VERSION ""

NS_ :

BS_:

BU_: CAMERA_ALL ALM_DX ALM_SX CAMERA_DEFAULT LOGBOX CAMERA_POS0 CAMERA_POS1 CAMERA_POS2 CAMERA_POS3 CAMERA_POS4 CAMERA_POS5 CAMERA_POS6 CAMERA_POS7 SVS RUR RUF RUC BC _TESTER BMS3_ADB BMS0_ADB BMS4_ADB BMS5_ADB BMS6_ADB

BO_ 2566698659 _BMS3_ADB_VEP_5: 8 BMS3_ADB
 SG_ BMS3_ADB_SLI_BattPack_StOfCharge : 0|16@1+ (0.0025,0) [0|1606375] "%"  LOGBOX
 SG_ BMS3_ADB_SLI_BattPack_Capacity : 16|16@1+ (1,0) [0|64255] "Ah"  LOGBOX
 SG_ BMS3_ADB_SLI_BattPack_Health : 32|8@1+ (0.5,0) [0|100] "%"  LOGBOX

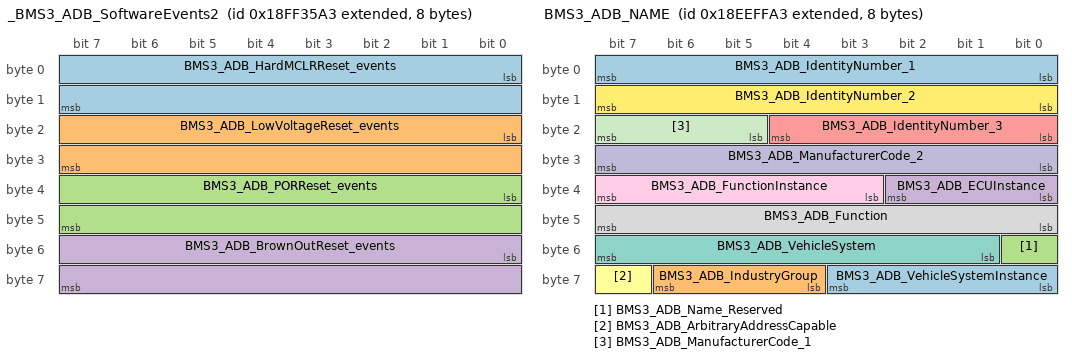
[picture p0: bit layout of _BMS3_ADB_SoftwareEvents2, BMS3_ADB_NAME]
BO_ 2566862243 _BMS3_ADB_SoftwareEvents2: 8 BMS3_ADB
 SG_ BMS3_ADB_HardMCLRReset_events : 0|16@1+ (1,0) [0|64255] "-"  LOGBOX
 SG_ BMS3_ADB_LowVoltageReset_events : 16|16@1+ (1,0) [0|64255] "-"  LOGBOX
 SG_ BMS3_ADB_PORReset_events : 32|16@1+ (1,0) [0|64255] "-"  LOGBOX
 SG_ BMS3_ADB_BrownOutReset_events : 48|16@1+ (1,0) [0|64255] "-"  LOGBOX

BO_ 2565799843 BMS3_ADB_NAME: 8 BMS3_ADB
 SG_ BMS3_ADB_VehicleSystemInstance : 56|4@1+ (1,0) [0|15] "-"  LOGBOX,BC
 SG_ BMS3_ADB_IndustryGroup : 60|3@1+ (1,0) [0|7] "-"  LOGBOX,BC
 SG_ BMS3_ADB_Name_Reserved : 48|1@1+ (1,0) [0|1] "-"  LOGBOX,BC
 SG_ BMS3_ADB_ECUInstance : 32|3@1+ (1,0) [0|7] "-"  LOGBOX,BC
 SG_ BMS3_ADB_IdentityNumber_3 : 16|5@1+ (1,0) [0|31] "-"  LOGBOX,BC
 SG_ BMS3_ADB_ArbitraryAddressCapable : 63|1@1+ (1,0) [0|1] "-"  LOGBOX,BC
 SG_ BMS3_ADB_VehicleSystem : 49|7@1+ (1,0) [0|127] "-"  LOGBOX,BC
 SG_ BMS3_ADB_Function : 40|8@1+ (1,0) [0|255] "-"  LOGBOX,BC
 SG_ BMS3_ADB_FunctionInstance : 35|5@1+ (1,0) [0|31] "-"  LOGBOX,BC
 SG_ BMS3_ADB_ManufacturerCode_2 : 24|8@1+ (1,0) [0|255] "-"  LOGBOX,BC
 SG_ BMS3_ADB_ManufacturerCode_1 : 21|3@1+ (1,0) [0|7] "-"  LOGBOX,BC
 SG_ BMS3_ADB_IdentityNumber_2 : 8|8@1+ (1,0) [0|255] "-"  LOGBOX,BC
 SG_ BMS3_ADB_IdentityNumber_1 : 0|8@1+ (1,0) [0|255] "-"  LOGBOX,BC

BO_ 2566849956 BMS4_ADB_BatterySummaryStatus: 8 BMS4_ADB
 SG_ BMS4_ADB_BatSumS_serial_number : 0|24@1+ (1,0) [0|16777214] "-"  BC,LOGBOX
 SG_ BMS4_ADB_BatSumS_Reserved_01 : 24|8@1+ (1,0) [0|255] "-"  LOGBOX
 SG_ BMS4_ADB_BatSumS_State_of_Charge : 32|8@1+ (1,0) [0|100] "%"  LOGBOX,BC
 SG_ BMS4_ADB_BatSumS_State_of_Health : 40|8@1+ (1,0) [0|2] "-"  LOGBOX,BC
 SG_ BMS4_ADB_BatSumS_Temp_Alarm : 48|2@1+ (1,0) [0|3] "-"  LOGBOX,BC
 SG_ BMS4_ADB_BatSumS_DischargeDis : 50|1@1+ (1,0) [0|1] "-"  LOGBOX,BC
 SG_ BMS4_ADB_BatSumS_ChargingDisable : 51|1@1+ (1,0) [0|1] "-"  LOGBOX,BC
 SG_ BMS4_ADB_BatSumS_HeaterEnabled : 52|1@1+ (1,0) [0|1] "-"  LOGBOX,BC
 SG_ BMS4_ADB_BatSumS_BypassEnabled : 53|1@1+ (1,0) [0|1] "-"  LOGBOX,BC
 SG_ BMS4_ADB_BatSumS_Voltage_Alarm : 56|1@1+ (1,0) [0|1] "-"  LOGBOX,BC
 SG_ BMS4_ADB_BatSumS_Reserved_04 : 54|2@1+ (1,0) [0|3] "-"  LOGBOX
 SG_ BMS4_ADB_BatSumS_Reserved_05 : 57|1@1+ (1,0) [0|1] "-"  LOGBOX,BC
 SG_ BMS4_ADB_BatSumS_Reserved_06 : 58|1@1+ (1,0) [0|1] "-"  LOGBOX
 SG_ BMS4_ADB_BatSumS_Reserved_07 : 59|1@1+ (1,0) [0|1] "-"  LOGBOX
 SG_ BMS4_ADB_BatSumS_Reserved_08 : 60|1@1+ (1,0) [0|1] "-"  LOGBOX
 SG_ BMS4_ADB_BatSumS_Reserved_09 : 61|1@1+ (1,0) [0|1] "-"  LOGBOX
 SG_ BMS4_ADB_BatSumS_Reserved_10 : 62|1@1+ (1,0) [0|1] "-"  LOGBOX
 SG_ BMS4_ADB_BatSumS_Reserved_11 : 63|1@1+ (1,0) [0|1] "-"  LOGBOX

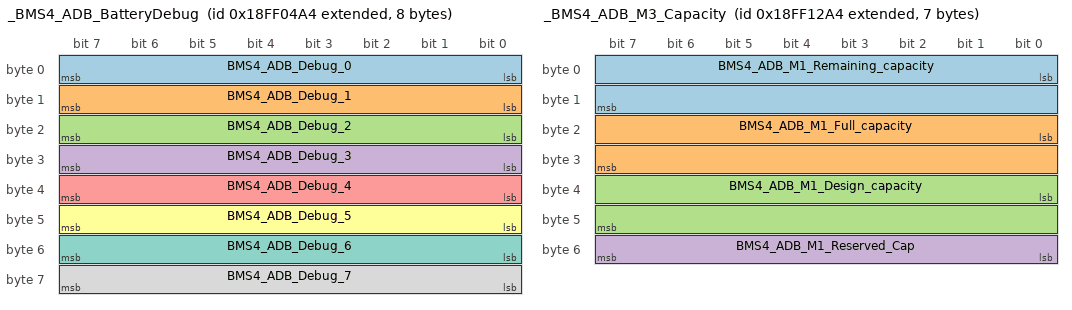
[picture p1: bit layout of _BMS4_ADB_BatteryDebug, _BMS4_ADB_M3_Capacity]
BO_ 2566849700 _BMS4_ADB_BatteryDebug: 8 BMS4_ADB
 SG_ BMS4_ADB_Debug_0 : 0|8@1+ (1,0) [0|255] "-"  LOGBOX
 SG_ BMS4_ADB_Debug_1 : 8|8@1+ (1,0) [0|255] "-"  LOGBOX
 SG_ BMS4_ADB_Debug_2 : 16|8@1+ (1,0) [0|255] "-"  LOGBOX
 SG_ BMS4_ADB_Debug_3 : 24|8@1+ (1,0) [0|255] "-"  LOGBOX
 SG_ BMS4_ADB_Debug_4 : 32|8@1+ (1,0) [0|255] "-"  LOGBOX
 SG_ BMS4_ADB_Debug_5 : 40|8@1+ (1,0) [0|255] "-"  LOGBOX
 SG_ BMS4_ADB_Debug_6 : 48|8@1+ (1,0) [0|255] "-"  LOGBOX
 SG_ BMS4_ADB_Debug_7 : 56|8@1+ (1,0) [0|255] "-"  LOGBOX

BO_ 2566853284 _BMS4_ADB_M3_Capacity: 7 BMS4_ADB
 SG_ BMS4_ADB_M1_Remaining_capacity : 0|16@1+ (0.01,0) [0|642.55] "Ah"  LOGBOX
 SG_ BMS4_ADB_M1_Full_capacity : 16|16@1+ (0.01,0) [0|642.55] "Ah"  LOGBOX
 SG_ BMS4_ADB_M1_Design_capacity : 32|16@1+ (0.01,0) [0|642.55] "Ah"  LOGBOX
 SG_ BMS4_ADB_M1_Reserved_Cap : 48|8@1+ (1,0) [255|255] "-"  LOGBOX

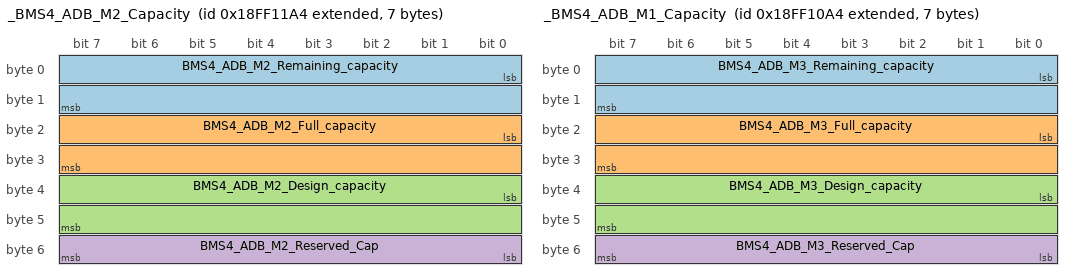
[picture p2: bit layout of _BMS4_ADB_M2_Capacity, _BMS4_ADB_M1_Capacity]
BO_ 2566853028 _BMS4_ADB_M2_Capacity: 7 BMS4_ADB
 SG_ BMS4_ADB_M2_Remaining_capacity : 0|16@1+ (0.01,0) [0|642.55] "Ah"  LOGBOX
 SG_ BMS4_ADB_M2_Full_capacity : 16|16@1+ (0.01,0) [0|642.55] "Ah"  LOGBOX
 SG_ BMS4_ADB_M2_Design_capacity : 32|16@1+ (0.01,0) [0|642.55] "Ah"  LOGBOX
 SG_ BMS4_ADB_M2_Reserved_Cap : 48|8@1+ (1,0) [255|255] "-"  LOGBOX

BO_ 2566852772 _BMS4_ADB_M1_Capacity: 7 BMS4_ADB
 SG_ BMS4_ADB_M3_Remaining_capacity : 0|16@1+ (0.01,0) [0|642.55] "Ah"  LOGBOX
 SG_ BMS4_ADB_M3_Full_capacity : 16|16@1+ (0.01,0) [0|642.55] "Ah"  LOGBOX
 SG_ BMS4_ADB_M3_Design_capacity : 32|16@1+ (0.01,0) [0|642.55] "Ah"  LOGBOX
 SG_ BMS4_ADB_M3_Reserved_Cap : 48|8@1+ (1,0) [255|255] "-"  LOGBOX

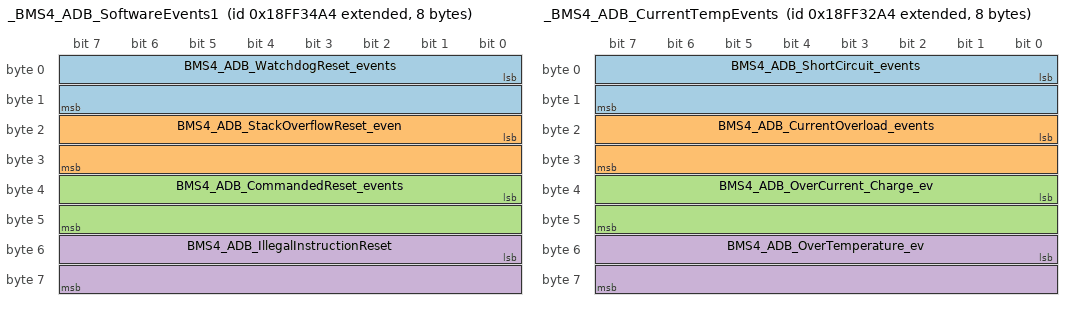
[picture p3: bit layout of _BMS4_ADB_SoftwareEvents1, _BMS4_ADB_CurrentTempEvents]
BO_ 2566861988 _BMS4_ADB_SoftwareEvents1: 8 BMS4_ADB
 SG_ BMS4_ADB_WatchdogReset_events : 0|16@1+ (1,0) [0|64255] "-"  LOGBOX
 SG_ BMS4_ADB_StackOverflowReset_even : 16|16@1+ (1,0) [0|64255] "-"  LOGBOX
 SG_ BMS4_ADB_CommandedReset_events : 32|16@1+ (1,0) [0|64255] "-"  LOGBOX
 SG_ BMS4_ADB_IllegalInstructionReset : 48|16@1+ (1,0) [0|64255] "-"  LOGBOX

BO_ 2566861732 _BMS4_ADB_VoltageEvents: 4 BMS4_ADB
 SG_ BMS4_ADB_OverVoltage_events : 0|16@1+ (1,0) [0|64255] "-"  LOGBOX
 SG_ BMS4_ADB_UnderVoltage_events : 16|16@1+ (1,0) [0|64255] "-"  LOGBOX

BO_ 2566861476 _BMS4_ADB_CurrentTempEvents: 8 BMS4_ADB
 SG_ BMS4_ADB_ShortCircuit_events : 0|16@1+ (1,0) [0|64255] "-"  LOGBOX
 SG_ BMS4_ADB_CurrentOverload_events : 16|16@1+ (1,0) [0|64255] "-"  LOGBOX
 SG_ BMS4_ADB_OverCurrent_Charge_ev : 32|16@1+ (1,0) [0|64255] "-"  LOGBOX
 SG_ BMS4_ADB_OverTemperature_ev : 48|16@1+ (1,0) [0|64255] "-"  LOGBOX

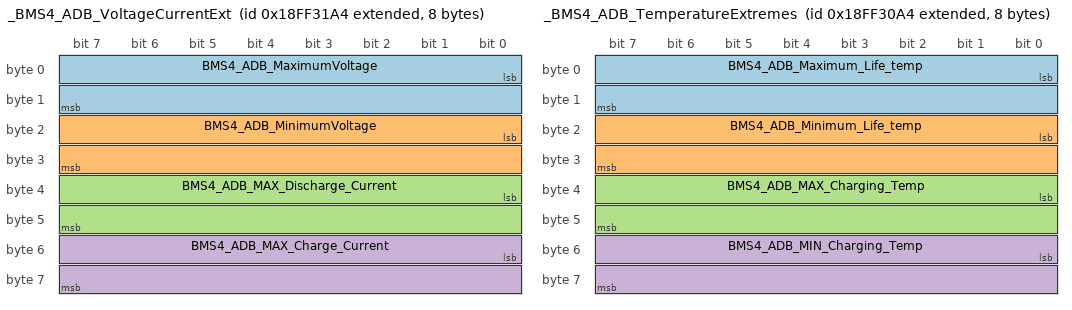
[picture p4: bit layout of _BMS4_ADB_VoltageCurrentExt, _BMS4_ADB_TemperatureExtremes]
BO_ 2566861220 _BMS4_ADB_VoltageCurrentExt: 8 BMS4_ADB
 SG_ BMS4_ADB_MaximumVoltage : 0|16@1+ (0.001,0) [0|64255] "V"  LOGBOX
 SG_ BMS4_ADB_MinimumVoltage : 16|16@1+ (0.001,0) [0|64255] "V"  LOGBOX
 SG_ BMS4_ADB_MAX_Discharge_Current : 32|16@1+ (0.1,0) [0|6425.5] "A"  LOGBOX
 SG_ BMS4_ADB_MAX_Charge_Current : 48|16@1+ (0.1,0) [0|6425.5] "A"  LOGBOX

BO_ 2566860964 _BMS4_ADB_TemperatureExtremes: 8 BMS4_ADB
 SG_ BMS4_ADB_Maximum_Life_temp : 0|16@1+ (0.1,-100) [-100|200] "°C"  LOGBOX
 SG_ BMS4_ADB_Minimum_Life_temp : 16|16@1+ (0.1,-100) [-100|200] "°C"  LOGBOX
 SG_ BMS4_ADB_MAX_Charging_Temp : 32|16@1+ (0.1,-100) [-100|200] "°C"  LOGBOX
 SG_ BMS4_ADB_MIN_Charging_Temp : 48|16@1+ (0.1,-100) [-100|200] "°C"  LOGBOX

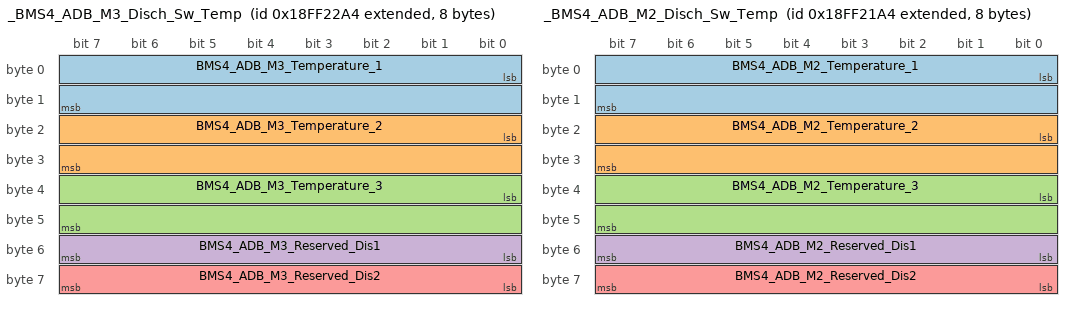
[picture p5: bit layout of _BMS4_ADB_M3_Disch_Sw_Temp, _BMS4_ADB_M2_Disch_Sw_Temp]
BO_ 2566857380 _BMS4_ADB_M3_Disch_Sw_Temp: 8 BMS4_ADB
 SG_ BMS4_ADB_M3_Temperature_1 : 0|16@1+ (0.1,-100) [-100|200] "°C"  LOGBOX
 SG_ BMS4_ADB_M3_Temperature_2 : 16|16@1+ (0.1,-100) [-100|200] "°C"  LOGBOX
 SG_ BMS4_ADB_M3_Temperature_3 : 32|16@1+ (0.1,-100) [-100|200] "°C"  LOGBOX
 SG_ BMS4_ADB_M3_Reserved_Dis1 : 48|8@1+ (1,0) [255|255] "-"  LOGBOX
 SG_ BMS4_ADB_M3_Reserved_Dis2 : 56|8@1+ (1,0) [255|255] "-"  LOGBOX

BO_ 2566857124 _BMS4_ADB_M2_Disch_Sw_Temp: 8 BMS4_ADB
 SG_ BMS4_ADB_M2_Temperature_1 : 0|16@1+ (0.1,-100) [-100|200] "°C"  LOGBOX
 SG_ BMS4_ADB_M2_Temperature_2 : 16|16@1+ (0.1,-100) [-100|200] "°C"  LOGBOX
 SG_ BMS4_ADB_M2_Temperature_3 : 32|16@1+ (0.1,-100) [-100|200] "°C"  LOGBOX
 SG_ BMS4_ADB_M2_Reserved_Dis1 : 48|8@1+ (1,0) [255|255] "-"  LOGBOX
 SG_ BMS4_ADB_M2_Reserved_Dis2 : 56|8@1+ (1,0) [255|255] "-"  LOGBOX

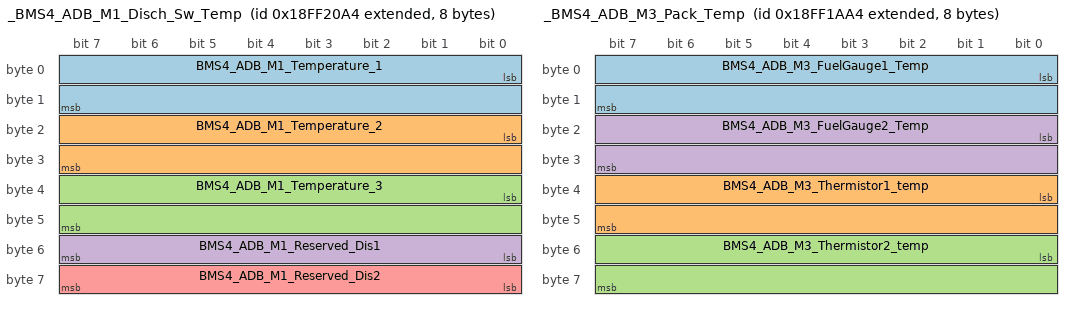
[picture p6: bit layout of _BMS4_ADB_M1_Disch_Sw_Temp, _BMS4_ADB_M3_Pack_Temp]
BO_ 2566856868 _BMS4_ADB_M1_Disch_Sw_Temp: 8 BMS4_ADB
 SG_ BMS4_ADB_M1_Temperature_1 : 0|16@1+ (0.1,-100) [-100|200] "°C"  LOGBOX
 SG_ BMS4_ADB_M1_Temperature_2 : 16|16@1+ (0.1,-100) [-100|200] "°C"  LOGBOX
 SG_ BMS4_ADB_M1_Temperature_3 : 32|16@1+ (0.1,-100) [-100|200] "°C"  LOGBOX
 SG_ BMS4_ADB_M1_Reserved_Dis1 : 48|8@1+ (1,0) [255|255] "-"  LOGBOX
 SG_ BMS4_ADB_M1_Reserved_Dis2 : 56|8@1+ (1,0) [255|255] "-"  LOGBOX

BO_ 2566855332 _BMS4_ADB_M3_Pack_Temp: 8 BMS4_ADB
 SG_ BMS4_ADB_M3_FuelGauge1_Temp : 0|16@1+ (0.1,-100) [-100|200] "°C"  LOGBOX
 SG_ BMS4_ADB_M3_Thermistor1_temp : 32|16@1+ (0.1,-100) [-100|200] "-"  LOGBOX
 SG_ BMS4_ADB_M3_Thermistor2_temp : 48|16@1+ (0.1,-100) [-100|200] "-"  LOGBOX
 SG_ BMS4_ADB_M3_FuelGauge2_Temp : 16|16@1+ (0.1,-100) [-100|200] "°C"  LOGBOX

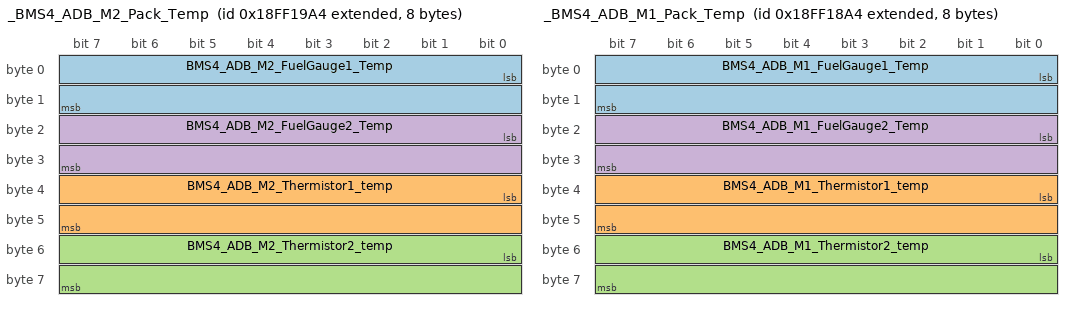
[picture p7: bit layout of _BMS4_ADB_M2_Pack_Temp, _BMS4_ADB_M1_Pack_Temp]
BO_ 2566855076 _BMS4_ADB_M2_Pack_Temp: 8 BMS4_ADB
 SG_ BMS4_ADB_M2_FuelGauge1_Temp : 0|16@1+ (0.1,-100) [-100|200] "°C"  LOGBOX
 SG_ BMS4_ADB_M2_Thermistor1_temp : 32|16@1+ (0.1,-100) [-100|200] "-"  LOGBOX
 SG_ BMS4_ADB_M2_Thermistor2_temp : 48|16@1+ (0.1,-100) [-100|200] "-"  LOGBOX
 SG_ BMS4_ADB_M2_FuelGauge2_Temp : 16|16@1+ (0.1,-100) [-100|200] "°C"  LOGBOX

BO_ 2566854820 _BMS4_ADB_M1_Pack_Temp: 8 BMS4_ADB
 SG_ BMS4_ADB_M1_FuelGauge1_Temp : 0|16@1+ (0.1,-100) [-100|200] "°C"  LOGBOX
 SG_ BMS4_ADB_M1_Thermistor1_temp : 32|16@1+ (0.1,-100) [-100|200] "-"  LOGBOX
 SG_ BMS4_ADB_M1_Thermistor2_temp : 48|16@1+ (0.1,-100) [-100|200] "-"  LOGBOX
 SG_ BMS4_ADB_M1_FuelGauge2_Temp : 16|16@1+ (0.1,-100) [-100|200] "°C"  LOGBOX

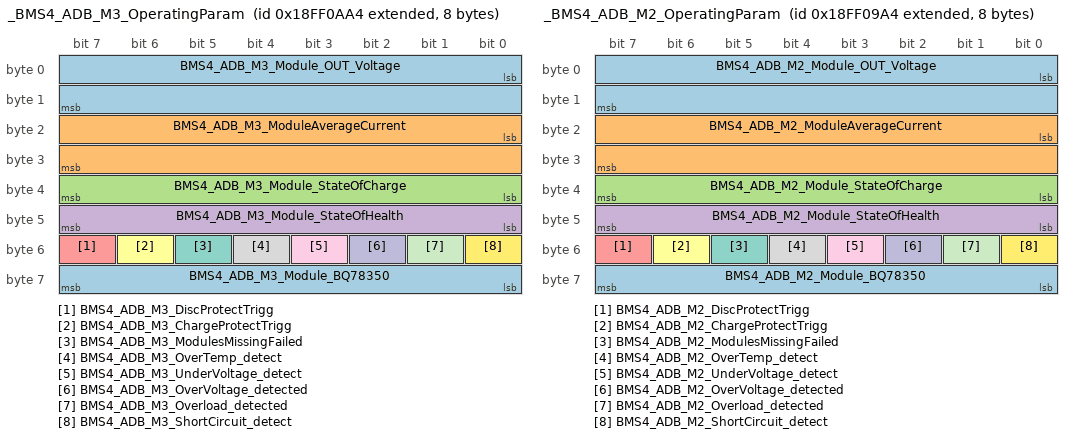
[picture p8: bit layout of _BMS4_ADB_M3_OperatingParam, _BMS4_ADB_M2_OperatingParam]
BO_ 2566851236 _BMS4_ADB_M3_OperatingParam: 8 BMS4_ADB
 SG_ BMS4_ADB_M3_Module_OUT_Voltage : 0|16@1+ (0.001,0) [0|64255] "V"  LOGBOX
 SG_ BMS4_ADB_M3_ModuleAverageCurrent : 16|16@1+ (0.1,-5500) [-5500|925.5] "A"  LOGBOX
 SG_ BMS4_ADB_M3_Module_StateOfCharge : 32|8@1+ (1,0) [0|100] "%"  LOGBOX
 SG_ BMS4_ADB_M3_Module_StateOfHealth : 40|8@1+ (1,0) [0|2] "-"  LOGBOX
 SG_ BMS4_ADB_M3_DiscProtectTrigg : 55|1@1+ (1,0) [0|1] "-"  LOGBOX
 SG_ BMS4_ADB_M3_ChargeProtectTrigg : 54|1@1+ (1,0) [0|1] "-"  LOGBOX
 SG_ BMS4_ADB_M3_ModulesMissingFailed : 53|1@1+ (1,0) [0|1] "-"  LOGBOX
 SG_ BMS4_ADB_M3_OverTemp_detect : 52|1@1+ (1,0) [0|1] "-"  LOGBOX
 SG_ BMS4_ADB_M3_UnderVoltage_detect : 51|1@1+ (1,0) [0|1] "-"  LOGBOX
 SG_ BMS4_ADB_M3_OverVoltage_detected : 50|1@1+ (1,0) [0|1] "-"  LOGBOX
 SG_ BMS4_ADB_M3_Overload_detected : 49|1@1+ (1,0) [0|1] "-"  LOGBOX
 SG_ BMS4_ADB_M3_ShortCircuit_detect : 48|1@1+ (1,0) [0|1] "-"  LOGBOX
 SG_ BMS4_ADB_M3_Module_BQ78350 : 56|8@1+ (1,0) [0|2] "-"  LOGBOX

BO_ 2566850980 _BMS4_ADB_M2_OperatingParam: 8 BMS4_ADB
 SG_ BMS4_ADB_M2_Module_OUT_Voltage : 0|16@1+ (0.001,0) [0|64255] "V"  LOGBOX
 SG_ BMS4_ADB_M2_ModuleAverageCurrent : 16|16@1+ (0.1,-5500) [-5500|925.5] "A"  LOGBOX
 SG_ BMS4_ADB_M2_Module_StateOfCharge : 32|8@1+ (1,0) [0|100] "%"  LOGBOX
 SG_ BMS4_ADB_M2_Module_StateOfHealth : 40|8@1+ (1,0) [0|2] "-"  LOGBOX
 SG_ BMS4_ADB_M2_DiscProtectTrigg : 55|1@1+ (1,0) [0|1] "-"  LOGBOX
 SG_ BMS4_ADB_M2_ChargeProtectTrigg : 54|1@1+ (1,0) [0|1] "-"  LOGBOX
 SG_ BMS4_ADB_M2_ModulesMissingFailed : 53|1@1+ (1,0) [0|1] "-"  LOGBOX
 SG_ BMS4_ADB_M2_OverTemp_detect : 52|1@1+ (1,0) [0|1] "-"  LOGBOX
 SG_ BMS4_ADB_M2_UnderVoltage_detect : 51|1@1+ (1,0) [0|1] "-"  LOGBOX
 SG_ BMS4_ADB_M2_OverVoltage_detected : 50|1@1+ (1,0) [0|1] "-"  LOGBOX
 SG_ BMS4_ADB_M2_Overload_detected : 49|1@1+ (1,0) [0|1] "-"  LOGBOX
 SG_ BMS4_ADB_M2_ShortCircuit_detect : 48|1@1+ (1,0) [0|1] "-"  LOGBOX
 SG_ BMS4_ADB_M2_Module_BQ78350 : 56|8@1+ (1,0) [0|2] "-"  LOGBOX

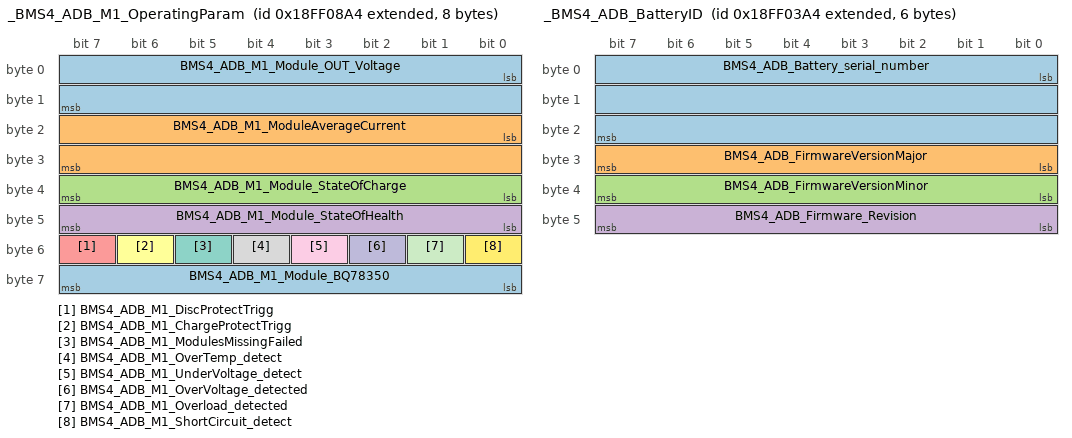
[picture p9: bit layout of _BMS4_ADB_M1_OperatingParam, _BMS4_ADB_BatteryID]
BO_ 2566850724 _BMS4_ADB_M1_OperatingParam: 8 BMS4_ADB
 SG_ BMS4_ADB_M1_Module_OUT_Voltage : 0|16@1+ (0.001,0) [0|64255] "V"  LOGBOX
 SG_ BMS4_ADB_M1_ModuleAverageCurrent : 16|16@1+ (0.1,-5500) [-5500|925.5] "A"  LOGBOX
 SG_ BMS4_ADB_M1_Module_StateOfCharge : 32|8@1+ (1,0) [0|100] "%"  LOGBOX
 SG_ BMS4_ADB_M1_Module_StateOfHealth : 40|8@1+ (1,0) [0|2] "-"  LOGBOX
 SG_ BMS4_ADB_M1_DiscProtectTrigg : 55|1@1+ (1,0) [0|1] "-"  LOGBOX
 SG_ BMS4_ADB_M1_ChargeProtectTrigg : 54|1@1+ (1,0) [0|1] "-"  LOGBOX
 SG_ BMS4_ADB_M1_ModulesMissingFailed : 53|1@1+ (1,0) [0|1] "-"  LOGBOX
 SG_ BMS4_ADB_M1_OverTemp_detect : 52|1@1+ (1,0) [0|1] "-"  LOGBOX
 SG_ BMS4_ADB_M1_UnderVoltage_detect : 51|1@1+ (1,0) [0|1] "-"  LOGBOX
 SG_ BMS4_ADB_M1_OverVoltage_detected : 50|1@1+ (1,0) [0|1] "-"  LOGBOX
 SG_ BMS4_ADB_M1_Overload_detected : 49|1@1+ (1,0) [0|1] "-"  LOGBOX
 SG_ BMS4_ADB_M1_ShortCircuit_detect : 48|1@1+ (1,0) [0|1] "-"  LOGBOX
 SG_ BMS4_ADB_M1_Module_BQ78350 : 56|8@1+ (1,0) [0|2] "-"  LOGBOX

BO_ 2566849444 _BMS4_ADB_BatteryID: 6 BMS4_ADB
 SG_ BMS4_ADB_Battery_serial_number : 0|24@1+ (1,0) [0|16777214] "-"  LOGBOX
 SG_ BMS4_ADB_FirmwareVersionMajor : 24|8@1+ (1,0) [0|255] "-"  LOGBOX
 SG_ BMS4_ADB_FirmwareVersionMinor : 32|8@1+ (1,0) [0|255] "-"  LOGBOX
 SG_ BMS4_ADB_Firmware_Revision : 40|8@1+ (1,0) [0|255] "-"  LOGBOX

BO_ 2566849188 _BMS4_ADB_BatteryTemperature: 6 BMS4_ADB
 SG_ BMS4_ADB_Maximum_Temperature : 0|16@1+ (0.1,-100) [-100|200] "°C"  LOGBOX
 SG_ BMS4_ADB_Minimum_Temperature : 16|16@1+ (0.1,-100) [-100|200] "°C"  LOGBOX
 SG_ BMS4_ADB_Average_Temperature : 32|16@1+ (0.1,-100) [-100|200] "°C"  LOGBOX

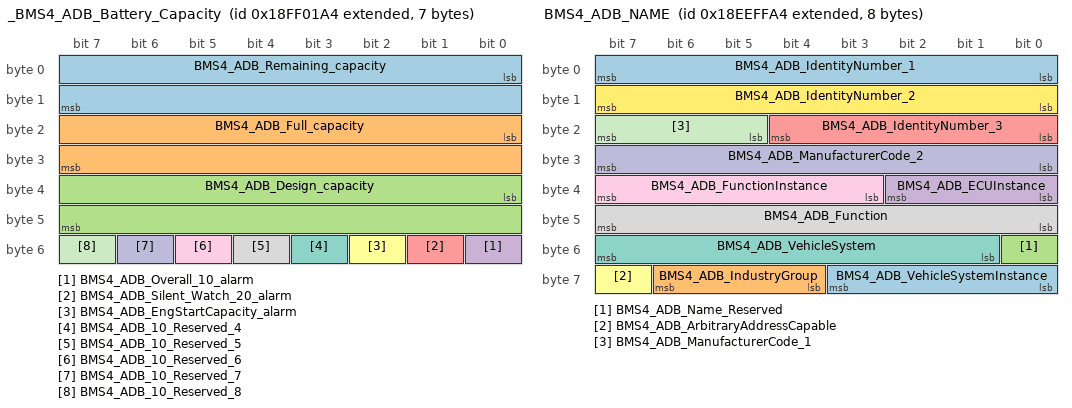
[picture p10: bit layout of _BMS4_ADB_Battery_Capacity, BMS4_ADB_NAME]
BO_ 2566848932 _BMS4_ADB_Battery_Capacity: 7 BMS4_ADB
 SG_ BMS4_ADB_Remaining_capacity : 0|16@1+ (0.01,0) [0|642.55] "Ah"  LOGBOX
 SG_ BMS4_ADB_Full_capacity : 16|16@1+ (0.01,0) [0|642.55] "Ah"  LOGBOX
 SG_ BMS4_ADB_Design_capacity : 32|16@1+ (0.01,0) [0|642.55] "Ah"  LOGBOX
 SG_ BMS4_ADB_Overall_10_alarm : 48|1@1+ (1,0) [0|1] "-"  LOGBOX
 SG_ BMS4_ADB_Silent_Watch_20_alarm : 49|1@1+ (1,0) [0|1] "-"  LOGBOX
 SG_ BMS4_ADB_EngStartCapacity_alarm : 50|1@1+ (1,0) [0|1] "-"  LOGBOX
 SG_ BMS4_ADB_10_Reserved_4 : 51|1@1+ (1,0) [0|0] "-"  LOGBOX
 SG_ BMS4_ADB_10_Reserved_5 : 52|1@1+ (1,0) [0|0] "-"  LOGBOX
 SG_ BMS4_ADB_10_Reserved_6 : 53|1@1+ (1,0) [0|0] "-"  LOGBOX
 SG_ BMS4_ADB_10_Reserved_7 : 54|1@1+ (1,0) [0|0] "-"  LOGBOX
 SG_ BMS4_ADB_10_Reserved_8 : 55|1@1+ (1,0) [0|0] "-"  LOGBOX

BO_ 2566848676 _BMS4_ADB_BatteryOperatingParam: 8 BMS4_ADB
 SG_ BMS4_ADB_Batt_OUT_Voltage : 0|16@1+ (0.001,0) [0|64255] "V"  LOGBOX
 SG_ BMS4_ADB_Batt_Average_Current : 16|16@1+ (0.1,-5500) [-5500|925.5] "A"  LOGBOX
 SG_ BMS4_ADB_Batt_StsOfCharge : 32|8@1+ (1,0) [0|100] "%"  LOGBOX
 SG_ BMS4_ADB_Batt_StsOfHealth : 40|8@1+ (1,0) [0|2] "-"  LOGBOX
 SG_ BMS4_ADB_Batt_PS8_discharge_prot : 55|1@1+ (1,0) [0|1] "-"  LOGBOX
 SG_ BMS4_ADB_Batt_PS7_charge_prot : 54|1@1+ (1,0) [0|1] "-"  LOGBOX
 SG_ BMS4_ADB_Batt_PS6_mod_failed : 53|1@1+ (1,0) [0|1] "-"  LOGBOX
 SG_ BMS4_ADB_Batt_PS5_over_temp : 52|1@1+ (1,0) [0|1] "-"  LOGBOX
 SG_ BMS4_ADB_Batt_PS4_under_voltage : 51|1@1+ (1,0) [0|1] "-"  LOGBOX
 SG_ BMS4_ADB_Batt_PS3_over_voltage : 50|1@1+ (1,0) [0|1] "-"  LOGBOX
 SG_ BMS4_ADB_Batt_PS2_overload : 49|1@1+ (1,0) [0|1] "-"  LOGBOX
 SG_ BMS4_ADB_Batt_PS1_short_circuit : 48|1@1+ (1,0) [0|1] "-"  LOGBOX
 SG_ BMS4_ADB_Batt_OS_8_sleep_mode : 63|1@1+ (1,0) [0|1] "-"  LOGBOX
 SG_ BMS4_ADB_Batt_OS_7_emerg_used : 62|1@1+ (1,0) [0|1] "-"  LOGBOX
 SG_ BMS4_ADB_Batt_OS_6_emergency : 61|1@1+ (1,0) [0|1] "-"  LOGBOX
 SG_ BMS4_ADB_Batt_OS_45_charge_level : 59|2@1+ (1,0) [0|3] "-"  LOGBOX
 SG_ BMS4_ADB_Batt_OS_3_charge_cont : 58|1@1+ (1,0) [0|1] "-"  LOGBOX
 SG_ BMS4_ADB_Batt_OS_2_heater_cont : 57|1@1+ (1,0) [0|1] "-"  LOGBOX
 SG_ BMS4_ADB_Batt_OS_1_master_prot : 56|1@1+ (1,0) [0|1] "-"  LOGBOX

BO_ 2566804132 _BMS4_ADB_VEP_3: 8 BMS4_ADB
 SG_ _nu_BMS4_ADB_AlternatorCurrent : 0|16@1+ (0.05,-1600) [-1600|1612.75] "A"  LOGBOX
 SG_ BMS4_ADB_NetBattery_Current : 16|16@1+ (0.05,-1600) [-1600|1612.75] "A"  LOGBOX

BO_ 2566803620 _BMS4_ADB_Battery_1_Temp: 8 BMS4_ADB
 SG_ BMS4_ADB_Battery1_Temperature : 0|8@1+ (1,-40) [-40|210] "°C"  LOGBOX
 SG_ _nu_BMS4_ADB_Battery2_Temp : 8|8@1+ (1,-40) [-40|210] "°C"  LOGBOX

BO_ 2566698660 _BMS4_ADB_VEP_5: 8 BMS4_ADB
 SG_ BMS4_ADB_SLI_BattPack_StOfCharge : 0|16@1+ (0.0025,0) [0|1606375] "%"  LOGBOX
 SG_ BMS4_ADB_SLI_BattPack_Capacity : 16|16@1+ (1,0) [0|64255] "Ah"  LOGBOX
 SG_ BMS4_ADB_SLI_BattPack_Health : 32|8@1+ (0.5,0) [0|100] "%"  LOGBOX

BO_ 2566862244 _BMS4_ADB_SoftwareEvents2: 8 BMS4_ADB
 SG_ BMS4_ADB_HardMCLRReset_events : 0|16@1+ (1,0) [0|64255] "-"  LOGBOX
 SG_ BMS4_ADB_LowVoltageReset_events : 16|16@1+ (1,0) [0|64255] "-"  LOGBOX
 SG_ BMS4_ADB_PORReset_events : 32|16@1+ (1,0) [0|64255] "-"  LOGBOX
 SG_ BMS4_ADB_BrownOutReset_events : 48|16@1+ (1,0) [0|64255] "-"  LOGBOX

BO_ 2565799844 BMS4_ADB_NAME: 8 BMS4_ADB
 SG_ BMS4_ADB_VehicleSystemInstance : 56|4@1+ (1,0) [0|15] "-"  LOGBOX,BC
 SG_ BMS4_ADB_IndustryGroup : 60|3@1+ (1,0) [0|7] "-"  LOGBOX,BC
 SG_ BMS4_ADB_Name_Reserved : 48|1@1+ (1,0) [0|1] "-"  LOGBOX,BC
 SG_ BMS4_ADB_ECUInstance : 32|3@1+ (1,0) [0|7] "-"  LOGBOX,BC
 SG_ BMS4_ADB_IdentityNumber_3 : 16|5@1+ (1,0) [0|31] "-"  LOGBOX,BC
 SG_ BMS4_ADB_ArbitraryAddressCapable : 63|1@1+ (1,0) [0|1] "-"  LOGBOX,BC
 SG_ BMS4_ADB_VehicleSystem : 49|7@1+ (1,0) [0|127] "-"  LOGBOX,BC
 SG_ BMS4_ADB_Function : 40|8@1+ (1,0) [0|255] "-"  LOGBOX,BC
 SG_ BMS4_ADB_FunctionInstance : 35|5@1+ (1,0) [0|31] "-"  LOGBOX,BC
 SG_ BMS4_ADB_ManufacturerCode_2 : 24|8@1+ (1,0) [0|255] "-"  LOGBOX,BC
 SG_ BMS4_ADB_ManufacturerCode_1 : 21|3@1+ (1,0) [0|7] "-"  LOGBOX,BC
 SG_ BMS4_ADB_IdentityNumber_2 : 8|8@1+ (1,0) [0|255] "-"  LOGBOX,BC
 SG_ BMS4_ADB_IdentityNumber_1 : 0|8@1+ (1,0) [0|255] "-"  LOGBOX,BC

BO_ 2566849957 BMS5_ADB_BatterySummaryStatus: 8 BMS5_ADB
 SG_ BMS5_ADB_BatSumS_serial_number : 0|24@1+ (1,0) [0|16777214] "-"  BC,LOGBOX
 SG_ BMS5_ADB_BatSumS_Reserved_01 : 24|8@1+ (1,0) [0|255] "-"  LOGBOX
 SG_ BMS5_ADB_BatSumS_State_of_Charge : 32|8@1+ (1,0) [0|100] "%"  LOGBOX,BC
 SG_ BMS5_ADB_BatSumS_State_of_Health : 40|8@1+ (1,0) [0|2] "-"  LOGBOX,BC
 SG_ BMS5_ADB_BatSumS_Temp_Alarm : 48|2@1+ (1,0) [0|3] "-"  LOGBOX,BC
 SG_ BMS5_ADB_BatSumS_DischargeDis : 50|1@1+ (1,0) [0|1] "-"  LOGBOX,BC
 SG_ BMS5_ADB_BatSumS_ChargingDisable : 51|1@1+ (1,0) [0|1] "-"  LOGBOX,BC
 SG_ BMS5_ADB_BatSumS_HeaterEnabled : 52|1@1+ (1,0) [0|1] "-"  LOGBOX,BC
 SG_ BMS5_ADB_BatSumS_BypassEnabled : 53|1@1+ (1,0) [0|1] "-"  LOGBOX,BC
 SG_ BMS5_ADB_BatSumS_Voltage_Alarm : 56|1@1+ (1,0) [0|1] "-"  LOGBOX,BC
 SG_ BMS5_ADB_BatSumS_Reserved_04 : 54|2@1+ (1,0) [0|3] "-"  LOGBOX
 SG_ BMS5_ADB_BatSumS_Reserved_05 : 57|1@1+ (1,0) [0|1] "-"  LOGBOX,BC
 SG_ BMS5_ADB_BatSumS_Reserved_06 : 58|1@1+ (1,0) [0|1] "-"  LOGBOX
 SG_ BMS5_ADB_BatSumS_Reserved_07 : 59|1@1+ (1,0) [0|1] "-"  LOGBOX
 SG_ BMS5_ADB_BatSumS_Reserved_08 : 60|1@1+ (1,0) [0|1] "-"  LOGBOX
 SG_ BMS5_ADB_BatSumS_Reserved_09 : 61|1@1+ (1,0) [0|1] "-"  LOGBOX
 SG_ BMS5_ADB_BatSumS_Reserved_10 : 62|1@1+ (1,0) [0|1] "-"  LOGBOX
 SG_ BMS5_ADB_BatSumS_Reserved_11 : 63|1@1+ (1,0) [0|1] "-"  LOGBOX

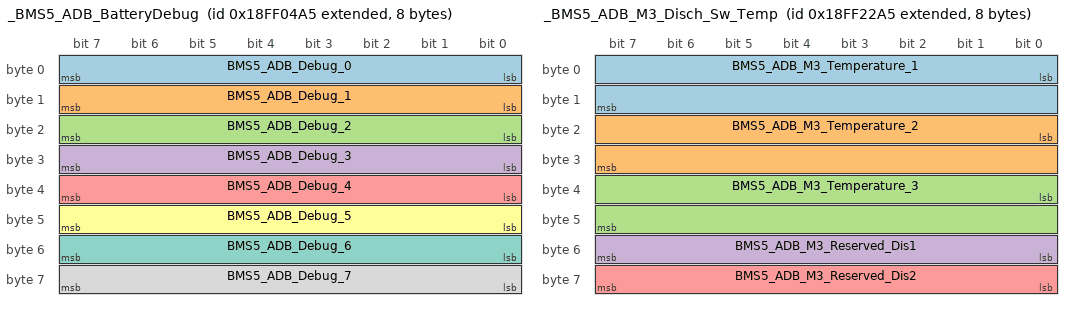
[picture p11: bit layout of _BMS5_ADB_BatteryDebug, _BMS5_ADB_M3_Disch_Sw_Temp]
BO_ 2566849701 _BMS5_ADB_BatteryDebug: 8 BMS5_ADB
 SG_ BMS5_ADB_Debug_0 : 0|8@1+ (1,0) [0|255] "-"  LOGBOX
 SG_ BMS5_ADB_Debug_1 : 8|8@1+ (1,0) [0|255] "-"  LOGBOX
 SG_ BMS5_ADB_Debug_2 : 16|8@1+ (1,0) [0|255] "-"  LOGBOX
 SG_ BMS5_ADB_Debug_3 : 24|8@1+ (1,0) [0|255] "-"  LOGBOX
 SG_ BMS5_ADB_Debug_4 : 32|8@1+ (1,0) [0|255] "-"  LOGBOX
 SG_ BMS5_ADB_Debug_5 : 40|8@1+ (1,0) [0|255] "-"  LOGBOX
 SG_ BMS5_ADB_Debug_6 : 48|8@1+ (1,0) [0|255] "-"  LOGBOX
 SG_ BMS5_ADB_Debug_7 : 56|8@1+ (1,0) [0|255] "-"  LOGBOX

BO_ 2566853285 _BMS5_ADB_M3_Capacity: 7 BMS5_ADB
 SG_ BMS5_ADB_M1_Remaining_capacity : 0|16@1+ (0.01,0) [0|642.55] "Ah"  LOGBOX
 SG_ BMS5_ADB_M1_Full_capacity : 16|16@1+ (0.01,0) [0|642.55] "Ah"  LOGBOX
 SG_ BMS5_ADB_M1_Design_capacity : 32|16@1+ (0.01,0) [0|642.55] "Ah"  LOGBOX
 SG_ BMS5_ADB_M1_Reserved_Cap : 48|8@1+ (1,0) [255|255] "-"  LOGBOX

BO_ 2566853029 _BMS5_ADB_M2_Capacity: 7 BMS5_ADB
 SG_ BMS5_ADB_M2_Remaining_capacity : 0|16@1+ (0.01,0) [0|642.55] "Ah"  LOGBOX
 SG_ BMS5_ADB_M2_Full_capacity : 16|16@1+ (0.01,0) [0|642.55] "Ah"  LOGBOX
 SG_ BMS5_ADB_M2_Design_capacity : 32|16@1+ (0.01,0) [0|642.55] "Ah"  LOGBOX
 SG_ BMS5_ADB_M2_Reserved_Cap : 48|8@1+ (1,0) [255|255] "-"  LOGBOX

BO_ 2566852773 _BMS5_ADB_M1_Capacity: 7 BMS5_ADB
 SG_ BMS5_ADB_M3_Remaining_capacity : 0|16@1+ (0.01,0) [0|642.55] "Ah"  LOGBOX
 SG_ BMS5_ADB_M3_Full_capacity : 16|16@1+ (0.01,0) [0|642.55] "Ah"  LOGBOX
 SG_ BMS5_ADB_M3_Design_capacity : 32|16@1+ (0.01,0) [0|642.55] "Ah"  LOGBOX
 SG_ BMS5_ADB_M3_Reserved_Cap : 48|8@1+ (1,0) [255|255] "-"  LOGBOX

BO_ 2566861989 _BMS5_ADB_SoftwareEvents1: 8 BMS5_ADB
 SG_ BMS5_ADB_WatchdogReset_events : 0|16@1+ (1,0) [0|64255] "-"  LOGBOX
 SG_ BMS5_ADB_StackOverflowReset_even : 16|16@1+ (1,0) [0|64255] "-"  LOGBOX
 SG_ BMS5_ADB_CommandedReset_events : 32|16@1+ (1,0) [0|64255] "-"  LOGBOX
 SG_ BMS5_ADB_IllegalInstructionReset : 48|16@1+ (1,0) [0|64255] "-"  LOGBOX

BO_ 2566861733 _BMS5_ADB_VoltageEvents: 4 BMS5_ADB
 SG_ BMS5_ADB_OverVoltage_events : 0|16@1+ (1,0) [0|64255] "-"  LOGBOX
 SG_ BMS5_ADB_UnderVoltage_events : 16|16@1+ (1,0) [0|64255] "-"  LOGBOX

BO_ 2566861477 _BMS5_ADB_CurrentTempEvents: 8 BMS5_ADB
 SG_ BMS5_ADB_ShortCircuit_events : 0|16@1+ (1,0) [0|64255] "-"  LOGBOX
 SG_ BMS5_ADB_CurrentOverload_events : 16|16@1+ (1,0) [0|64255] "-"  LOGBOX
 SG_ BMS5_ADB_OverCurrent_Charge_ev : 32|16@1+ (1,0) [0|64255] "-"  LOGBOX
 SG_ BMS5_ADB_OverTemperature_ev : 48|16@1+ (1,0) [0|64255] "-"  LOGBOX

BO_ 2566861221 _BMS5_ADB_VoltageCurrentExt: 8 BMS5_ADB
 SG_ BMS5_ADB_MaximumVoltage : 0|16@1+ (0.001,0) [0|64255] "V"  LOGBOX
 SG_ BMS5_ADB_MinimumVoltage : 16|16@1+ (0.001,0) [0|64255] "V"  LOGBOX
 SG_ BMS5_ADB_MAX_Discharge_Current : 32|16@1+ (0.1,0) [0|6425.5] "A"  LOGBOX
 SG_ BMS5_ADB_MAX_Charge_Current : 48|16@1+ (0.1,0) [0|6425.5] "A"  LOGBOX

BO_ 2566860965 _BMS5_ADB_TemperatureExtremes: 8 BMS5_ADB
 SG_ BMS5_ADB_Maximum_Life_temp : 0|16@1+ (0.1,-100) [-100|200] "°C"  LOGBOX
 SG_ BMS5_ADB_Minimum_Life_temp : 16|16@1+ (0.1,-100) [-100|200] "°C"  LOGBOX
 SG_ BMS5_ADB_MAX_Charging_Temp : 32|16@1+ (0.1,-100) [-100|200] "°C"  LOGBOX
 SG_ BMS5_ADB_MIN_Charging_Temp : 48|16@1+ (0.1,-100) [-100|200] "°C"  LOGBOX

BO_ 2566857381 _BMS5_ADB_M3_Disch_Sw_Temp: 8 BMS5_ADB
 SG_ BMS5_ADB_M3_Temperature_1 : 0|16@1+ (0.1,-100) [-100|200] "°C"  LOGBOX
 SG_ BMS5_ADB_M3_Temperature_2 : 16|16@1+ (0.1,-100) [-100|200] "°C"  LOGBOX
 SG_ BMS5_ADB_M3_Temperature_3 : 32|16@1+ (0.1,-100) [-100|200] "°C"  LOGBOX
 SG_ BMS5_ADB_M3_Reserved_Dis1 : 48|8@1+ (1,0) [255|255] "-"  LOGBOX
 SG_ BMS5_ADB_M3_Reserved_Dis2 : 56|8@1+ (1,0) [255|255] "-"  LOGBOX

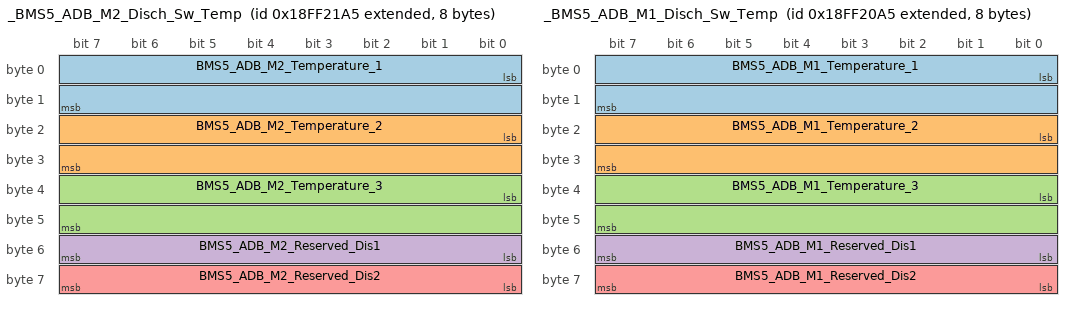
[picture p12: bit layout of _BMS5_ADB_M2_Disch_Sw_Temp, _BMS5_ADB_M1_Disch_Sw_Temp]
BO_ 2566857125 _BMS5_ADB_M2_Disch_Sw_Temp: 8 BMS5_ADB
 SG_ BMS5_ADB_M2_Temperature_1 : 0|16@1+ (0.1,-100) [-100|200] "°C"  LOGBOX
 SG_ BMS5_ADB_M2_Temperature_2 : 16|16@1+ (0.1,-100) [-100|200] "°C"  LOGBOX
 SG_ BMS5_ADB_M2_Temperature_3 : 32|16@1+ (0.1,-100) [-100|200] "°C"  LOGBOX
 SG_ BMS5_ADB_M2_Reserved_Dis1 : 48|8@1+ (1,0) [255|255] "-"  LOGBOX
 SG_ BMS5_ADB_M2_Reserved_Dis2 : 56|8@1+ (1,0) [255|255] "-"  LOGBOX

BO_ 2566856869 _BMS5_ADB_M1_Disch_Sw_Temp: 8 BMS5_ADB
 SG_ BMS5_ADB_M1_Temperature_1 : 0|16@1+ (0.1,-100) [-100|200] "°C"  LOGBOX
 SG_ BMS5_ADB_M1_Temperature_2 : 16|16@1+ (0.1,-100) [-100|200] "°C"  LOGBOX
 SG_ BMS5_ADB_M1_Temperature_3 : 32|16@1+ (0.1,-100) [-100|200] "°C"  LOGBOX
 SG_ BMS5_ADB_M1_Reserved_Dis1 : 48|8@1+ (1,0) [255|255] "-"  LOGBOX
 SG_ BMS5_ADB_M1_Reserved_Dis2 : 56|8@1+ (1,0) [255|255] "-"  LOGBOX

BO_ 2566855333 _BMS5_ADB_M3_Pack_Temp: 8 BMS5_ADB
 SG_ BMS5_ADB_M3_FuelGauge1_Temp : 0|16@1+ (0.1,-100) [-100|200] "°C"  LOGBOX
 SG_ BMS5_ADB_M3_Thermistor1_temp : 32|16@1+ (0.1,-100) [-100|200] "-"  LOGBOX
 SG_ BMS5_ADB_M3_Thermistor2_temp : 48|16@1+ (0.1,-100) [-100|200] "-"  LOGBOX
 SG_ BMS5_ADB_M3_FuelGauge2_Temp : 16|16@1+ (0.1,-100) [-100|200] "°C"  LOGBOX

BO_ 2566855077 _BMS5_ADB_M2_Pack_Temp: 8 BMS5_ADB
 SG_ BMS5_ADB_M2_FuelGauge1_Temp : 0|16@1+ (0.1,-100) [-100|200] "°C"  LOGBOX
 SG_ BMS5_ADB_M2_Thermistor1_temp : 32|16@1+ (0.1,-100) [-100|200] "-"  LOGBOX
 SG_ BMS5_ADB_M2_Thermistor2_temp : 48|16@1+ (0.1,-100) [-100|200] "-"  LOGBOX
 SG_ BMS5_ADB_M2_FuelGauge2_Temp : 16|16@1+ (0.1,-100) [-100|200] "°C"  LOGBOX

BO_ 2566854821 _BMS5_ADB_M1_Pack_Temp: 8 BMS5_ADB
 SG_ BMS5_ADB_M1_FuelGauge1_Temp : 0|16@1+ (0.1,-100) [-100|200] "°C"  LOGBOX
 SG_ BMS5_ADB_M1_Thermistor1_temp : 32|16@1+ (0.1,-100) [-100|200] "-"  LOGBOX
 SG_ BMS5_ADB_M1_Thermistor2_temp : 48|16@1+ (0.1,-100) [-100|200] "-"  LOGBOX
 SG_ BMS5_ADB_M1_FuelGauge2_Temp : 16|16@1+ (0.1,-100) [-100|200] "°C"  LOGBOX

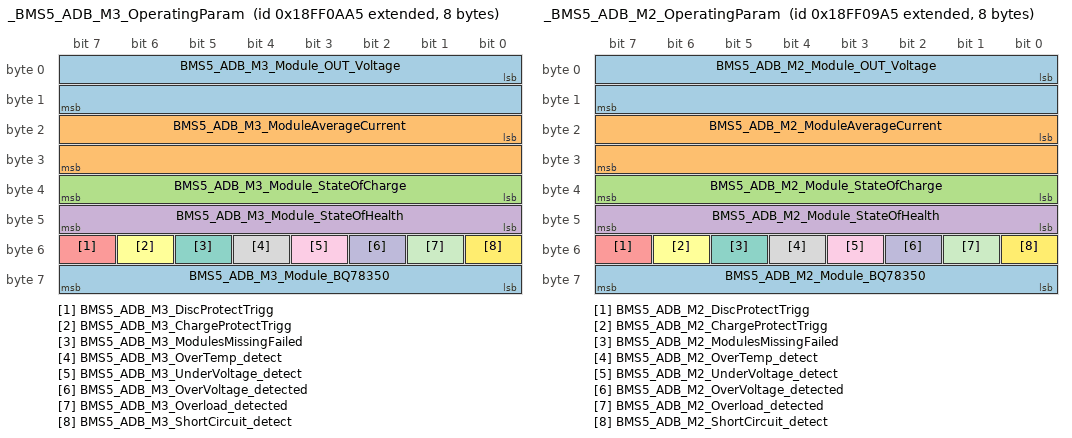
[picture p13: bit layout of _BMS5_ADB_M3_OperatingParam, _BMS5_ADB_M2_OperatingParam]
BO_ 2566851237 _BMS5_ADB_M3_OperatingParam: 8 BMS5_ADB
 SG_ BMS5_ADB_M3_Module_OUT_Voltage : 0|16@1+ (0.001,0) [0|64255] "V"  LOGBOX
 SG_ BMS5_ADB_M3_ModuleAverageCurrent : 16|16@1+ (0.1,-5500) [-5500|925.5] "A"  LOGBOX
 SG_ BMS5_ADB_M3_Module_StateOfCharge : 32|8@1+ (1,0) [0|100] "%"  LOGBOX
 SG_ BMS5_ADB_M3_Module_StateOfHealth : 40|8@1+ (1,0) [0|2] "-"  LOGBOX
 SG_ BMS5_ADB_M3_DiscProtectTrigg : 55|1@1+ (1,0) [0|1] "-"  LOGBOX
 SG_ BMS5_ADB_M3_ChargeProtectTrigg : 54|1@1+ (1,0) [0|1] "-"  LOGBOX
 SG_ BMS5_ADB_M3_ModulesMissingFailed : 53|1@1+ (1,0) [0|1] "-"  LOGBOX
 SG_ BMS5_ADB_M3_OverTemp_detect : 52|1@1+ (1,0) [0|1] "-"  LOGBOX
 SG_ BMS5_ADB_M3_UnderVoltage_detect : 51|1@1+ (1,0) [0|1] "-"  LOGBOX
 SG_ BMS5_ADB_M3_OverVoltage_detected : 50|1@1+ (1,0) [0|1] "-"  LOGBOX
 SG_ BMS5_ADB_M3_Overload_detected : 49|1@1+ (1,0) [0|1] "-"  LOGBOX
 SG_ BMS5_ADB_M3_ShortCircuit_detect : 48|1@1+ (1,0) [0|1] "-"  LOGBOX
 SG_ BMS5_ADB_M3_Module_BQ78350 : 56|8@1+ (1,0) [0|2] "-"  LOGBOX

BO_ 2566850981 _BMS5_ADB_M2_OperatingParam: 8 BMS5_ADB
 SG_ BMS5_ADB_M2_Module_OUT_Voltage : 0|16@1+ (0.001,0) [0|64255] "V"  LOGBOX
 SG_ BMS5_ADB_M2_ModuleAverageCurrent : 16|16@1+ (0.1,-5500) [-5500|925.5] "A"  LOGBOX
 SG_ BMS5_ADB_M2_Module_StateOfCharge : 32|8@1+ (1,0) [0|100] "%"  LOGBOX
 SG_ BMS5_ADB_M2_Module_StateOfHealth : 40|8@1+ (1,0) [0|2] "-"  LOGBOX
 SG_ BMS5_ADB_M2_DiscProtectTrigg : 55|1@1+ (1,0) [0|1] "-"  LOGBOX
 SG_ BMS5_ADB_M2_ChargeProtectTrigg : 54|1@1+ (1,0) [0|1] "-"  LOGBOX
 SG_ BMS5_ADB_M2_ModulesMissingFailed : 53|1@1+ (1,0) [0|1] "-"  LOGBOX
 SG_ BMS5_ADB_M2_OverTemp_detect : 52|1@1+ (1,0) [0|1] "-"  LOGBOX
 SG_ BMS5_ADB_M2_UnderVoltage_detect : 51|1@1+ (1,0) [0|1] "-"  LOGBOX
 SG_ BMS5_ADB_M2_OverVoltage_detected : 50|1@1+ (1,0) [0|1] "-"  LOGBOX
 SG_ BMS5_ADB_M2_Overload_detected : 49|1@1+ (1,0) [0|1] "-"  LOGBOX
 SG_ BMS5_ADB_M2_ShortCircuit_detect : 48|1@1+ (1,0) [0|1] "-"  LOGBOX
 SG_ BMS5_ADB_M2_Module_BQ78350 : 56|8@1+ (1,0) [0|2] "-"  LOGBOX

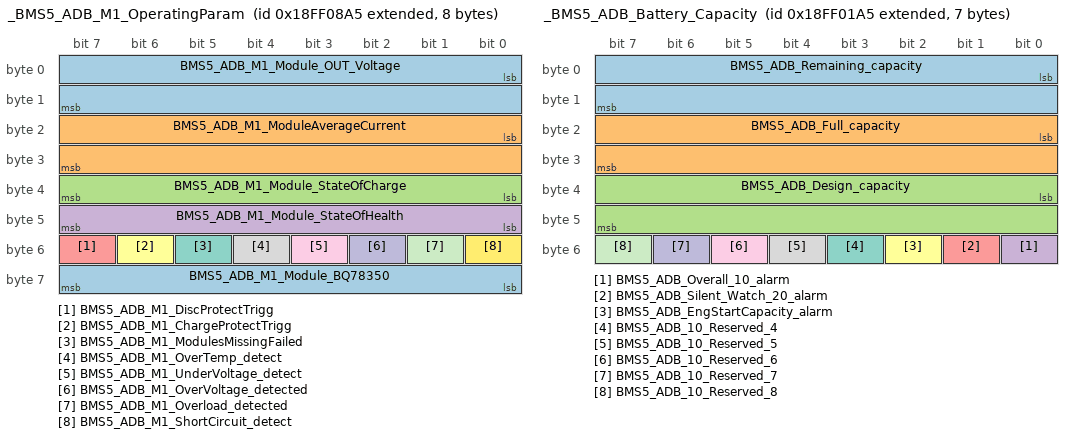
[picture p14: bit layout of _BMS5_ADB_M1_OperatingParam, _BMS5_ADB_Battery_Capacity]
BO_ 2566850725 _BMS5_ADB_M1_OperatingParam: 8 BMS5_ADB
 SG_ BMS5_ADB_M1_Module_OUT_Voltage : 0|16@1+ (0.001,0) [0|64255] "V"  LOGBOX
 SG_ BMS5_ADB_M1_ModuleAverageCurrent : 16|16@1+ (0.1,-5500) [-5500|925.5] "A"  LOGBOX
 SG_ BMS5_ADB_M1_Module_StateOfCharge : 32|8@1+ (1,0) [0|100] "%"  LOGBOX
 SG_ BMS5_ADB_M1_Module_StateOfHealth : 40|8@1+ (1,0) [0|2] "-"  LOGBOX
 SG_ BMS5_ADB_M1_DiscProtectTrigg : 55|1@1+ (1,0) [0|1] "-"  LOGBOX
 SG_ BMS5_ADB_M1_ChargeProtectTrigg : 54|1@1+ (1,0) [0|1] "-"  LOGBOX
 SG_ BMS5_ADB_M1_ModulesMissingFailed : 53|1@1+ (1,0) [0|1] "-"  LOGBOX
 SG_ BMS5_ADB_M1_OverTemp_detect : 52|1@1+ (1,0) [0|1] "-"  LOGBOX
 SG_ BMS5_ADB_M1_UnderVoltage_detect : 51|1@1+ (1,0) [0|1] "-"  LOGBOX
 SG_ BMS5_ADB_M1_OverVoltage_detected : 50|1@1+ (1,0) [0|1] "-"  LOGBOX
 SG_ BMS5_ADB_M1_Overload_detected : 49|1@1+ (1,0) [0|1] "-"  LOGBOX
 SG_ BMS5_ADB_M1_ShortCircuit_detect : 48|1@1+ (1,0) [0|1] "-"  LOGBOX
 SG_ BMS5_ADB_M1_Module_BQ78350 : 56|8@1+ (1,0) [0|2] "-"  LOGBOX

BO_ 2566849445 _BMS5_ADB_BatteryID: 6 BMS5_ADB
 SG_ BMS5_ADB_Battery_serial_number : 0|24@1+ (1,0) [0|16777214] "-"  LOGBOX
 SG_ BMS5_ADB_FirmwareVersionMajor : 24|8@1+ (1,0) [0|255] "-"  LOGBOX
 SG_ BMS5_ADB_FirmwareVersionMinor : 32|8@1+ (1,0) [0|255] "-"  LOGBOX
 SG_ BMS5_ADB_Firmware_Revision : 40|8@1+ (1,0) [0|255] "-"  LOGBOX

BO_ 2566849189 _BMS5_ADB_BatteryTemperature: 6 BMS5_ADB
 SG_ BMS5_ADB_Maximum_Temperature : 0|16@1+ (0.1,-100) [-100|200] "°C"  LOGBOX
 SG_ BMS5_ADB_Minimum_Temperature : 16|16@1+ (0.1,-100) [-100|200] "°C"  LOGBOX
 SG_ BMS5_ADB_Average_Temperature : 32|16@1+ (0.1,-100) [-100|200] "°C"  LOGBOX

BO_ 2566848933 _BMS5_ADB_Battery_Capacity: 7 BMS5_ADB
 SG_ BMS5_ADB_Remaining_capacity : 0|16@1+ (0.01,0) [0|642.55] "Ah"  LOGBOX
 SG_ BMS5_ADB_Full_capacity : 16|16@1+ (0.01,0) [0|642.55] "Ah"  LOGBOX
 SG_ BMS5_ADB_Design_capacity : 32|16@1+ (0.01,0) [0|642.55] "Ah"  LOGBOX
 SG_ BMS5_ADB_Overall_10_alarm : 48|1@1+ (1,0) [0|1] "-"  LOGBOX
 SG_ BMS5_ADB_Silent_Watch_20_alarm : 49|1@1+ (1,0) [0|1] "-"  LOGBOX
 SG_ BMS5_ADB_EngStartCapacity_alarm : 50|1@1+ (1,0) [0|1] "-"  LOGBOX
 SG_ BMS5_ADB_10_Reserved_4 : 51|1@1+ (1,0) [0|0] "-"  LOGBOX
 SG_ BMS5_ADB_10_Reserved_5 : 52|1@1+ (1,0) [0|0] "-"  LOGBOX
 SG_ BMS5_ADB_10_Reserved_6 : 53|1@1+ (1,0) [0|0] "-"  LOGBOX
 SG_ BMS5_ADB_10_Reserved_7 : 54|1@1+ (1,0) [0|0] "-"  LOGBOX
 SG_ BMS5_ADB_10_Reserved_8 : 55|1@1+ (1,0) [0|0] "-"  LOGBOX

BO_ 2566848677 _BMS5_ADB_BatteryOperatingParam: 8 BMS5_ADB
 SG_ BMS5_ADB_Batt_OUT_Voltage : 0|16@1+ (0.001,0) [0|64255] "V"  LOGBOX
 SG_ BMS5_ADB_Batt_Average_Current : 16|16@1+ (0.1,-5500) [-5500|925.5] "A"  LOGBOX
 SG_ BMS5_ADB_Batt_StsOfCharge : 32|8@1+ (1,0) [0|100] "%"  LOGBOX
 SG_ BMS5_ADB_Batt_StsOfHealth : 40|8@1+ (1,0) [0|2] "-"  LOGBOX
 SG_ BMS5_ADB_Batt_PS8_discharge_prot : 55|1@1+ (1,0) [0|1] "-"  LOGBOX
 SG_ BMS5_ADB_Batt_PS7_charge_prot : 54|1@1+ (1,0) [0|1] "-"  LOGBOX
 SG_ BMS5_ADB_Batt_PS6_mod_failed : 53|1@1+ (1,0) [0|1] "-"  LOGBOX
 SG_ BMS5_ADB_Batt_PS5_over_temp : 52|1@1+ (1,0) [0|1] "-"  LOGBOX
 SG_ BMS5_ADB_Batt_PS4_under_voltage : 51|1@1+ (1,0) [0|1] "-"  LOGBOX
 SG_ BMS5_ADB_Batt_PS3_over_voltage : 50|1@1+ (1,0) [0|1] "-"  LOGBOX
 SG_ BMS5_ADB_Batt_PS2_overload : 49|1@1+ (1,0) [0|1] "-"  LOGBOX
 SG_ BMS5_ADB_Batt_PS1_short_circuit : 48|1@1+ (1,0) [0|1] "-"  LOGBOX
 SG_ BMS5_ADB_Batt_OS_8_sleep_mode : 63|1@1+ (1,0) [0|1] "-"  LOGBOX
 SG_ BMS5_ADB_Batt_OS_7_emerg_used : 62|1@1+ (1,0) [0|1] "-"  LOGBOX
 SG_ BMS5_ADB_Batt_OS_6_emergency : 61|1@1+ (1,0) [0|1] "-"  LOGBOX
 SG_ BMS5_ADB_Batt_OS_45_charge_level : 59|2@1+ (1,0) [0|3] "-"  LOGBOX
 SG_ BMS5_ADB_Batt_OS_3_charge_cont : 58|1@1+ (1,0) [0|1] "-"  LOGBOX
 SG_ BMS5_ADB_Batt_OS_2_heater_cont : 57|1@1+ (1,0) [0|1] "-"  LOGBOX
 SG_ BMS5_ADB_Batt_OS_1_master_prot : 56|1@1+ (1,0) [0|1] "-"  LOGBOX

BO_ 2566804133 _BMS5_ADB_VEP_3: 8 BMS5_ADB
 SG_ _nu_BMS5_ADB_AlternatorCurrent : 0|16@1+ (0.05,-1600) [-1600|1612.75] "A"  LOGBOX
 SG_ BMS5_ADB_NetBattery_Current : 16|16@1+ (0.05,-1600) [-1600|1612.75] "A"  LOGBOX

BO_ 2566803621 _BMS5_ADB_Battery_1_Temp: 8 BMS5_ADB
 SG_ BMS5_ADB_Battery1_Temperature : 0|8@1+ (1,-40) [-40|210] "°C"  LOGBOX
 SG_ _nu_BMS5_ADB_Battery2_Temp : 8|8@1+ (1,-40) [-40|210] "°C"  LOGBOX

BO_ 2566698661 _BMS5_ADB_VEP_5: 8 BMS5_ADB
 SG_ BMS5_ADB_SLI_BattPack_StOfCharge : 0|16@1+ (0.0025,0) [0|1606375] "%"  LOGBOX
 SG_ BMS5_ADB_SLI_BattPack_Capacity : 16|16@1+ (1,0) [0|64255] "Ah"  LOGBOX
 SG_ BMS5_ADB_SLI_BattPack_Health : 32|8@1+ (0.5,0) [0|100] "%"  LOGBOX

BO_ 2566862245 _BMS5_ADB_SoftwareEvents2: 8 BMS5_ADB
 SG_ BMS5_ADB_HardMCLRReset_events : 0|16@1+ (1,0) [0|64255] "-"  LOGBOX
 SG_ BMS5_ADB_LowVoltageReset_events : 16|16@1+ (1,0) [0|64255] "-"  LOGBOX
 SG_ BMS5_ADB_PORReset_events : 32|16@1+ (1,0) [0|64255] "-"  LOGBOX
 SG_ BMS5_ADB_BrownOutReset_events : 48|16@1+ (1,0) [0|64255] "-"  LOGBOX

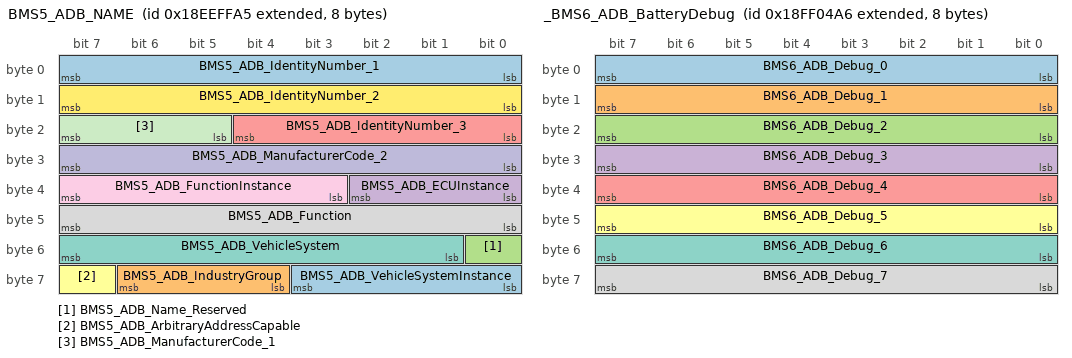
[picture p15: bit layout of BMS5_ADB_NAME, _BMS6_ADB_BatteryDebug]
BO_ 2565799845 BMS5_ADB_NAME: 8 BMS5_ADB
 SG_ BMS5_ADB_VehicleSystemInstance : 56|4@1+ (1,0) [0|15] "-"  LOGBOX,BC
 SG_ BMS5_ADB_IndustryGroup : 60|3@1+ (1,0) [0|7] "-"  LOGBOX,BC
 SG_ BMS5_ADB_Name_Reserved : 48|1@1+ (1,0) [0|1] "-"  LOGBOX,BC
 SG_ BMS5_ADB_ECUInstance : 32|3@1+ (1,0) [0|7] "-"  LOGBOX,BC
 SG_ BMS5_ADB_IdentityNumber_3 : 16|5@1+ (1,0) [0|31] "-"  LOGBOX,BC
 SG_ BMS5_ADB_ArbitraryAddressCapable : 63|1@1+ (1,0) [0|1] "-"  LOGBOX,BC
 SG_ BMS5_ADB_VehicleSystem : 49|7@1+ (1,0) [0|127] "-"  LOGBOX,BC
 SG_ BMS5_ADB_Function : 40|8@1+ (1,0) [0|255] "-"  LOGBOX,BC
 SG_ BMS5_ADB_FunctionInstance : 35|5@1+ (1,0) [0|31] "-"  LOGBOX,BC
 SG_ BMS5_ADB_ManufacturerCode_2 : 24|8@1+ (1,0) [0|255] "-"  LOGBOX,BC
 SG_ BMS5_ADB_ManufacturerCode_1 : 21|3@1+ (1,0) [0|7] "-"  LOGBOX,BC
 SG_ BMS5_ADB_IdentityNumber_2 : 8|8@1+ (1,0) [0|255] "-"  LOGBOX,BC
 SG_ BMS5_ADB_IdentityNumber_1 : 0|8@1+ (1,0) [0|255] "-"  LOGBOX,BC

BO_ 2566849958 BMS6_ADB_BatterySummaryStatus: 8 BMS6_ADB
 SG_ BMS6_ADB_BatSumS_serial_number : 0|24@1+ (1,0) [0|16777214] "-"  BC,LOGBOX
 SG_ BMS6_ADB_BatSumS_Reserved_01 : 24|8@1+ (1,0) [0|255] "-"  LOGBOX
 SG_ BMS6_ADB_BatSumS_State_of_Charge : 32|8@1+ (1,0) [0|100] "%"  LOGBOX,BC
 SG_ BMS6_ADB_BatSumS_State_of_Health : 40|8@1+ (1,0) [0|2] "-"  LOGBOX,BC
 SG_ BMS6_ADB_BatSumS_Temp_Alarm : 48|2@1+ (1,0) [0|3] "-"  LOGBOX,BC
 SG_ BMS6_ADB_BatSumS_DischargeDis : 50|1@1+ (1,0) [0|1] "-"  LOGBOX,BC
 SG_ BMS6_ADB_BatSumS_ChargingDisable : 51|1@1+ (1,0) [0|1] "-"  LOGBOX,BC
 SG_ BMS6_ADB_BatSumS_HeaterEnabled : 52|1@1+ (1,0) [0|1] "-"  LOGBOX,BC
 SG_ BMS6_ADB_BatSumS_BypassEnabled : 53|1@1+ (1,0) [0|1] "-"  LOGBOX,BC
 SG_ BMS6_ADB_BatSumS_Voltage_Alarm : 56|1@1+ (1,0) [0|1] "-"  LOGBOX,BC
 SG_ BMS6_ADB_BatSumS_Reserved_04 : 54|2@1+ (1,0) [0|3] "-"  LOGBOX
 SG_ BMS6_ADB_BatSumS_Reserved_05 : 57|1@1+ (1,0) [0|1] "-"  LOGBOX,BC
 SG_ BMS6_ADB_BatSumS_Reserved_06 : 58|1@1+ (1,0) [0|1] "-"  LOGBOX
 SG_ BMS6_ADB_BatSumS_Reserved_07 : 59|1@1+ (1,0) [0|1] "-"  LOGBOX
 SG_ BMS6_ADB_BatSumS_Reserved_08 : 60|1@1+ (1,0) [0|1] "-"  LOGBOX
 SG_ BMS6_ADB_BatSumS_Reserved_09 : 61|1@1+ (1,0) [0|1] "-"  LOGBOX
 SG_ BMS6_ADB_BatSumS_Reserved_10 : 62|1@1+ (1,0) [0|1] "-"  LOGBOX
 SG_ BMS6_ADB_BatSumS_Reserved_11 : 63|1@1+ (1,0) [0|1] "-"  LOGBOX

BO_ 2566849702 _BMS6_ADB_BatteryDebug: 8 BMS6_ADB
 SG_ BMS6_ADB_Debug_0 : 0|8@1+ (1,0) [0|255] "-"  LOGBOX
 SG_ BMS6_ADB_Debug_1 : 8|8@1+ (1,0) [0|255] "-"  LOGBOX
 SG_ BMS6_ADB_Debug_2 : 16|8@1+ (1,0) [0|255] "-"  LOGBOX
 SG_ BMS6_ADB_Debug_3 : 24|8@1+ (1,0) [0|255] "-"  LOGBOX
 SG_ BMS6_ADB_Debug_4 : 32|8@1+ (1,0) [0|255] "-"  LOGBOX
 SG_ BMS6_ADB_Debug_5 : 40|8@1+ (1,0) [0|255] "-"  LOGBOX
 SG_ BMS6_ADB_Debug_6 : 48|8@1+ (1,0) [0|255] "-"  LOGBOX
 SG_ BMS6_ADB_Debug_7 : 56|8@1+ (1,0) [0|255] "-"  LOGBOX

BO_ 2566853286 _BMS6_ADB_M3_Capacity: 7 BMS6_ADB
 SG_ BMS6_ADB_M1_Remaining_capacity : 0|16@1+ (0.01,0) [0|642.55] "Ah"  LOGBOX
 SG_ BMS6_ADB_M1_Full_capacity : 16|16@1+ (0.01,0) [0|642.55] "Ah"  LOGBOX
 SG_ BMS6_ADB_M1_Design_capacity : 32|16@1+ (0.01,0) [0|642.55] "Ah"  LOGBOX
 SG_ BMS6_ADB_M1_Reserved_Cap : 48|8@1+ (1,0) [255|255] "-"  LOGBOX

BO_ 2566853030 _BMS6_ADB_M2_Capacity: 7 BMS6_ADB
 SG_ BMS6_ADB_M2_Remaining_capacity : 0|16@1+ (0.01,0) [0|642.55] "Ah"  LOGBOX
 SG_ BMS6_ADB_M2_Full_capacity : 16|16@1+ (0.01,0) [0|642.55] "Ah"  LOGBOX
 SG_ BMS6_ADB_M2_Design_capacity : 32|16@1+ (0.01,0) [0|642.55] "Ah"  LOGBOX
 SG_ BMS6_ADB_M2_Reserved_Cap : 48|8@1+ (1,0) [255|255] "-"  LOGBOX

BO_ 2566852774 _BMS6_ADB_M1_Capacity: 7 BMS6_ADB
 SG_ BMS6_ADB_M3_Remaining_capacity : 0|16@1+ (0.01,0) [0|642.55] "Ah"  LOGBOX
 SG_ BMS6_ADB_M3_Full_capacity : 16|16@1+ (0.01,0) [0|642.55] "Ah"  LOGBOX
 SG_ BMS6_ADB_M3_Design_capacity : 32|16@1+ (0.01,0) [0|642.55] "Ah"  LOGBOX
 SG_ BMS6_ADB_M3_Reserved_Cap : 48|8@1+ (1,0) [255|255] "-"  LOGBOX

BO_ 2566861990 _BMS6_ADB_SoftwareEvents1: 8 BMS6_ADB
 SG_ BMS6_ADB_WatchdogReset_events : 0|16@1+ (1,0) [0|64255] "-"  LOGBOX
 SG_ BMS6_ADB_StackOverflowReset_even : 16|16@1+ (1,0) [0|64255] "-"  LOGBOX
 SG_ BMS6_ADB_CommandedReset_events : 32|16@1+ (1,0) [0|64255] "-"  LOGBOX
 SG_ BMS6_ADB_IllegalInstructionReset : 48|16@1+ (1,0) [0|64255] "-"  LOGBOX

BO_ 2566861734 _BMS6_ADB_VoltageEvents: 4 BMS6_ADB
 SG_ BMS6_ADB_OverVoltage_events : 0|16@1+ (1,0) [0|64255] "-"  LOGBOX
 SG_ BMS6_ADB_UnderVoltage_events : 16|16@1+ (1,0) [0|64255] "-"  LOGBOX

BO_ 2566861478 _BMS6_ADB_CurrentTempEvents: 8 BMS6_ADB
 SG_ BMS6_ADB_ShortCircuit_events : 0|16@1+ (1,0) [0|64255] "-"  LOGBOX
 SG_ BMS6_ADB_CurrentOverload_events : 16|16@1+ (1,0) [0|64255] "-"  LOGBOX
 SG_ BMS6_ADB_OverCurrent_Charge_ev : 32|16@1+ (1,0) [0|64255] "-"  LOGBOX
 SG_ BMS6_ADB_OverTemperature_ev : 48|16@1+ (1,0) [0|64255] "-"  LOGBOX

BO_ 2566861222 _BMS6_ADB_VoltageCurrentExt: 8 BMS6_ADB
 SG_ BMS6_ADB_MaximumVoltage : 0|16@1+ (0.001,0) [0|64255] "V"  LOGBOX
 SG_ BMS6_ADB_MinimumVoltage : 16|16@1+ (0.001,0) [0|64255] "V"  LOGBOX
 SG_ BMS6_ADB_MAX_Discharge_Current : 32|16@1+ (0.1,0) [0|6425.5] "A"  LOGBOX
 SG_ BMS6_ADB_MAX_Charge_Current : 48|16@1+ (0.1,0) [0|6425.5] "A"  LOGBOX

BO_ 2566860966 _BMS6_ADB_TemperatureExtremes: 8 BMS6_ADB
 SG_ BMS6_ADB_Maximum_Life_temp : 0|16@1+ (0.1,-100) [-100|200] "°C"  LOGBOX
 SG_ BMS6_ADB_Minimum_Life_temp : 16|16@1+ (0.1,-100) [-100|200] "°C"  LOGBOX
 SG_ BMS6_ADB_MAX_Charging_Temp : 32|16@1+ (0.1,-100) [-100|200] "°C"  LOGBOX
 SG_ BMS6_ADB_MIN_Charging_Temp : 48|16@1+ (0.1,-100) [-100|200] "°C"  LOGBOX

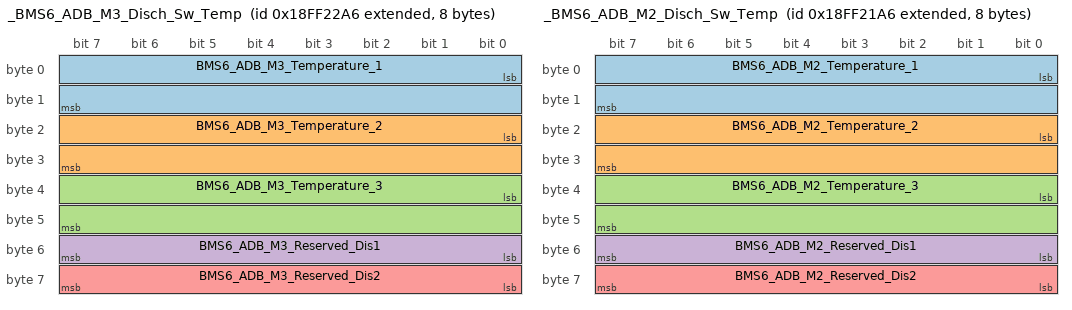
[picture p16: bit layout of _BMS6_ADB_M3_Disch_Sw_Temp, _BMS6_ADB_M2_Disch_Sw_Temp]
BO_ 2566857382 _BMS6_ADB_M3_Disch_Sw_Temp: 8 BMS6_ADB
 SG_ BMS6_ADB_M3_Temperature_1 : 0|16@1+ (0.1,-100) [-100|200] "°C"  LOGBOX
 SG_ BMS6_ADB_M3_Temperature_2 : 16|16@1+ (0.1,-100) [-100|200] "°C"  LOGBOX
 SG_ BMS6_ADB_M3_Temperature_3 : 32|16@1+ (0.1,-100) [-100|200] "°C"  LOGBOX
 SG_ BMS6_ADB_M3_Reserved_Dis1 : 48|8@1+ (1,0) [255|255] "-"  LOGBOX
 SG_ BMS6_ADB_M3_Reserved_Dis2 : 56|8@1+ (1,0) [255|255] "-"  LOGBOX

BO_ 2566857126 _BMS6_ADB_M2_Disch_Sw_Temp: 8 BMS6_ADB
 SG_ BMS6_ADB_M2_Temperature_1 : 0|16@1+ (0.1,-100) [-100|200] "°C"  LOGBOX
 SG_ BMS6_ADB_M2_Temperature_2 : 16|16@1+ (0.1,-100) [-100|200] "°C"  LOGBOX
 SG_ BMS6_ADB_M2_Temperature_3 : 32|16@1+ (0.1,-100) [-100|200] "°C"  LOGBOX
 SG_ BMS6_ADB_M2_Reserved_Dis1 : 48|8@1+ (1,0) [255|255] "-"  LOGBOX
 SG_ BMS6_ADB_M2_Reserved_Dis2 : 56|8@1+ (1,0) [255|255] "-"  LOGBOX

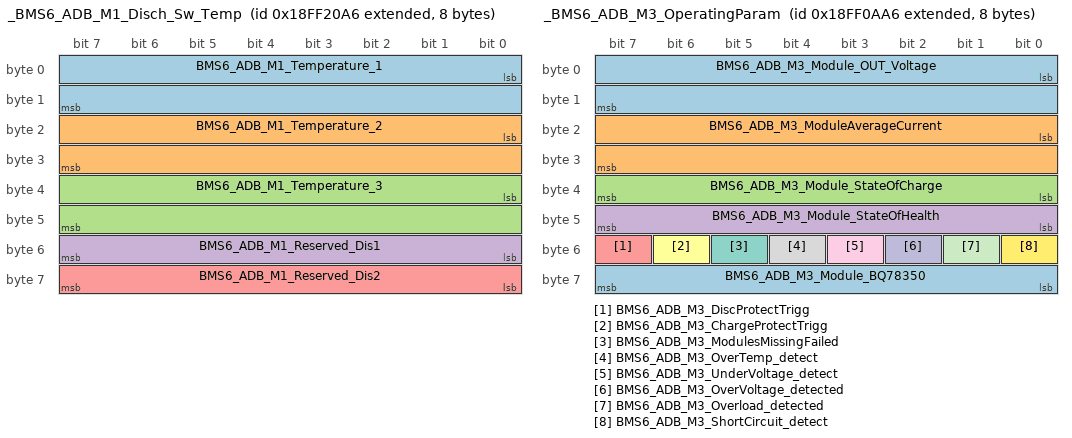
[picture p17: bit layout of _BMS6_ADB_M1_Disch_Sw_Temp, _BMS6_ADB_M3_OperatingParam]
BO_ 2566856870 _BMS6_ADB_M1_Disch_Sw_Temp: 8 BMS6_ADB
 SG_ BMS6_ADB_M1_Temperature_1 : 0|16@1+ (0.1,-100) [-100|200] "°C"  LOGBOX
 SG_ BMS6_ADB_M1_Temperature_2 : 16|16@1+ (0.1,-100) [-100|200] "°C"  LOGBOX
 SG_ BMS6_ADB_M1_Temperature_3 : 32|16@1+ (0.1,-100) [-100|200] "°C"  LOGBOX
 SG_ BMS6_ADB_M1_Reserved_Dis1 : 48|8@1+ (1,0) [255|255] "-"  LOGBOX
 SG_ BMS6_ADB_M1_Reserved_Dis2 : 56|8@1+ (1,0) [255|255] "-"  LOGBOX

BO_ 2566855334 _BMS6_ADB_M3_Pack_Temp: 8 BMS6_ADB
 SG_ BMS6_ADB_M3_FuelGauge1_Temp : 0|16@1+ (0.1,-100) [-100|200] "°C"  LOGBOX
 SG_ BMS6_ADB_M3_Thermistor1_temp : 32|16@1+ (0.1,-100) [-100|200] "-"  LOGBOX
 SG_ BMS6_ADB_M3_Thermistor2_temp : 48|16@1+ (0.1,-100) [-100|200] "-"  LOGBOX
 SG_ BMS6_ADB_M3_FuelGauge2_Temp : 16|16@1+ (0.1,-100) [-100|200] "°C"  LOGBOX

BO_ 2566855078 _BMS6_ADB_M2_Pack_Temp: 8 BMS6_ADB
 SG_ BMS6_ADB_M2_FuelGauge1_Temp : 0|16@1+ (0.1,-100) [-100|200] "°C"  LOGBOX
 SG_ BMS6_ADB_M2_Thermistor1_temp : 32|16@1+ (0.1,-100) [-100|200] "-"  LOGBOX
 SG_ BMS6_ADB_M2_Thermistor2_temp : 48|16@1+ (0.1,-100) [-100|200] "-"  LOGBOX
 SG_ BMS6_ADB_M2_FuelGauge2_Temp : 16|16@1+ (0.1,-100) [-100|200] "°C"  LOGBOX

BO_ 2566854822 _BMS6_ADB_M1_Pack_Temp: 8 BMS6_ADB
 SG_ BMS6_ADB_M1_FuelGauge1_Temp : 0|16@1+ (0.1,-100) [-100|200] "°C"  LOGBOX
 SG_ BMS6_ADB_M1_Thermistor1_temp : 32|16@1+ (0.1,-100) [-100|200] "-"  LOGBOX
 SG_ BMS6_ADB_M1_Thermistor2_temp : 48|16@1+ (0.1,-100) [-100|200] "-"  LOGBOX
 SG_ BMS6_ADB_M1_FuelGauge2_Temp : 16|16@1+ (0.1,-100) [-100|200] "°C"  LOGBOX

BO_ 2566851238 _BMS6_ADB_M3_OperatingParam: 8 BMS6_ADB
 SG_ BMS6_ADB_M3_Module_OUT_Voltage : 0|16@1+ (0.001,0) [0|64255] "V"  LOGBOX
 SG_ BMS6_ADB_M3_ModuleAverageCurrent : 16|16@1+ (0.1,-5500) [-5500|925.5] "A"  LOGBOX
 SG_ BMS6_ADB_M3_Module_StateOfCharge : 32|8@1+ (1,0) [0|100] "%"  LOGBOX
 SG_ BMS6_ADB_M3_Module_StateOfHealth : 40|8@1+ (1,0) [0|2] "-"  LOGBOX
 SG_ BMS6_ADB_M3_DiscProtectTrigg : 55|1@1+ (1,0) [0|1] "-"  LOGBOX
 SG_ BMS6_ADB_M3_ChargeProtectTrigg : 54|1@1+ (1,0) [0|1] "-"  LOGBOX
 SG_ BMS6_ADB_M3_ModulesMissingFailed : 53|1@1+ (1,0) [0|1] "-"  LOGBOX
 SG_ BMS6_ADB_M3_OverTemp_detect : 52|1@1+ (1,0) [0|1] "-"  LOGBOX
 SG_ BMS6_ADB_M3_UnderVoltage_detect : 51|1@1+ (1,0) [0|1] "-"  LOGBOX
 SG_ BMS6_ADB_M3_OverVoltage_detected : 50|1@1+ (1,0) [0|1] "-"  LOGBOX
 SG_ BMS6_ADB_M3_Overload_detected : 49|1@1+ (1,0) [0|1] "-"  LOGBOX
 SG_ BMS6_ADB_M3_ShortCircuit_detect : 48|1@1+ (1,0) [0|1] "-"  LOGBOX
 SG_ BMS6_ADB_M3_Module_BQ78350 : 56|8@1+ (1,0) [0|2] "-"  LOGBOX

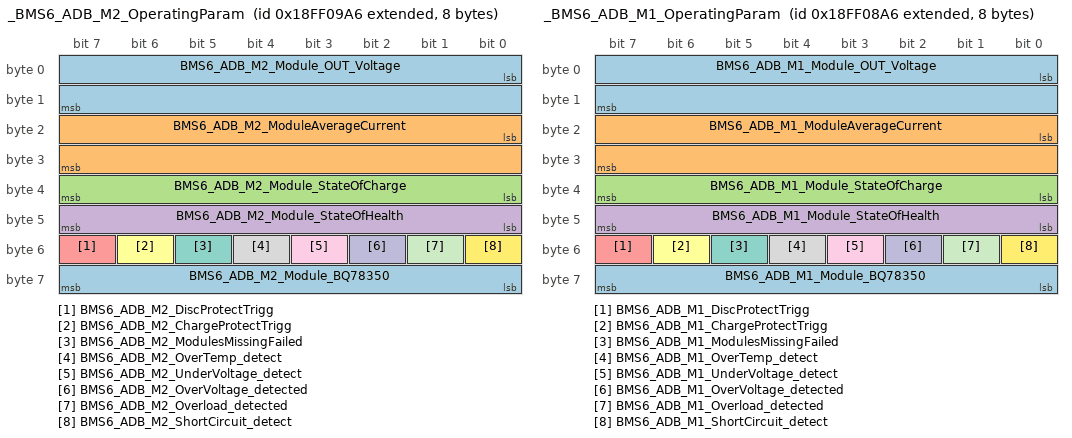
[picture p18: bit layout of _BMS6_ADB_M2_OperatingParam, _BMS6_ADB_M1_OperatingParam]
BO_ 2566850982 _BMS6_ADB_M2_OperatingParam: 8 BMS6_ADB
 SG_ BMS6_ADB_M2_Module_OUT_Voltage : 0|16@1+ (0.001,0) [0|64255] "V"  LOGBOX
 SG_ BMS6_ADB_M2_ModuleAverageCurrent : 16|16@1+ (0.1,-5500) [-5500|925.5] "A"  LOGBOX
 SG_ BMS6_ADB_M2_Module_StateOfCharge : 32|8@1+ (1,0) [0|100] "%"  LOGBOX
 SG_ BMS6_ADB_M2_Module_StateOfHealth : 40|8@1+ (1,0) [0|2] "-"  LOGBOX
 SG_ BMS6_ADB_M2_DiscProtectTrigg : 55|1@1+ (1,0) [0|1] "-"  LOGBOX
 SG_ BMS6_ADB_M2_ChargeProtectTrigg : 54|1@1+ (1,0) [0|1] "-"  LOGBOX
 SG_ BMS6_ADB_M2_ModulesMissingFailed : 53|1@1+ (1,0) [0|1] "-"  LOGBOX
 SG_ BMS6_ADB_M2_OverTemp_detect : 52|1@1+ (1,0) [0|1] "-"  LOGBOX
 SG_ BMS6_ADB_M2_UnderVoltage_detect : 51|1@1+ (1,0) [0|1] "-"  LOGBOX
 SG_ BMS6_ADB_M2_OverVoltage_detected : 50|1@1+ (1,0) [0|1] "-"  LOGBOX
 SG_ BMS6_ADB_M2_Overload_detected : 49|1@1+ (1,0) [0|1] "-"  LOGBOX
 SG_ BMS6_ADB_M2_ShortCircuit_detect : 48|1@1+ (1,0) [0|1] "-"  LOGBOX
 SG_ BMS6_ADB_M2_Module_BQ78350 : 56|8@1+ (1,0) [0|2] "-"  LOGBOX

BO_ 2566850726 _BMS6_ADB_M1_OperatingParam: 8 BMS6_ADB
 SG_ BMS6_ADB_M1_Module_OUT_Voltage : 0|16@1+ (0.001,0) [0|64255] "V"  LOGBOX
 SG_ BMS6_ADB_M1_ModuleAverageCurrent : 16|16@1+ (0.1,-5500) [-5500|925.5] "A"  LOGBOX
 SG_ BMS6_ADB_M1_Module_StateOfCharge : 32|8@1+ (1,0) [0|100] "%"  LOGBOX
 SG_ BMS6_ADB_M1_Module_StateOfHealth : 40|8@1+ (1,0) [0|2] "-"  LOGBOX
 SG_ BMS6_ADB_M1_DiscProtectTrigg : 55|1@1+ (1,0) [0|1] "-"  LOGBOX
 SG_ BMS6_ADB_M1_ChargeProtectTrigg : 54|1@1+ (1,0) [0|1] "-"  LOGBOX
 SG_ BMS6_ADB_M1_ModulesMissingFailed : 53|1@1+ (1,0) [0|1] "-"  LOGBOX
 SG_ BMS6_ADB_M1_OverTemp_detect : 52|1@1+ (1,0) [0|1] "-"  LOGBOX
 SG_ BMS6_ADB_M1_UnderVoltage_detect : 51|1@1+ (1,0) [0|1] "-"  LOGBOX
 SG_ BMS6_ADB_M1_OverVoltage_detected : 50|1@1+ (1,0) [0|1] "-"  LOGBOX
 SG_ BMS6_ADB_M1_Overload_detected : 49|1@1+ (1,0) [0|1] "-"  LOGBOX
 SG_ BMS6_ADB_M1_ShortCircuit_detect : 48|1@1+ (1,0) [0|1] "-"  LOGBOX
 SG_ BMS6_ADB_M1_Module_BQ78350 : 56|8@1+ (1,0) [0|2] "-"  LOGBOX

BO_ 2566849446 _BMS6_ADB_BatteryID: 6 BMS6_ADB
 SG_ BMS6_ADB_Battery_serial_number : 0|24@1+ (1,0) [0|16777214] "-"  LOGBOX
 SG_ BMS6_ADB_FirmwareVersionMajor : 24|8@1+ (1,0) [0|255] "-"  LOGBOX
 SG_ BMS6_ADB_FirmwareVersionMinor : 32|8@1+ (1,0) [0|255] "-"  LOGBOX
 SG_ BMS6_ADB_Firmware_Revision : 40|8@1+ (1,0) [0|255] "-"  LOGBOX

BO_ 2566849190 _BMS6_ADB_BatteryTemperature: 6 BMS6_ADB
 SG_ BMS6_ADB_Maximum_Temperature : 0|16@1+ (0.1,-100) [-100|200] "°C"  LOGBOX
 SG_ BMS6_ADB_Minimum_Temperature : 16|16@1+ (0.1,-100) [-100|200] "°C"  LOGBOX
 SG_ BMS6_ADB_Average_Temperature : 32|16@1+ (0.1,-100) [-100|200] "°C"  LOGBOX

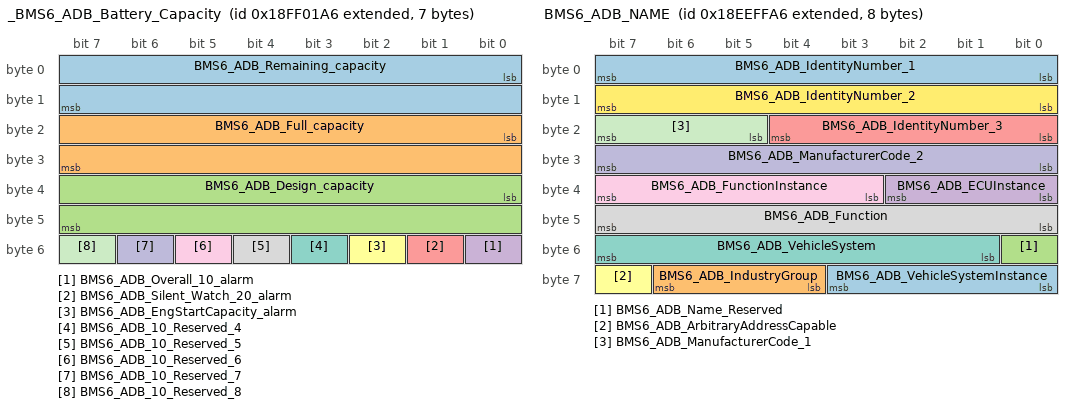
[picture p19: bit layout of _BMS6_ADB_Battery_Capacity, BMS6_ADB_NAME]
BO_ 2566848934 _BMS6_ADB_Battery_Capacity: 7 BMS6_ADB
 SG_ BMS6_ADB_Remaining_capacity : 0|16@1+ (0.01,0) [0|642.55] "Ah"  LOGBOX
 SG_ BMS6_ADB_Full_capacity : 16|16@1+ (0.01,0) [0|642.55] "Ah"  LOGBOX
 SG_ BMS6_ADB_Design_capacity : 32|16@1+ (0.01,0) [0|642.55] "Ah"  LOGBOX
 SG_ BMS6_ADB_Overall_10_alarm : 48|1@1+ (1,0) [0|1] "-"  LOGBOX
 SG_ BMS6_ADB_Silent_Watch_20_alarm : 49|1@1+ (1,0) [0|1] "-"  LOGBOX
 SG_ BMS6_ADB_EngStartCapacity_alarm : 50|1@1+ (1,0) [0|1] "-"  LOGBOX
 SG_ BMS6_ADB_10_Reserved_4 : 51|1@1+ (1,0) [0|0] "-"  LOGBOX
 SG_ BMS6_ADB_10_Reserved_5 : 52|1@1+ (1,0) [0|0] "-"  LOGBOX
 SG_ BMS6_ADB_10_Reserved_6 : 53|1@1+ (1,0) [0|0] "-"  LOGBOX
 SG_ BMS6_ADB_10_Reserved_7 : 54|1@1+ (1,0) [0|0] "-"  LOGBOX
 SG_ BMS6_ADB_10_Reserved_8 : 55|1@1+ (1,0) [0|0] "-"  LOGBOX

BO_ 2566848678 _BMS6_ADB_BatteryOperatingParam: 8 BMS6_ADB
 SG_ BMS6_ADB_Batt_OUT_Voltage : 0|16@1+ (0.001,0) [0|64255] "V"  LOGBOX
 SG_ BMS6_ADB_Batt_Average_Current : 16|16@1+ (0.1,-5500) [-5500|925.5] "A"  LOGBOX
 SG_ BMS6_ADB_Batt_StsOfCharge : 32|8@1+ (1,0) [0|100] "%"  LOGBOX
 SG_ BMS6_ADB_Batt_StsOfHealth : 40|8@1+ (1,0) [0|2] "-"  LOGBOX
 SG_ BMS6_ADB_Batt_PS8_discharge_prot : 55|1@1+ (1,0) [0|1] "-"  LOGBOX
 SG_ BMS6_ADB_Batt_PS7_charge_prot : 54|1@1+ (1,0) [0|1] "-"  LOGBOX
 SG_ BMS6_ADB_Batt_PS6_mod_failed : 53|1@1+ (1,0) [0|1] "-"  LOGBOX
 SG_ BMS6_ADB_Batt_PS5_over_temp : 52|1@1+ (1,0) [0|1] "-"  LOGBOX
 SG_ BMS6_ADB_Batt_PS4_under_voltage : 51|1@1+ (1,0) [0|1] "-"  LOGBOX
 SG_ BMS6_ADB_Batt_PS3_over_voltage : 50|1@1+ (1,0) [0|1] "-"  LOGBOX
 SG_ BMS6_ADB_Batt_PS2_overload : 49|1@1+ (1,0) [0|1] "-"  LOGBOX
 SG_ BMS6_ADB_Batt_PS1_short_circuit : 48|1@1+ (1,0) [0|1] "-"  LOGBOX
 SG_ BMS6_ADB_Batt_OS_8_sleep_mode : 63|1@1+ (1,0) [0|1] "-"  LOGBOX
 SG_ BMS6_ADB_Batt_OS_7_emerg_used : 62|1@1+ (1,0) [0|1] "-"  LOGBOX
 SG_ BMS6_ADB_Batt_OS_6_emergency : 61|1@1+ (1,0) [0|1] "-"  LOGBOX
 SG_ BMS6_ADB_Batt_OS_45_charge_level : 59|2@1+ (1,0) [0|3] "-"  LOGBOX
 SG_ BMS6_ADB_Batt_OS_3_charge_cont : 58|1@1+ (1,0) [0|1] "-"  LOGBOX
 SG_ BMS6_ADB_Batt_OS_2_heater_cont : 57|1@1+ (1,0) [0|1] "-"  LOGBOX
 SG_ BMS6_ADB_Batt_OS_1_master_prot : 56|1@1+ (1,0) [0|1] "-"  LOGBOX

BO_ 2566804134 _BMS6_ADB_VEP_3: 8 BMS6_ADB
 SG_ _nu_BMS6_ADB_AlternatorCurrent : 0|16@1+ (0.05,-1600) [-1600|1612.75] "A"  LOGBOX
 SG_ BMS6_ADB_NetBattery_Current : 16|16@1+ (0.05,-1600) [-1600|1612.75] "A"  LOGBOX

BO_ 2566803622 _BMS6_ADB_Battery_1_Temp: 8 BMS6_ADB
 SG_ BMS6_ADB_Battery1_Temperature : 0|8@1+ (1,-40) [-40|210] "°C"  LOGBOX
 SG_ _nu_BMS6_ADB_Battery2_Temp : 8|8@1+ (1,-40) [-40|210] "°C"  LOGBOX

BO_ 2566698662 _BMS6_ADB_VEP_5: 8 BMS6_ADB
 SG_ BMS6_ADB_SLI_BattPack_StOfCharge : 0|16@1+ (0.0025,0) [0|1606375] "%"  LOGBOX
 SG_ BMS6_ADB_SLI_BattPack_Capacity : 16|16@1+ (1,0) [0|64255] "Ah"  LOGBOX
 SG_ BMS6_ADB_SLI_BattPack_Health : 32|8@1+ (0.5,0) [0|100] "%"  LOGBOX

BO_ 2566862246 _BMS6_ADB_SoftwareEvents2: 8 BMS6_ADB
 SG_ BMS6_ADB_HardMCLRReset_events : 0|16@1+ (1,0) [0|64255] "-"  LOGBOX
 SG_ BMS6_ADB_LowVoltageReset_events : 16|16@1+ (1,0) [0|64255] "-"  LOGBOX
 SG_ BMS6_ADB_PORReset_events : 32|16@1+ (1,0) [0|64255] "-"  LOGBOX
 SG_ BMS6_ADB_BrownOutReset_events : 48|16@1+ (1,0) [0|64255] "-"  LOGBOX

BO_ 2565799846 BMS6_ADB_NAME: 8 BMS6_ADB
 SG_ BMS6_ADB_VehicleSystemInstance : 56|4@1+ (1,0) [0|15] "-"  LOGBOX,BC
 SG_ BMS6_ADB_IndustryGroup : 60|3@1+ (1,0) [0|7] "-"  LOGBOX,BC
 SG_ BMS6_ADB_Name_Reserved : 48|1@1+ (1,0) [0|1] "-"  LOGBOX,BC
 SG_ BMS6_ADB_ECUInstance : 32|3@1+ (1,0) [0|7] "-"  LOGBOX,BC
 SG_ BMS6_ADB_IdentityNumber_3 : 16|5@1+ (1,0) [0|31] "-"  LOGBOX,BC
 SG_ BMS6_ADB_ArbitraryAddressCapable : 63|1@1+ (1,0) [0|1] "-"  LOGBOX,BC
 SG_ BMS6_ADB_VehicleSystem : 49|7@1+ (1,0) [0|127] "-"  LOGBOX,BC
 SG_ BMS6_ADB_Function : 40|8@1+ (1,0) [0|255] "-"  LOGBOX,BC
 SG_ BMS6_ADB_FunctionInstance : 35|5@1+ (1,0) [0|31] "-"  LOGBOX,BC
 SG_ BMS6_ADB_ManufacturerCode_2 : 24|8@1+ (1,0) [0|255] "-"  LOGBOX,BC
 SG_ BMS6_ADB_ManufacturerCode_1 : 21|3@1+ (1,0) [0|7] "-"  LOGBOX,BC
 SG_ BMS6_ADB_IdentityNumber_2 : 8|8@1+ (1,0) [0|255] "-"  LOGBOX,BC
 SG_ BMS6_ADB_IdentityNumber_1 : 0|8@1+ (1,0) [0|255] "-"  LOGBOX,BC

CM_ BO_ 2566698659 "PGN containing vehicle electrical power information for the battery pack used for starting, lighting, and ignition.";
CM_ SG_ 2566698659 BMS3_ADB_SLI_BattPack_StOfCharge "5981
SLI Battery Pack State of Charge
Indicates the remaining charge of the battery pack used for starting the engine, for lighting, and for ignition (SLI). 0% means no charge remaining, 100% means full capacity at the battery pack's current state of health.   See SPN 5464 for hybrid battery pack.";
CM_ SG_ 2566698659 BMS3_ADB_SLI_BattPack_Capacity "5982
SLI Battery Pack Capacity
Original or rated total reserve capacity of the battery pack used for starting the engine, for lighting, and for ignition (SLI).";
CM_ SG_ 2566698659 BMS3_ADB_SLI_BattPack_Health "5983
SLI Battery Pack Health
Capacity of the battery pack relative to its original specification for the battery pack used for starting the engine, for lighting, and for ignition (SLI). 0% means battery pack is not capable of holding any charge, 100% means battery pack is capable of holding its original full capacity.";
CM_ BO_ 2566862243 "This PGN reports the total number of software-related events that have occurred during the life of the battery.";
CM_ SG_ 2566862243 BMS3_ADB_HardMCLRReset_events "This parameter contains a count of the number times the MCLR has reset the firmware due to a hardware reset pulse, this may be due to the external watchdog.
Data Range: 0 – 64255. A value of 64255 indicates 64255 events or more.";
CM_ SG_ 2566862243 BMS3_ADB_LowVoltageReset_events "TThis parameter contains a count of the number times the firmware has been reset due to the processor detecting a low supply voltage.
Data Range: 0 – 64255. A value of 64255 indicates 64255 events or more.";
CM_ SG_ 2566862243 BMS3_ADB_PORReset_events "This parameter contains a count of the number times the firmware has been started from a power up condition.
Data Range: 0 – 64255. A value of 64255 indicates 64255 events or more.";
CM_ SG_ 2566862243 BMS3_ADB_BrownOutReset_events "This parameter contains a count of the number times the firmware has been restarted due to a brown-out (below 2.7V).
Data Range: 0 – 64255. A value of 64255 indicates 64255 events or more.";
CM_ BO_ 2565799843 "Generic message for send the NAME
Used only for the BMS3";
CM_ SG_ 2565799843 BMS3_ADB_VehicleSystemInstance "Vehicle System Instance";
CM_ SG_ 2565799843 BMS3_ADB_IndustryGroup "Industry Group";
CM_ SG_ 2565799843 BMS3_ADB_Name_Reserved "Reserved";
CM_ SG_ 2565799843 BMS3_ADB_ECUInstance "ECU Instance";
CM_ SG_ 2565799843 BMS3_ADB_IdentityNumber_3 "Most significant 5 bits of Identity Number";
CM_ SG_ 2565799843 BMS3_ADB_ArbitraryAddressCapable "Arbitrary Address Capable";
CM_ SG_ 2565799843 BMS3_ADB_VehicleSystem "Vehicle System";
CM_ SG_ 2565799843 BMS3_ADB_Function "Function";
CM_ SG_ 2565799843 BMS3_ADB_FunctionInstance "Function Instance";
CM_ SG_ 2565799843 BMS3_ADB_ManufacturerCode_2 "Most significant 8 bits of Manufacturer Code";
CM_ SG_ 2565799843 BMS3_ADB_ManufacturerCode_1 "Least significant 3 bits of Manufacturer Code";
CM_ SG_ 2565799843 BMS3_ADB_IdentityNumber_2 "Second byte of Identity Number";
CM_ SG_ 2565799843 BMS3_ADB_IdentityNumber_1 "Least significant byte of Identity Number";
CM_ BO_ 2566849956 "This PGN reports a summary of the the operating parameters of the full battery: serial number, state of charge, state of health, temperature alarm, voltage alarm for the battery.";
CM_ SG_ 2566849956 BMS4_ADB_BatSumS_serial_number "This parameter contains the manufactured serial number of the battery. The lowest 21 bits of this 24 bit serial number are also used in the J1939 NAME – see 2.1.";
CM_ SG_ 2566849956 BMS4_ADB_BatSumS_Reserved_01 "Reserved";
CM_ SG_ 2566849956 BMS4_ADB_BatSumS_State_of_Charge "This parameter contains the ratio of the remaining capacity of the battery to the full capacity expressed as a percentage.";
CM_ SG_ 2566849956 BMS4_ADB_BatSumS_State_of_Health "This parameter contains a value relating to the state of health of the battery based on defined thresholds of the ratio of full capacity to design capacity.";
CM_ SG_ 2566849956 BMS4_ADB_BatSumS_Temp_Alarm "This parameter contains the temperature alarm, based on the maximum battery temperature.
0x00: No fault;
0x01: Low Temperature Alarm
0x02: High Temperature Alarm
0x03: Wrong Temperature Alarm";
CM_ SG_ 2566849956 BMS4_ADB_BatSumS_DischargeDis "This parameter indicates when the battery is not able to be discharged.
0x00: Discharge Enable;
0x01: Discharge Disable";
CM_ SG_ 2566849956 BMS4_ADB_BatSumS_ChargingDisable "This parameter indicates when the battery is not able to be discharged.
0x00: Charging Enable;
0x01: Charging Disable";
CM_ SG_ 2566849956 BMS4_ADB_BatSumS_HeaterEnabled "This parameter indicates when the heater is enabled.
0x00: Heater Disabled;
0x01: Heater Enabled";
CM_ SG_ 2566849956 BMS4_ADB_BatSumS_BypassEnabled "This parameter indicates when the bypass is enabled.
0x00: Bypass Disabled;
0x01: Bypass Enabled";
CM_ SG_ 2566849956 BMS4_ADB_BatSumS_Voltage_Alarm "This parameter indicates an over voltage condition in one or more modules.
0x00: No fault;
0x01:Over Voltage Alarm";
CM_ SG_ 2566849956 BMS4_ADB_BatSumS_Reserved_04 "Reserved";
CM_ SG_ 2566849956 BMS4_ADB_BatSumS_Reserved_05 "Reserved";
CM_ SG_ 2566849956 BMS4_ADB_BatSumS_Reserved_06 "Reserved";
CM_ SG_ 2566849956 BMS4_ADB_BatSumS_Reserved_07 "Reserved";
CM_ SG_ 2566849956 BMS4_ADB_BatSumS_Reserved_08 "Reserved";
CM_ SG_ 2566849956 BMS4_ADB_BatSumS_Reserved_09 "Reserved";
CM_ SG_ 2566849956 BMS4_ADB_BatSumS_Reserved_10 "Reserved";
CM_ SG_ 2566849956 BMS4_ADB_BatSumS_Reserved_11 "Reserved";
CM_ BO_ 2566849700 "Used for debugging purposes.";
CM_ SG_ 2566849700 BMS4_ADB_Debug_0 "Used for debugging purpose - byte 0";
CM_ SG_ 2566849700 BMS4_ADB_Debug_1 "Used for debugging purpose - byte 1";
CM_ SG_ 2566849700 BMS4_ADB_Debug_2 "Used for debugging purpose - byte 2";
CM_ SG_ 2566849700 BMS4_ADB_Debug_3 "Used for debugging purpose - byte 3";
CM_ SG_ 2566849700 BMS4_ADB_Debug_4 "Used for debugging purpose - byte 4";
CM_ SG_ 2566849700 BMS4_ADB_Debug_5 "Used for debugging purpose - byte 5";
CM_ SG_ 2566849700 BMS4_ADB_Debug_6 "Used for debugging purpose - byte 6";
CM_ SG_ 2566849700 BMS4_ADB_Debug_7 "Used for debugging purpose - byte 7";
CM_ BO_ 2566853284 "This PGN reports the remaining module capacity, the expected full module capacity and the designed module capacity for module 3.";
CM_ SG_ 2566853284 BMS4_ADB_M1_Remaining_capacity "This parameter contains the remaining capacity of the battery.";
CM_ SG_ 2566853284 BMS4_ADB_M1_Full_capacity "This parameter contains the full capacity of the battery.";
CM_ SG_ 2566853284 BMS4_ADB_M1_Design_capacity "This parameter contains the design capacity of the battery.";
CM_ SG_ 2566853284 BMS4_ADB_M1_Reserved_Cap "Reserved";
CM_ BO_ 2566853028 "This PGN reports the remaining module capacity, the expected full module capacity and the designed module capacity for module 2.";
CM_ SG_ 2566853028 BMS4_ADB_M2_Remaining_capacity "This parameter contains the remaining capacity of the battery.";
CM_ SG_ 2566853028 BMS4_ADB_M2_Full_capacity "This parameter contains the full capacity of the battery.";
CM_ SG_ 2566853028 BMS4_ADB_M2_Design_capacity "This parameter contains the design capacity of the battery.";
CM_ SG_ 2566853028 BMS4_ADB_M2_Reserved_Cap "Reserved";
CM_ BO_ 2566852772 "This PGN reports the remaining module capacity, the expected full module capacity and the designed module capacity for module 1.";
CM_ SG_ 2566852772 BMS4_ADB_M3_Remaining_capacity "This parameter contains the remaining capacity of the battery.";
CM_ SG_ 2566852772 BMS4_ADB_M3_Full_capacity "This parameter contains the full capacity of the battery.";
CM_ SG_ 2566852772 BMS4_ADB_M3_Design_capacity "This parameter contains the design capacity of the battery.";
CM_ SG_ 2566852772 BMS4_ADB_M3_Reserved_Cap "Reserved";
CM_ BO_ 2566861988 "This PGN reports the total number of software-related events that have occurred during the life of the battery.";
CM_ SG_ 2566861988 BMS4_ADB_WatchdogReset_events "This parameter contains a count of the number times the watchdog has reset the firmware due to an internal lock-up.
Data Range: 0 – 64255. A value of 64255 indicates 64255 events or more.";
CM_ SG_ 2566861988 BMS4_ADB_StackOverflowReset_even "This parameter contains a count of the number times the firmware has been reset due to a stack-overflow.
Data Range: 0 – 64255. A value of 64255 indicates 64255 events or more.";
CM_ SG_ 2566861988 BMS4_ADB_CommandedReset_events "This parameter contains a count of the number times the firmware has been reset by a CAN, USB or status button command.
Data Range: 0 – 64255. A value of 64255 indicates 64255 events or more.";
CM_ SG_ 2566861988 BMS4_ADB_IllegalInstructionReset "This parameter contains a count of the number times the firmware has been hard-reset using the status button.
Data Range: 0 – 64255. A value of 64255 indicates 64255 events or more.";
CM_ BO_ 2566861732 "This PGN reports the total number of voltage-related events that have occurred during the life of the battery.";
CM_ SG_ 2566861732 BMS4_ADB_OverVoltage_events "This parameter contains a count of the number of times an over-voltage event has occurred.";
CM_ SG_ 2566861732 BMS4_ADB_UnderVoltage_events "This parameter contains a count of the number of times an under-voltage event has occurred.";
CM_ BO_ 2566861476 "This PGN reports the total number of current and temperature-related events that have occurred during the life of the battery.";
CM_ SG_ 2566861476 BMS4_ADB_ShortCircuit_events "This parameter contains a count of the number of times the battery has been short-circuited.";
CM_ SG_ 2566861476 BMS4_ADB_CurrentOverload_events "This parameter contains a count of the number of times the battery has been overloaded.";
CM_ SG_ 2566861476 BMS4_ADB_OverCurrent_Charge_ev "This parameter contains a count of the number of times the battery’s maximum charge current has been exceeded.";
CM_ SG_ 2566861476 BMS4_ADB_OverTemperature_ev "This parameter contains a count of the number of times the battery’s maximum temperature has been exceeded.";
CM_ BO_ 2566861220 "This PGN reports on the maximum and minimum battery voltages and currents measured during the life of the battery.";
CM_ SG_ 2566861220 BMS4_ADB_MaximumVoltage "This parameter contains the maximum voltage ever measured across the battery cells.";
CM_ SG_ 2566861220 BMS4_ADB_MinimumVoltage "This parameter contains the minimum voltage ever measured across the battery cells.";
CM_ SG_ 2566861220 BMS4_ADB_MAX_Discharge_Current "This parameter contains the maximum discharge current ever measured on the battery.";
CM_ SG_ 2566861220 BMS4_ADB_MAX_Charge_Current "This parameter contains the maximum charge current ever measured on the battery.";
CM_ BO_ 2566860964 "This PGN reports on the maximum and minimum temperatures experienced during the life of the battery.";
CM_ SG_ 2566860964 BMS4_ADB_Maximum_Life_temp "This parameter contains the maximum temperature ever measured in the battery.";
CM_ SG_ 2566860964 BMS4_ADB_Minimum_Life_temp "This parameter contains the minimum temperature ever measured in the battery.";
CM_ SG_ 2566860964 BMS4_ADB_MAX_Charging_Temp "This parameter contains the maximum temperature ever measured while charging the battery.";
CM_ SG_ 2566860964 BMS4_ADB_MIN_Charging_Temp "This parameter contains the minimum temperature ever measured while charging the battery.";
CM_ BO_ 2566857380 "This PGN reports on the individual discharge switch temperatures within module 3 of the battery. The values are only valid when the discharge current exceeds 10A for the entire battery, at other times the values returned will be the J1939 unavailable value.";
CM_ SG_ 2566857380 BMS4_ADB_M3_Temperature_1 "This parameter contains the temperature of a discharge switch sensor.";
CM_ SG_ 2566857380 BMS4_ADB_M3_Temperature_2 "This parameter contains the temperature of a discharge switch sensor.";
CM_ SG_ 2566857380 BMS4_ADB_M3_Temperature_3 "This parameter contains the temperature of a discharge switch sensor.";
CM_ SG_ 2566857380 BMS4_ADB_M3_Reserved_Dis1 "Reserved";
CM_ SG_ 2566857380 BMS4_ADB_M3_Reserved_Dis2 "Reserved";
CM_ BO_ 2566857124 "This PGN reports on the individual discharge switch temperatures within module 2 of the battery. The values are only valid when the discharge current exceeds 10A for the entire battery, at other times the values returned will be the J1939 unavailable value.";
CM_ SG_ 2566857124 BMS4_ADB_M2_Temperature_1 "This parameter contains the temperature of a discharge switch sensor.";
CM_ SG_ 2566857124 BMS4_ADB_M2_Temperature_2 "This parameter contains the temperature of a discharge switch sensor.";
CM_ SG_ 2566857124 BMS4_ADB_M2_Temperature_3 "This parameter contains the temperature of a discharge switch sensor.";
CM_ SG_ 2566857124 BMS4_ADB_M2_Reserved_Dis1 "Reserved";
CM_ SG_ 2566857124 BMS4_ADB_M2_Reserved_Dis2 "Reserved";
CM_ BO_ 2566856868 "This PGN reports on the individual discharge switch temperatures within module 1 of the battery. The values are only valid when the discharge current exceeds 10A for the entire battery, at other times the values returned will be the J1939 unavailable value.";
CM_ SG_ 2566856868 BMS4_ADB_M1_Temperature_1 "This parameter contains the temperature of a discharge switch sensor.";
CM_ SG_ 2566856868 BMS4_ADB_M1_Temperature_2 "This parameter contains the temperature of a discharge switch sensor.";
CM_ SG_ 2566856868 BMS4_ADB_M1_Temperature_3 "This parameter contains the temperature of a discharge switch sensor.";
CM_ SG_ 2566856868 BMS4_ADB_M1_Reserved_Dis1 "Reserved";
CM_ SG_ 2566856868 BMS4_ADB_M1_Reserved_Dis2 "Reserved";
CM_ BO_ 2566855332 "This PGN reports on the individual temperatures measured within module 3 of the battery.";
CM_ SG_ 2566855332 BMS4_ADB_M3_FuelGauge1_Temp "This parameter contains the temperature measured by the module’s fuel gauge IC.";
CM_ SG_ 2566855332 BMS4_ADB_M3_Thermistor1_temp "This parameter contains the temperature measured by one of the module’s Thermistors.";
CM_ SG_ 2566855332 BMS4_ADB_M3_Thermistor2_temp "This parameter contains the temperature measured by one of the module’s Thermistors.";
CM_ SG_ 2566855332 BMS4_ADB_M3_FuelGauge2_Temp "This parameter contains the temperature measured by the module’s fuel gauge IC.";
CM_ BO_ 2566855076 "This PGN reports on the individual temperatures measured within module 2 of the battery.";
CM_ SG_ 2566855076 BMS4_ADB_M2_FuelGauge1_Temp "This parameter contains the temperature measured by the module’s fuel gauge IC.";
CM_ SG_ 2566855076 BMS4_ADB_M2_Thermistor1_temp "This parameter contains the temperature measured by one of the module’s Thermistors.";
CM_ SG_ 2566855076 BMS4_ADB_M2_Thermistor2_temp "This parameter contains the temperature measured by one of the module’s Thermistors.";
CM_ SG_ 2566855076 BMS4_ADB_M2_FuelGauge2_Temp "This parameter contains the temperature measured by the module’s fuel gauge IC.";
CM_ BO_ 2566854820 "This PGN reports on the individual temperatures measured within module 1 of the battery.";
CM_ SG_ 2566854820 BMS4_ADB_M1_FuelGauge1_Temp "This parameter contains the temperature measured by the module’s fuel gauge IC.";
CM_ SG_ 2566854820 BMS4_ADB_M1_Thermistor1_temp "This parameter contains the temperature measured by one of the module’s Thermistors.";
CM_ SG_ 2566854820 BMS4_ADB_M1_Thermistor2_temp "This parameter contains the temperature measured by one of the module’s Thermistors.";
CM_ SG_ 2566854820 BMS4_ADB_M1_FuelGauge2_Temp "This parameter contains the temperature measured by the module’s fuel gauge IC.";
CM_ BO_ 2566851236 "This PGN reports the operating parameters of module 3 within the battery: output voltage, average current (charge or discharge), the percentage state of charge, a state of health indication and the protection status of the module.";
CM_ SG_ 2566851236 BMS4_ADB_M3_Module_OUT_Voltage "This parameter contains the output voltage of the module.";
CM_ SG_ 2566851236 BMS4_ADB_M3_ModuleAverageCurrent "This parameter contains the charge (positive) or discharge (negative) current of the module averaged over 1 second.";
CM_ SG_ 2566851236 BMS4_ADB_M3_Module_StateOfCharge "This parameter contains the ratio of the remaining capacity of the module to the full capacity of the module expressed as a percentage.";
CM_ SG_ 2566851236 BMS4_ADB_M3_Module_StateOfHealth "This parameter contains a value relating to the state of health of the module based on defined thresholds of the ratio of full capacity to design capacity.";
CM_ SG_ 2566851236 BMS4_ADB_M3_DiscProtectTrigg "This parameter contains the current protection status of the module.
Discharge protection triggered";
CM_ SG_ 2566851236 BMS4_ADB_M3_ChargeProtectTrigg "This parameter contains the current protection status of the module.
Charge protection triggered";
CM_ SG_ 2566851236 BMS4_ADB_M3_ModulesMissingFailed "This parameter contains the current protection status of the module.
Modules missing/failed";
CM_ SG_ 2566851236 BMS4_ADB_M3_OverTemp_detect "This parameter contains the current protection status of the module.
Over-temperature detected";
CM_ SG_ 2566851236 BMS4_ADB_M3_UnderVoltage_detect "This parameter contains the current protection status of the module.
Under-voltage detected";
CM_ SG_ 2566851236 BMS4_ADB_M3_OverVoltage_detected "This parameter contains the current protection status of the module.
Over-voltage detected";
CM_ SG_ 2566851236 BMS4_ADB_M3_Overload_detected "This parameter contains the current protection status of the module.
Overload detected";
CM_ SG_ 2566851236 BMS4_ADB_M3_ShortCircuit_detect "This parameter contains the current protection status of the module.
Short circuit detected";
CM_ SG_ 2566851236 BMS4_ADB_M3_Module_BQ78350 "This parameter contains selected data from the BQ78350 status.
Each bit indicates a different alarm (bit 1 indicates extra 1, bit 2 indicates extra 2 …) where 0 indicates no fault and 1 indicates missing, failed or protection triggered";
CM_ BO_ 2566850980 "This PGN reports the operating parameters of module 2 within the battery: output voltage, average current (charge or discharge), the percentage state of charge, a state of health indication and the protection status of the module.";
CM_ SG_ 2566850980 BMS4_ADB_M2_Module_OUT_Voltage "This parameter contains the output voltage of the module.";
CM_ SG_ 2566850980 BMS4_ADB_M2_ModuleAverageCurrent "This parameter contains the charge (positive) or discharge (negative) current of the module averaged over 1 second.";
CM_ SG_ 2566850980 BMS4_ADB_M2_Module_StateOfCharge "This parameter contains the ratio of the remaining capacity of the module to the full capacity of the module expressed as a percentage.";
CM_ SG_ 2566850980 BMS4_ADB_M2_Module_StateOfHealth "This parameter contains a value relating to the state of health of the module based on defined thresholds of the ratio of full capacity to design capacity.";
CM_ SG_ 2566850980 BMS4_ADB_M2_DiscProtectTrigg "This parameter contains the current protection status of the module.
Discharge protection triggered";
CM_ SG_ 2566850980 BMS4_ADB_M2_ChargeProtectTrigg "This parameter contains the current protection status of the module.
Charge protection triggered";
CM_ SG_ 2566850980 BMS4_ADB_M2_ModulesMissingFailed "This parameter contains the current protection status of the module.
Modules missing/failed";
CM_ SG_ 2566850980 BMS4_ADB_M2_OverTemp_detect "This parameter contains the current protection status of the module.
Over-temperature detected";
CM_ SG_ 2566850980 BMS4_ADB_M2_UnderVoltage_detect "This parameter contains the current protection status of the module.
Under-voltage detected";
CM_ SG_ 2566850980 BMS4_ADB_M2_OverVoltage_detected "This parameter contains the current protection status of the module.
Over-voltage detected";
CM_ SG_ 2566850980 BMS4_ADB_M2_Overload_detected "This parameter contains the current protection status of the module.
Overload detected";
CM_ SG_ 2566850980 BMS4_ADB_M2_ShortCircuit_detect "This parameter contains the current protection status of the module.
Short circuit detected";
CM_ SG_ 2566850980 BMS4_ADB_M2_Module_BQ78350 "This parameter contains selected data from the BQ78350 status.
Each bit indicates a different alarm (bit 1 indicates extra 1, bit 2 indicates extra 2 …) where 0 indicates no fault and 1 indicates missing, failed or protection triggered";
CM_ BO_ 2566850724 "This PGN reports the operating parameters of module 1 within the battery: output voltage, average current (charge or discharge), the percentage state of charge, a state of health indication and the protection status of the module.";
CM_ SG_ 2566850724 BMS4_ADB_M1_Module_OUT_Voltage "This parameter contains the output voltage of the module.";
CM_ SG_ 2566850724 BMS4_ADB_M1_ModuleAverageCurrent "This parameter contains the charge (positive) or discharge (negative) current of the module averaged over 1 second.";
CM_ SG_ 2566850724 BMS4_ADB_M1_Module_StateOfCharge "This parameter contains the ratio of the remaining capacity of the module to the full capacity of the module expressed as a percentage.";
CM_ SG_ 2566850724 BMS4_ADB_M1_Module_StateOfHealth "This parameter contains a value relating to the state of health of the module based on defined thresholds of the ratio of full capacity to design capacity.";
CM_ SG_ 2566850724 BMS4_ADB_M1_DiscProtectTrigg "This parameter contains the current protection status of the module.
Discharge protection triggered";
CM_ SG_ 2566850724 BMS4_ADB_M1_ChargeProtectTrigg "This parameter contains the current protection status of the module.
Charge protection triggered";
CM_ SG_ 2566850724 BMS4_ADB_M1_ModulesMissingFailed "This parameter contains the current protection status of the module.
Modules missing/failed";
CM_ SG_ 2566850724 BMS4_ADB_M1_OverTemp_detect "This parameter contains the current protection status of the module.
Over-temperature detected";
CM_ SG_ 2566850724 BMS4_ADB_M1_UnderVoltage_detect "This parameter contains the current protection status of the module.
Under-voltage detected";
CM_ SG_ 2566850724 BMS4_ADB_M1_OverVoltage_detected "This parameter contains the current protection status of the module.
Over-voltage detected";
CM_ SG_ 2566850724 BMS4_ADB_M1_Overload_detected "This parameter contains the current protection status of the module.
Overload detected";
CM_ SG_ 2566850724 BMS4_ADB_M1_ShortCircuit_detect "This parameter contains the current protection status of the module.
Short circuit detected";
CM_ SG_ 2566850724 BMS4_ADB_M1_Module_BQ78350 "This parameter contains selected data from the BQ78350 status.
Each bit indicates a different alarm (bit 1 indicates extra 1, bit 2 indicates extra 2 …) where 0 indicates no fault and 1 indicates missing, failed or protection triggered";
CM_ BO_ 2566849444 "This PGN reports the battery’s serial and firmware version numbers.";
CM_ SG_ 2566849444 BMS4_ADB_Battery_serial_number "This parameter contains the manufactured serial number of the battery. The lowest 21 bits of this 24 bit serial number are also used in the J1939 NAME – see 2.1.";
CM_ SG_ 2566849444 BMS4_ADB_FirmwareVersionMajor "This parameter contains the major number of the firmware version, i.e. where the firmware has a version XX.YY.ZZZ it represents XX.";
CM_ SG_ 2566849444 BMS4_ADB_FirmwareVersionMinor "This parameter contains the major number of the firmware version, i.e. where the firmware has a version XX.YY.ZZZ it represents YY.";
CM_ SG_ 2566849444 BMS4_ADB_Firmware_Revision "This parameter contains the major number of the firmware version, i.e. where the firmware has a version XX.YY.ZZZ it represents ZZZ.";
CM_ BO_ 2566849188 "This PGN reports the battery temperature. The battery contains a number of temperature sensors which are summarised in this PGN by reporting the maximum, the minimum and the average of all the sensors.";
CM_ SG_ 2566849188 BMS4_ADB_Maximum_Temperature "This parameter contains the highest temperature currently measured within the battery.";
CM_ SG_ 2566849188 BMS4_ADB_Minimum_Temperature "This parameter contains the lowest temperature currently measured within the battery.";
CM_ SG_ 2566849188 BMS4_ADB_Average_Temperature "This parameter contains the average of all the temperatures currently measured within the battery.";
CM_ BO_ 2566848932 "This PGN reports the remaining battery capacity, the expected full battery capacity and the designed battery capacity. If the capacity falls below a defined percentage of the design capacity, the battery enters an alarm state and broadcasts this PGN within 100ms of the event and then repeatedly at 1000ms intervals until the capacity moves above the alarm threshold.";
CM_ SG_ 2566848932 BMS4_ADB_Remaining_capacity "This parameter contains the remaining capacity of the battery.";
CM_ SG_ 2566848932 BMS4_ADB_Full_capacity "This parameter contains the full capacity of the battery.";
CM_ SG_ 2566848932 BMS4_ADB_Design_capacity "This parameter contains the design capacity of the battery.";
CM_ SG_ 2566848932 BMS4_ADB_Overall_10_alarm "This parameter contains fields indicating which, if any, capacity alarm thresholds have been triggered.
Overall – less than 10% of design capacity remaining";
CM_ SG_ 2566848932 BMS4_ADB_Silent_Watch_20_alarm "This parameter contains fields indicating which, if any, capacity alarm thresholds have been triggered.
Silent watch – less than 20% silent watch threshold";
CM_ SG_ 2566848932 BMS4_ADB_EngStartCapacity_alarm "This parameter contains fields indicating which, if any, capacity alarm thresholds have been triggered.
Engine start – capacity below engine start threshold";
CM_ SG_ 2566848932 BMS4_ADB_10_Reserved_4 "Not used";
CM_ SG_ 2566848932 BMS4_ADB_10_Reserved_5 "Not used";
CM_ SG_ 2566848932 BMS4_ADB_10_Reserved_6 "Not used";
CM_ SG_ 2566848932 BMS4_ADB_10_Reserved_7 "Not used";
CM_ SG_ 2566848932 BMS4_ADB_10_Reserved_8 "Not used";
CM_ BO_ 2566848676 "This PGN reports the normal operating parameters of the battery: output voltage, average current (charge or discharge), the percentage state of charge and a state of health indication.
The PGN is broadcast at 1000ms intervals or can be requested.";
CM_ SG_ 2566848676 BMS4_ADB_Batt_OUT_Voltage "This parameter contains the output voltage of the battery.
It only specifies the voltage of the internal modules that are available for discharge: any module which is in over-temperature or under-voltage protection is not included in this figure because it has been internally disconnected.";
CM_ SG_ 2566848676 BMS4_ADB_Batt_Average_Current "This parameter contains the charge (positive) or discharge (negative) current of the battery averaged over 1 second.";
CM_ SG_ 2566848676 BMS4_ADB_Batt_StsOfCharge "This parameter contains the ratio of the remaining capacity of the battery to the full capacity expressed as a percentage.";
CM_ SG_ 2566848676 BMS4_ADB_Batt_StsOfHealth "This parameter contains a value relating to the state of health of the battery based on defined thresholds of the ratio of full capacity to design capacity.";
CM_ SG_ 2566848676 BMS4_ADB_Batt_PS8_discharge_prot "This parameter contains the current protection status of the battery.
Discharge protection triggered.";
CM_ SG_ 2566848676 BMS4_ADB_Batt_PS7_charge_prot "This parameter contains the current protection status of the battery.
Charge protection triggered.";
CM_ SG_ 2566848676 BMS4_ADB_Batt_PS6_mod_failed "This parameter contains the current protection status of the battery.
1 or more modules missing/failed.";
CM_ SG_ 2566848676 BMS4_ADB_Batt_PS5_over_temp "This parameter contains the current protection status of the battery.
Over-temperature detected.";
CM_ SG_ 2566848676 BMS4_ADB_Batt_PS4_under_voltage "This parameter contains the current protection status of the battery.
Under-voltage detected.";
CM_ SG_ 2566848676 BMS4_ADB_Batt_PS3_over_voltage "This parameter contains the current protection status of the battery.
Over-voltage detected.";
CM_ SG_ 2566848676 BMS4_ADB_Batt_PS2_overload "This parameter contains the current protection status of the battery.
Overload detected.";
CM_ SG_ 2566848676 BMS4_ADB_Batt_PS1_short_circuit "This parameter contains the current protection status of the battery.
Short circuit detected.";
CM_ SG_ 2566848676 BMS4_ADB_Batt_OS_8_sleep_mode "This parameter contains the status bits indicating the current state of the emergency load-dump, emergency override, heater and charger controls along with the master protection status bit.
Sleep mode pending (1 = sleep pending, 0 = awake)";
CM_ SG_ 2566848676 BMS4_ADB_Batt_OS_7_emerg_used "This parameter contains the status bits indicating the current state of the emergency load-dump, emergency override, heater and charger controls along with the master protection status bit.
Emergency override used (1= used, 0 = never used)";
CM_ SG_ 2566848676 BMS4_ADB_Batt_OS_6_emergency "This parameter contains the status bits indicating the current state of the emergency load-dump, emergency override, heater and charger controls along with the master protection status bit.
Emergency override (1 = active, 0 = inactive)";
CM_ SG_ 2566848676 BMS4_ADB_Batt_OS_45_charge_level "This parameter contains the status bits indicating the current state of the emergency load-dump, emergency override, heater and charger controls along with the master protection status bit.
Charge level (0 = off, 1 = 25%, 2 = 50%, 3 = full)";
CM_ SG_ 2566848676 BMS4_ADB_Batt_OS_3_charge_cont "This parameter contains the status bits indicating the current state of the emergency load-dump, emergency override, heater and charger controls along with the master protection status bit.
Charge control (1 = on, 0 = off)";
CM_ SG_ 2566848676 BMS4_ADB_Batt_OS_2_heater_cont "This parameter contains the status bits indicating the current state of the emergency load-dump, emergency override, heater and charger controls along with the master protection status bit.
Heater control (1 = on, 0 = off)";
CM_ SG_ 2566848676 BMS4_ADB_Batt_OS_1_master_prot "This parameter contains the status bits indicating the current state of the emergency load-dump, emergency override, heater and charger controls along with the master protection status bit.
Master protect (1 = protect, 0 = off)";
CM_ BO_ 2566804132 "This contains high resolution/range parameters reported from the alternator or power generation components.";
CM_ SG_ 2566804132 _nu_BMS4_ADB_AlternatorCurrent "SPN 1795 Alternator Current (High Range/Resolution)
This parameter indicates the amount of electrical current output from the alternator of the main vehicle. Alternator Current
(SPN 115) has a lower range and resolution.";
CM_ SG_ 2566804132 BMS4_ADB_NetBattery_Current "SPN 2579 Net Battery Current (High Range/Resolution)
Net flow of electrical current into/out-of the battery or batteries. This parameter is the high range and resolution of SPN
114 - Net Battery Current.";
CM_ BO_ 2566803620 "Contains battery temperature information.";
CM_ SG_ 2566803620 BMS4_ADB_Battery1_Temperature "Temperature of the battery 1. The relation to physical location is determined by the equipment manufacturer.";
CM_ SG_ 2566803620 _nu_BMS4_ADB_Battery2_Temp "Temperature of the battery 2. The relation to physical location is determined by the equipment manufacturer.";
CM_ BO_ 2566698660 "PGN containing vehicle electrical power information for the battery pack used for starting, lighting, and ignition.";
CM_ SG_ 2566698660 BMS4_ADB_SLI_BattPack_StOfCharge "5981
SLI Battery Pack State of Charge
Indicates the remaining charge of the battery pack used for starting the engine, for lighting, and for ignition (SLI). 0% means no charge remaining, 100% means full capacity at the battery pack's current state of health.   See SPN 5464 for hybrid battery pack.";
CM_ SG_ 2566698660 BMS4_ADB_SLI_BattPack_Capacity "5982
SLI Battery Pack Capacity
Original or rated total reserve capacity of the battery pack used for starting the engine, for lighting, and for ignition (SLI).";
CM_ SG_ 2566698660 BMS4_ADB_SLI_BattPack_Health "5983
SLI Battery Pack Health
Capacity of the battery pack relative to its original specification for the battery pack used for starting the engine, for lighting, and for ignition (SLI). 0% means battery pack is not capable of holding any charge, 100% means battery pack is capable of holding its original full capacity.";
CM_ BO_ 2566862244 "This PGN reports the total number of software-related events that have occurred during the life of the battery.";
CM_ SG_ 2566862244 BMS4_ADB_HardMCLRReset_events "This parameter contains a count of the number times the MCLR has reset the firmware due to a hardware reset pulse, this may be due to the external watchdog.
Data Range: 0 – 64255. A value of 64255 indicates 64255 events or more.";
CM_ SG_ 2566862244 BMS4_ADB_LowVoltageReset_events "TThis parameter contains a count of the number times the firmware has been reset due to the processor detecting a low supply voltage.
Data Range: 0 – 64255. A value of 64255 indicates 64255 events or more.";
CM_ SG_ 2566862244 BMS4_ADB_PORReset_events "This parameter contains a count of the number times the firmware has been started from a power up condition.
Data Range: 0 – 64255. A value of 64255 indicates 64255 events or more.";
CM_ SG_ 2566862244 BMS4_ADB_BrownOutReset_events "This parameter contains a count of the number times the firmware has been restarted due to a brown-out (below 2.7V).
Data Range: 0 – 64255. A value of 64255 indicates 64255 events or more.";
CM_ BO_ 2565799844 "Generic message for send the NAME
Used only for the BMS4";
CM_ SG_ 2565799844 BMS4_ADB_VehicleSystemInstance "Vehicle System Instance";
CM_ SG_ 2565799844 BMS4_ADB_IndustryGroup "Industry Group";
CM_ SG_ 2565799844 BMS4_ADB_Name_Reserved "Reserved";
CM_ SG_ 2565799844 BMS4_ADB_ECUInstance "ECU Instance";
CM_ SG_ 2565799844 BMS4_ADB_IdentityNumber_3 "Most significant 5 bits of Identity Number";
CM_ SG_ 2565799844 BMS4_ADB_ArbitraryAddressCapable "Arbitrary Address Capable";
CM_ SG_ 2565799844 BMS4_ADB_VehicleSystem "Vehicle System";
CM_ SG_ 2565799844 BMS4_ADB_Function "Function";
CM_ SG_ 2565799844 BMS4_ADB_FunctionInstance "Function Instance";
CM_ SG_ 2565799844 BMS4_ADB_ManufacturerCode_2 "Most significant 8 bits of Manufacturer Code";
CM_ SG_ 2565799844 BMS4_ADB_ManufacturerCode_1 "Least significant 3 bits of Manufacturer Code";
CM_ SG_ 2565799844 BMS4_ADB_IdentityNumber_2 "Second byte of Identity Number";
CM_ SG_ 2565799844 BMS4_ADB_IdentityNumber_1 "Least significant byte of Identity Number";
CM_ BO_ 2566849957 "This PGN reports a summary of the the operating parameters of the full battery: serial number, state of charge, state of health, temperature alarm, voltage alarm for the battery.";
CM_ SG_ 2566849957 BMS5_ADB_BatSumS_serial_number "This parameter contains the manufactured serial number of the battery. The lowest 21 bits of this 24 bit serial number are also used in the J1939 NAME – see 2.1.";
CM_ SG_ 2566849957 BMS5_ADB_BatSumS_Reserved_01 "Reserved";
CM_ SG_ 2566849957 BMS5_ADB_BatSumS_State_of_Charge "This parameter contains the ratio of the remaining capacity of the battery to the full capacity expressed as a percentage.";
CM_ SG_ 2566849957 BMS5_ADB_BatSumS_State_of_Health "This parameter contains a value relating to the state of health of the battery based on defined thresholds of the ratio of full capacity to design capacity.";
CM_ SG_ 2566849957 BMS5_ADB_BatSumS_Temp_Alarm "This parameter contains the temperature alarm, based on the maximum battery temperature.
0x00: No fault;
0x01: Low Temperature Alarm
0x02: High Temperature Alarm
0x03: Wrong Temperature Alarm";
CM_ SG_ 2566849957 BMS5_ADB_BatSumS_DischargeDis "This parameter indicates when the battery is not able to be discharged.
0x00: Discharge Enable;
0x01: Discharge Disable";
CM_ SG_ 2566849957 BMS5_ADB_BatSumS_ChargingDisable "This parameter indicates when the battery is not able to be discharged.
0x00: Charging Enable;
0x01: Charging Disable";
CM_ SG_ 2566849957 BMS5_ADB_BatSumS_HeaterEnabled "This parameter indicates when the heater is enabled.
0x00: Heater Disabled;
0x01: Heater Enabled";
CM_ SG_ 2566849957 BMS5_ADB_BatSumS_BypassEnabled "This parameter indicates when the bypass is enabled.
0x00: Bypass Disabled;
0x01: Bypass Enabled";
CM_ SG_ 2566849957 BMS5_ADB_BatSumS_Voltage_Alarm "This parameter indicates an over voltage condition in one or more modules.
0x00: No fault;
0x01:Over Voltage Alarm";
CM_ SG_ 2566849957 BMS5_ADB_BatSumS_Reserved_04 "Reserved";
CM_ SG_ 2566849957 BMS5_ADB_BatSumS_Reserved_05 "Reserved";
CM_ SG_ 2566849957 BMS5_ADB_BatSumS_Reserved_06 "Reserved";
CM_ SG_ 2566849957 BMS5_ADB_BatSumS_Reserved_07 "Reserved";
CM_ SG_ 2566849957 BMS5_ADB_BatSumS_Reserved_08 "Reserved";
CM_ SG_ 2566849957 BMS5_ADB_BatSumS_Reserved_09 "Reserved";
CM_ SG_ 2566849957 BMS5_ADB_BatSumS_Reserved_10 "Reserved";
CM_ SG_ 2566849957 BMS5_ADB_BatSumS_Reserved_11 "Reserved";
CM_ BO_ 2566849701 "Used for debugging purposes.";
CM_ SG_ 2566849701 BMS5_ADB_Debug_0 "Used for debugging purpose - byte 0";
CM_ SG_ 2566849701 BMS5_ADB_Debug_1 "Used for debugging purpose - byte 1";
CM_ SG_ 2566849701 BMS5_ADB_Debug_2 "Used for debugging purpose - byte 2";
CM_ SG_ 2566849701 BMS5_ADB_Debug_3 "Used for debugging purpose - byte 3";
CM_ SG_ 2566849701 BMS5_ADB_Debug_4 "Used for debugging purpose - byte 4";
CM_ SG_ 2566849701 BMS5_ADB_Debug_5 "Used for debugging purpose - byte 5";
CM_ SG_ 2566849701 BMS5_ADB_Debug_6 "Used for debugging purpose - byte 6";
CM_ SG_ 2566849701 BMS5_ADB_Debug_7 "Used for debugging purpose - byte 7";
CM_ BO_ 2566853285 "This PGN reports the remaining module capacity, the expected full module capacity and the designed module capacity for module 3.";
CM_ SG_ 2566853285 BMS5_ADB_M1_Remaining_capacity "This parameter contains the remaining capacity of the battery.";
CM_ SG_ 2566853285 BMS5_ADB_M1_Full_capacity "This parameter contains the full capacity of the battery.";
CM_ SG_ 2566853285 BMS5_ADB_M1_Design_capacity "This parameter contains the design capacity of the battery.";
CM_ SG_ 2566853285 BMS5_ADB_M1_Reserved_Cap "Reserved";
CM_ BO_ 2566853029 "This PGN reports the remaining module capacity, the expected full module capacity and the designed module capacity for module 2.";
CM_ SG_ 2566853029 BMS5_ADB_M2_Remaining_capacity "This parameter contains the remaining capacity of the battery.";
CM_ SG_ 2566853029 BMS5_ADB_M2_Full_capacity "This parameter contains the full capacity of the battery.";
CM_ SG_ 2566853029 BMS5_ADB_M2_Design_capacity "This parameter contains the design capacity of the battery.";
CM_ SG_ 2566853029 BMS5_ADB_M2_Reserved_Cap "Reserved";
CM_ BO_ 2566852773 "This PGN reports the remaining module capacity, the expected full module capacity and the designed module capacity for module 1.";
CM_ SG_ 2566852773 BMS5_ADB_M3_Remaining_capacity "This parameter contains the remaining capacity of the battery.";
CM_ SG_ 2566852773 BMS5_ADB_M3_Full_capacity "This parameter contains the full capacity of the battery.";
CM_ SG_ 2566852773 BMS5_ADB_M3_Design_capacity "This parameter contains the design capacity of the battery.";
CM_ SG_ 2566852773 BMS5_ADB_M3_Reserved_Cap "Reserved";
CM_ BO_ 2566861989 "This PGN reports the total number of software-related events that have occurred during the life of the battery.";
CM_ SG_ 2566861989 BMS5_ADB_WatchdogReset_events "This parameter contains a count of the number times the watchdog has reset the firmware due to an internal lock-up.
Data Range: 0 – 64255. A value of 64255 indicates 64255 events or more.";
CM_ SG_ 2566861989 BMS5_ADB_StackOverflowReset_even "This parameter contains a count of the number times the firmware has been reset due to a stack-overflow.
Data Range: 0 – 64255. A value of 64255 indicates 64255 events or more.";
CM_ SG_ 2566861989 BMS5_ADB_CommandedReset_events "This parameter contains a count of the number times the firmware has been reset by a CAN, USB or status button command.
Data Range: 0 – 64255. A value of 64255 indicates 64255 events or more.";
CM_ SG_ 2566861989 BMS5_ADB_IllegalInstructionReset "This parameter contains a count of the number times the firmware has been hard-reset using the status button.
Data Range: 0 – 64255. A value of 64255 indicates 64255 events or more.";
CM_ BO_ 2566861733 "This PGN reports the total number of voltage-related events that have occurred during the life of the battery.";
CM_ SG_ 2566861733 BMS5_ADB_OverVoltage_events "This parameter contains a count of the number of times an over-voltage event has occurred.";
CM_ SG_ 2566861733 BMS5_ADB_UnderVoltage_events "This parameter contains a count of the number of times an under-voltage event has occurred.";
CM_ BO_ 2566861477 "This PGN reports the total number of current and temperature-related events that have occurred during the life of the battery.";
CM_ SG_ 2566861477 BMS5_ADB_ShortCircuit_events "This parameter contains a count of the number of times the battery has been short-circuited.";
CM_ SG_ 2566861477 BMS5_ADB_CurrentOverload_events "This parameter contains a count of the number of times the battery has been overloaded.";
CM_ SG_ 2566861477 BMS5_ADB_OverCurrent_Charge_ev "This parameter contains a count of the number of times the battery’s maximum charge current has been exceeded.";
CM_ SG_ 2566861477 BMS5_ADB_OverTemperature_ev "This parameter contains a count of the number of times the battery’s maximum temperature has been exceeded.";
CM_ BO_ 2566861221 "This PGN reports on the maximum and minimum battery voltages and currents measured during the life of the battery.";
CM_ SG_ 2566861221 BMS5_ADB_MaximumVoltage "This parameter contains the maximum voltage ever measured across the battery cells.";
CM_ SG_ 2566861221 BMS5_ADB_MinimumVoltage "This parameter contains the minimum voltage ever measured across the battery cells.";
CM_ SG_ 2566861221 BMS5_ADB_MAX_Discharge_Current "This parameter contains the maximum discharge current ever measured on the battery.";
CM_ SG_ 2566861221 BMS5_ADB_MAX_Charge_Current "This parameter contains the maximum charge current ever measured on the battery.";
CM_ BO_ 2566860965 "This PGN reports on the maximum and minimum temperatures experienced during the life of the battery.";
CM_ SG_ 2566860965 BMS5_ADB_Maximum_Life_temp "This parameter contains the maximum temperature ever measured in the battery.";
CM_ SG_ 2566860965 BMS5_ADB_Minimum_Life_temp "This parameter contains the minimum temperature ever measured in the battery.";
CM_ SG_ 2566860965 BMS5_ADB_MAX_Charging_Temp "This parameter contains the maximum temperature ever measured while charging the battery.";
CM_ SG_ 2566860965 BMS5_ADB_MIN_Charging_Temp "This parameter contains the minimum temperature ever measured while charging the battery.";
CM_ BO_ 2566857381 "This PGN reports on the individual discharge switch temperatures within module 3 of the battery. The values are only valid when the discharge current exceeds 10A for the entire battery, at other times the values returned will be the J1939 unavailable value.";
CM_ SG_ 2566857381 BMS5_ADB_M3_Temperature_1 "This parameter contains the temperature of a discharge switch sensor.";
CM_ SG_ 2566857381 BMS5_ADB_M3_Temperature_2 "This parameter contains the temperature of a discharge switch sensor.";
CM_ SG_ 2566857381 BMS5_ADB_M3_Temperature_3 "This parameter contains the temperature of a discharge switch sensor.";
CM_ SG_ 2566857381 BMS5_ADB_M3_Reserved_Dis1 "Reserved";
CM_ SG_ 2566857381 BMS5_ADB_M3_Reserved_Dis2 "Reserved";
CM_ BO_ 2566857125 "This PGN reports on the individual discharge switch temperatures within module 2 of the battery. The values are only valid when the discharge current exceeds 10A for the entire battery, at other times the values returned will be the J1939 unavailable value.";
CM_ SG_ 2566857125 BMS5_ADB_M2_Temperature_1 "This parameter contains the temperature of a discharge switch sensor.";
CM_ SG_ 2566857125 BMS5_ADB_M2_Temperature_2 "This parameter contains the temperature of a discharge switch sensor.";
CM_ SG_ 2566857125 BMS5_ADB_M2_Temperature_3 "This parameter contains the temperature of a discharge switch sensor.";
CM_ SG_ 2566857125 BMS5_ADB_M2_Reserved_Dis1 "Reserved";
CM_ SG_ 2566857125 BMS5_ADB_M2_Reserved_Dis2 "Reserved";
CM_ BO_ 2566856869 "This PGN reports on the individual discharge switch temperatures within module 1 of the battery. The values are only valid when the discharge current exceeds 10A for the entire battery, at other times the values returned will be the J1939 unavailable value.";
CM_ SG_ 2566856869 BMS5_ADB_M1_Temperature_1 "This parameter contains the temperature of a discharge switch sensor.";
CM_ SG_ 2566856869 BMS5_ADB_M1_Temperature_2 "This parameter contains the temperature of a discharge switch sensor.";
CM_ SG_ 2566856869 BMS5_ADB_M1_Temperature_3 "This parameter contains the temperature of a discharge switch sensor.";
CM_ SG_ 2566856869 BMS5_ADB_M1_Reserved_Dis1 "Reserved";
CM_ SG_ 2566856869 BMS5_ADB_M1_Reserved_Dis2 "Reserved";
CM_ BO_ 2566855333 "This PGN reports on the individual temperatures measured within module 3 of the battery.";
CM_ SG_ 2566855333 BMS5_ADB_M3_FuelGauge1_Temp "This parameter contains the temperature measured by the module’s fuel gauge IC.";
CM_ SG_ 2566855333 BMS5_ADB_M3_Thermistor1_temp "This parameter contains the temperature measured by one of the module’s Thermistors.";
CM_ SG_ 2566855333 BMS5_ADB_M3_Thermistor2_temp "This parameter contains the temperature measured by one of the module’s Thermistors.";
CM_ SG_ 2566855333 BMS5_ADB_M3_FuelGauge2_Temp "This parameter contains the temperature measured by the module’s fuel gauge IC.";
CM_ BO_ 2566855077 "This PGN reports on the individual temperatures measured within module 2 of the battery.";
CM_ SG_ 2566855077 BMS5_ADB_M2_FuelGauge1_Temp "This parameter contains the temperature measured by the module’s fuel gauge IC.";
CM_ SG_ 2566855077 BMS5_ADB_M2_Thermistor1_temp "This parameter contains the temperature measured by one of the module’s Thermistors.";
CM_ SG_ 2566855077 BMS5_ADB_M2_Thermistor2_temp "This parameter contains the temperature measured by one of the module’s Thermistors.";
CM_ SG_ 2566855077 BMS5_ADB_M2_FuelGauge2_Temp "This parameter contains the temperature measured by the module’s fuel gauge IC.";
CM_ BO_ 2566854821 "This PGN reports on the individual temperatures measured within module 1 of the battery.";
CM_ SG_ 2566854821 BMS5_ADB_M1_FuelGauge1_Temp "This parameter contains the temperature measured by the module’s fuel gauge IC.";
CM_ SG_ 2566854821 BMS5_ADB_M1_Thermistor1_temp "This parameter contains the temperature measured by one of the module’s Thermistors.";
CM_ SG_ 2566854821 BMS5_ADB_M1_Thermistor2_temp "This parameter contains the temperature measured by one of the module’s Thermistors.";
CM_ SG_ 2566854821 BMS5_ADB_M1_FuelGauge2_Temp "This parameter contains the temperature measured by the module’s fuel gauge IC.";
CM_ BO_ 2566851237 "This PGN reports the operating parameters of module 3 within the battery: output voltage, average current (charge or discharge), the percentage state of charge, a state of health indication and the protection status of the module.";
CM_ SG_ 2566851237 BMS5_ADB_M3_Module_OUT_Voltage "This parameter contains the output voltage of the module.";
CM_ SG_ 2566851237 BMS5_ADB_M3_ModuleAverageCurrent "This parameter contains the charge (positive) or discharge (negative) current of the module averaged over 1 second.";
CM_ SG_ 2566851237 BMS5_ADB_M3_Module_StateOfCharge "This parameter contains the ratio of the remaining capacity of the module to the full capacity of the module expressed as a percentage.";
CM_ SG_ 2566851237 BMS5_ADB_M3_Module_StateOfHealth "This parameter contains a value relating to the state of health of the module based on defined thresholds of the ratio of full capacity to design capacity.";
CM_ SG_ 2566851237 BMS5_ADB_M3_DiscProtectTrigg "This parameter contains the current protection status of the module.
Discharge protection triggered";
CM_ SG_ 2566851237 BMS5_ADB_M3_ChargeProtectTrigg "This parameter contains the current protection status of the module.
Charge protection triggered";
CM_ SG_ 2566851237 BMS5_ADB_M3_ModulesMissingFailed "This parameter contains the current protection status of the module.
Modules missing/failed";
CM_ SG_ 2566851237 BMS5_ADB_M3_OverTemp_detect "This parameter contains the current protection status of the module.
Over-temperature detected";
CM_ SG_ 2566851237 BMS5_ADB_M3_UnderVoltage_detect "This parameter contains the current protection status of the module.
Under-voltage detected";
CM_ SG_ 2566851237 BMS5_ADB_M3_OverVoltage_detected "This parameter contains the current protection status of the module.
Over-voltage detected";
CM_ SG_ 2566851237 BMS5_ADB_M3_Overload_detected "This parameter contains the current protection status of the module.
Overload detected";
CM_ SG_ 2566851237 BMS5_ADB_M3_ShortCircuit_detect "This parameter contains the current protection status of the module.
Short circuit detected";
CM_ SG_ 2566851237 BMS5_ADB_M3_Module_BQ78350 "This parameter contains selected data from the BQ78350 status.
Each bit indicates a different alarm (bit 1 indicates extra 1, bit 2 indicates extra 2 …) where 0 indicates no fault and 1 indicates missing, failed or protection triggered";
CM_ BO_ 2566850981 "This PGN reports the operating parameters of module 2 within the battery: output voltage, average current (charge or discharge), the percentage state of charge, a state of health indication and the protection status of the module.";
CM_ SG_ 2566850981 BMS5_ADB_M2_Module_OUT_Voltage "This parameter contains the output voltage of the module.";
CM_ SG_ 2566850981 BMS5_ADB_M2_ModuleAverageCurrent "This parameter contains the charge (positive) or discharge (negative) current of the module averaged over 1 second.";
CM_ SG_ 2566850981 BMS5_ADB_M2_Module_StateOfCharge "This parameter contains the ratio of the remaining capacity of the module to the full capacity of the module expressed as a percentage.";
CM_ SG_ 2566850981 BMS5_ADB_M2_Module_StateOfHealth "This parameter contains a value relating to the state of health of the module based on defined thresholds of the ratio of full capacity to design capacity.";
CM_ SG_ 2566850981 BMS5_ADB_M2_DiscProtectTrigg "This parameter contains the current protection status of the module.
Discharge protection triggered";
CM_ SG_ 2566850981 BMS5_ADB_M2_ChargeProtectTrigg "This parameter contains the current protection status of the module.
Charge protection triggered";
CM_ SG_ 2566850981 BMS5_ADB_M2_ModulesMissingFailed "This parameter contains the current protection status of the module.
Modules missing/failed";
CM_ SG_ 2566850981 BMS5_ADB_M2_OverTemp_detect "This parameter contains the current protection status of the module.
Over-temperature detected";
CM_ SG_ 2566850981 BMS5_ADB_M2_UnderVoltage_detect "This parameter contains the current protection status of the module.
Under-voltage detected";
CM_ SG_ 2566850981 BMS5_ADB_M2_OverVoltage_detected "This parameter contains the current protection status of the module.
Over-voltage detected";
CM_ SG_ 2566850981 BMS5_ADB_M2_Overload_detected "This parameter contains the current protection status of the module.
Overload detected";
CM_ SG_ 2566850981 BMS5_ADB_M2_ShortCircuit_detect "This parameter contains the current protection status of the module.
Short circuit detected";
CM_ SG_ 2566850981 BMS5_ADB_M2_Module_BQ78350 "This parameter contains selected data from the BQ78350 status.
Each bit indicates a different alarm (bit 1 indicates extra 1, bit 2 indicates extra 2 …) where 0 indicates no fault and 1 indicates missing, failed or protection triggered";
CM_ BO_ 2566850725 "This PGN reports the operating parameters of module 1 within the battery: output voltage, average current (charge or discharge), the percentage state of charge, a state of health indication and the protection status of the module.";
CM_ SG_ 2566850725 BMS5_ADB_M1_Module_OUT_Voltage "This parameter contains the output voltage of the module.";
CM_ SG_ 2566850725 BMS5_ADB_M1_ModuleAverageCurrent "This parameter contains the charge (positive) or discharge (negative) current of the module averaged over 1 second.";
CM_ SG_ 2566850725 BMS5_ADB_M1_Module_StateOfCharge "This parameter contains the ratio of the remaining capacity of the module to the full capacity of the module expressed as a percentage.";
CM_ SG_ 2566850725 BMS5_ADB_M1_Module_StateOfHealth "This parameter contains a value relating to the state of health of the module based on defined thresholds of the ratio of full capacity to design capacity.";
CM_ SG_ 2566850725 BMS5_ADB_M1_DiscProtectTrigg "This parameter contains the current protection status of the module.
Discharge protection triggered";
CM_ SG_ 2566850725 BMS5_ADB_M1_ChargeProtectTrigg "This parameter contains the current protection status of the module.
Charge protection triggered";
CM_ SG_ 2566850725 BMS5_ADB_M1_ModulesMissingFailed "This parameter contains the current protection status of the module.
Modules missing/failed";
CM_ SG_ 2566850725 BMS5_ADB_M1_OverTemp_detect "This parameter contains the current protection status of the module.
Over-temperature detected";
CM_ SG_ 2566850725 BMS5_ADB_M1_UnderVoltage_detect "This parameter contains the current protection status of the module.
Under-voltage detected";
CM_ SG_ 2566850725 BMS5_ADB_M1_OverVoltage_detected "This parameter contains the current protection status of the module.
Over-voltage detected";
CM_ SG_ 2566850725 BMS5_ADB_M1_Overload_detected "This parameter contains the current protection status of the module.
Overload detected";
CM_ SG_ 2566850725 BMS5_ADB_M1_ShortCircuit_detect "This parameter contains the current protection status of the module.
Short circuit detected";
CM_ SG_ 2566850725 BMS5_ADB_M1_Module_BQ78350 "This parameter contains selected data from the BQ78350 status.
Each bit indicates a different alarm (bit 1 indicates extra 1, bit 2 indicates extra 2 …) where 0 indicates no fault and 1 indicates missing, failed or protection triggered";
CM_ BO_ 2566849445 "This PGN reports the battery’s serial and firmware version numbers.";
CM_ SG_ 2566849445 BMS5_ADB_Battery_serial_number "This parameter contains the manufactured serial number of the battery. The lowest 21 bits of this 24 bit serial number are also used in the J1939 NAME – see 2.1.";
CM_ SG_ 2566849445 BMS5_ADB_FirmwareVersionMajor "This parameter contains the major number of the firmware version, i.e. where the firmware has a version XX.YY.ZZZ it represents XX.";
CM_ SG_ 2566849445 BMS5_ADB_FirmwareVersionMinor "This parameter contains the major number of the firmware version, i.e. where the firmware has a version XX.YY.ZZZ it represents YY.";
CM_ SG_ 2566849445 BMS5_ADB_Firmware_Revision "This parameter contains the major number of the firmware version, i.e. where the firmware has a version XX.YY.ZZZ it represents ZZZ.";
CM_ BO_ 2566849189 "This PGN reports the battery temperature. The battery contains a number of temperature sensors which are summarised in this PGN by reporting the maximum, the minimum and the average of all the sensors.";
CM_ SG_ 2566849189 BMS5_ADB_Maximum_Temperature "This parameter contains the highest temperature currently measured within the battery.";
CM_ SG_ 2566849189 BMS5_ADB_Minimum_Temperature "This parameter contains the lowest temperature currently measured within the battery.";
CM_ SG_ 2566849189 BMS5_ADB_Average_Temperature "This parameter contains the average of all the temperatures currently measured within the battery.";
CM_ BO_ 2566848933 "This PGN reports the remaining battery capacity, the expected full battery capacity and the designed battery capacity. If the capacity falls below a defined percentage of the design capacity, the battery enters an alarm state and broadcasts this PGN within 100ms of the event and then repeatedly at 1000ms intervals until the capacity moves above the alarm threshold.";
CM_ SG_ 2566848933 BMS5_ADB_Remaining_capacity "This parameter contains the remaining capacity of the battery.";
CM_ SG_ 2566848933 BMS5_ADB_Full_capacity "This parameter contains the full capacity of the battery.";
CM_ SG_ 2566848933 BMS5_ADB_Design_capacity "This parameter contains the design capacity of the battery.";
CM_ SG_ 2566848933 BMS5_ADB_Overall_10_alarm "This parameter contains fields indicating which, if any, capacity alarm thresholds have been triggered.
Overall – less than 10% of design capacity remaining";
CM_ SG_ 2566848933 BMS5_ADB_Silent_Watch_20_alarm "This parameter contains fields indicating which, if any, capacity alarm thresholds have been triggered.
Silent watch – less than 20% silent watch threshold";
CM_ SG_ 2566848933 BMS5_ADB_EngStartCapacity_alarm "This parameter contains fields indicating which, if any, capacity alarm thresholds have been triggered.
Engine start – capacity below engine start threshold";
CM_ SG_ 2566848933 BMS5_ADB_10_Reserved_4 "Not used";
CM_ SG_ 2566848933 BMS5_ADB_10_Reserved_5 "Not used";
CM_ SG_ 2566848933 BMS5_ADB_10_Reserved_6 "Not used";
CM_ SG_ 2566848933 BMS5_ADB_10_Reserved_7 "Not used";
CM_ SG_ 2566848933 BMS5_ADB_10_Reserved_8 "Not used";
CM_ BO_ 2566848677 "This PGN reports the normal operating parameters of the battery: output voltage, average current (charge or discharge), the percentage state of charge and a state of health indication.
The PGN is broadcast at 1000ms intervals or can be requested.";
CM_ SG_ 2566848677 BMS5_ADB_Batt_OUT_Voltage "This parameter contains the output voltage of the battery.
It only specifies the voltage of the internal modules that are available for discharge: any module which is in over-temperature or under-voltage protection is not included in this figure because it has been internally disconnected.";
CM_ SG_ 2566848677 BMS5_ADB_Batt_Average_Current "This parameter contains the charge (positive) or discharge (negative) current of the battery averaged over 1 second.";
CM_ SG_ 2566848677 BMS5_ADB_Batt_StsOfCharge "This parameter contains the ratio of the remaining capacity of the battery to the full capacity expressed as a percentage.";
CM_ SG_ 2566848677 BMS5_ADB_Batt_StsOfHealth "This parameter contains a value relating to the state of health of the battery based on defined thresholds of the ratio of full capacity to design capacity.";
CM_ SG_ 2566848677 BMS5_ADB_Batt_PS8_discharge_prot "This parameter contains the current protection status of the battery.
Discharge protection triggered.";
CM_ SG_ 2566848677 BMS5_ADB_Batt_PS7_charge_prot "This parameter contains the current protection status of the battery.
Charge protection triggered.";
CM_ SG_ 2566848677 BMS5_ADB_Batt_PS6_mod_failed "This parameter contains the current protection status of the battery.
1 or more modules missing/failed.";
CM_ SG_ 2566848677 BMS5_ADB_Batt_PS5_over_temp "This parameter contains the current protection status of the battery.
Over-temperature detected.";
CM_ SG_ 2566848677 BMS5_ADB_Batt_PS4_under_voltage "This parameter contains the current protection status of the battery.
Under-voltage detected.";
CM_ SG_ 2566848677 BMS5_ADB_Batt_PS3_over_voltage "This parameter contains the current protection status of the battery.
Over-voltage detected.";
CM_ SG_ 2566848677 BMS5_ADB_Batt_PS2_overload "This parameter contains the current protection status of the battery.
Overload detected.";
CM_ SG_ 2566848677 BMS5_ADB_Batt_PS1_short_circuit "This parameter contains the current protection status of the battery.
Short circuit detected.";
CM_ SG_ 2566848677 BMS5_ADB_Batt_OS_8_sleep_mode "This parameter contains the status bits indicating the current state of the emergency load-dump, emergency override, heater and charger controls along with the master protection status bit.
Sleep mode pending (1 = sleep pending, 0 = awake)";
CM_ SG_ 2566848677 BMS5_ADB_Batt_OS_7_emerg_used "This parameter contains the status bits indicating the current state of the emergency load-dump, emergency override, heater and charger controls along with the master protection status bit.
Emergency override used (1= used, 0 = never used)";
CM_ SG_ 2566848677 BMS5_ADB_Batt_OS_6_emergency "This parameter contains the status bits indicating the current state of the emergency load-dump, emergency override, heater and charger controls along with the master protection status bit.
Emergency override (1 = active, 0 = inactive)";
CM_ SG_ 2566848677 BMS5_ADB_Batt_OS_45_charge_level "This parameter contains the status bits indicating the current state of the emergency load-dump, emergency override, heater and charger controls along with the master protection status bit.
Charge level (0 = off, 1 = 25%, 2 = 50%, 3 = full)";
CM_ SG_ 2566848677 BMS5_ADB_Batt_OS_3_charge_cont "This parameter contains the status bits indicating the current state of the emergency load-dump, emergency override, heater and charger controls along with the master protection status bit.
Charge control (1 = on, 0 = off)";
CM_ SG_ 2566848677 BMS5_ADB_Batt_OS_2_heater_cont "This parameter contains the status bits indicating the current state of the emergency load-dump, emergency override, heater and charger controls along with the master protection status bit.
Heater control (1 = on, 0 = off)";
CM_ SG_ 2566848677 BMS5_ADB_Batt_OS_1_master_prot "This parameter contains the status bits indicating the current state of the emergency load-dump, emergency override, heater and charger controls along with the master protection status bit.
Master protect (1 = protect, 0 = off)";
CM_ BO_ 2566804133 "This contains high resolution/range parameters reported from the alternator or power generation components.";
CM_ SG_ 2566804133 _nu_BMS5_ADB_AlternatorCurrent "SPN 1795 Alternator Current (High Range/Resolution)
This parameter indicates the amount of electrical current output from the alternator of the main vehicle. Alternator Current
(SPN 115) has a lower range and resolution.";
CM_ SG_ 2566804133 BMS5_ADB_NetBattery_Current "SPN 2579 Net Battery Current (High Range/Resolution)
Net flow of electrical current into/out-of the battery or batteries. This parameter is the high range and resolution of SPN
114 - Net Battery Current.";
CM_ BO_ 2566803621 "Contains battery temperature information.";
CM_ SG_ 2566803621 BMS5_ADB_Battery1_Temperature "Temperature of the battery 1. The relation to physical location is determined by the equipment manufacturer.";
CM_ SG_ 2566803621 _nu_BMS5_ADB_Battery2_Temp "Temperature of the battery 2. The relation to physical location is determined by the equipment manufacturer.";
CM_ BO_ 2566698661 "PGN containing vehicle electrical power information for the battery pack used for starting, lighting, and ignition.";
CM_ SG_ 2566698661 BMS5_ADB_SLI_BattPack_StOfCharge "5981
SLI Battery Pack State of Charge
Indicates the remaining charge of the battery pack used for starting the engine, for lighting, and for ignition (SLI). 0% means no charge remaining, 100% means full capacity at the battery pack's current state of health.   See SPN 5464 for hybrid battery pack.";
CM_ SG_ 2566698661 BMS5_ADB_SLI_BattPack_Capacity "5982
SLI Battery Pack Capacity
Original or rated total reserve capacity of the battery pack used for starting the engine, for lighting, and for ignition (SLI).";
CM_ SG_ 2566698661 BMS5_ADB_SLI_BattPack_Health "5983
SLI Battery Pack Health
Capacity of the battery pack relative to its original specification for the battery pack used for starting the engine, for lighting, and for ignition (SLI). 0% means battery pack is not capable of holding any charge, 100% means battery pack is capable of holding its original full capacity.";
CM_ BO_ 2566862245 "This PGN reports the total number of software-related events that have occurred during the life of the battery.";
CM_ SG_ 2566862245 BMS5_ADB_HardMCLRReset_events "This parameter contains a count of the number times the MCLR has reset the firmware due to a hardware reset pulse, this may be due to the external watchdog.
Data Range: 0 – 64255. A value of 64255 indicates 64255 events or more.";
CM_ SG_ 2566862245 BMS5_ADB_LowVoltageReset_events "TThis parameter contains a count of the number times the firmware has been reset due to the processor detecting a low supply voltage.
Data Range: 0 – 64255. A value of 64255 indicates 64255 events or more.";
CM_ SG_ 2566862245 BMS5_ADB_PORReset_events "This parameter contains a count of the number times the firmware has been started from a power up condition.
Data Range: 0 – 64255. A value of 64255 indicates 64255 events or more.";
CM_ SG_ 2566862245 BMS5_ADB_BrownOutReset_events "This parameter contains a count of the number times the firmware has been restarted due to a brown-out (below 2.7V).
Data Range: 0 – 64255. A value of 64255 indicates 64255 events or more.";
CM_ BO_ 2565799845 "Generic message for send the NAME
Used only for the BMS5";
CM_ SG_ 2565799845 BMS5_ADB_VehicleSystemInstance "Vehicle System Instance";
CM_ SG_ 2565799845 BMS5_ADB_IndustryGroup "Industry Group";
CM_ SG_ 2565799845 BMS5_ADB_Name_Reserved "Reserved";
CM_ SG_ 2565799845 BMS5_ADB_ECUInstance "ECU Instance";
CM_ SG_ 2565799845 BMS5_ADB_IdentityNumber_3 "Most significant 5 bits of Identity Number";
CM_ SG_ 2565799845 BMS5_ADB_ArbitraryAddressCapable "Arbitrary Address Capable";
CM_ SG_ 2565799845 BMS5_ADB_VehicleSystem "Vehicle System";
CM_ SG_ 2565799845 BMS5_ADB_Function "Function";
CM_ SG_ 2565799845 BMS5_ADB_FunctionInstance "Function Instance";
CM_ SG_ 2565799845 BMS5_ADB_ManufacturerCode_2 "Most significant 8 bits of Manufacturer Code";
CM_ SG_ 2565799845 BMS5_ADB_ManufacturerCode_1 "Least significant 3 bits of Manufacturer Code";
CM_ SG_ 2565799845 BMS5_ADB_IdentityNumber_2 "Second byte of Identity Number";
CM_ SG_ 2565799845 BMS5_ADB_IdentityNumber_1 "Least significant byte of Identity Number";
CM_ BO_ 2566849958 "This PGN reports a summary of the the operating parameters of the full battery: serial number, state of charge, state of health, temperature alarm, voltage alarm for the battery.";
CM_ SG_ 2566849958 BMS6_ADB_BatSumS_serial_number "This parameter contains the manufactured serial number of the battery. The lowest 21 bits of this 24 bit serial number are also used in the J1939 NAME – see 2.1.";
CM_ SG_ 2566849958 BMS6_ADB_BatSumS_Reserved_01 "Reserved";
CM_ SG_ 2566849958 BMS6_ADB_BatSumS_State_of_Charge "This parameter contains the ratio of the remaining capacity of the battery to the full capacity expressed as a percentage.";
CM_ SG_ 2566849958 BMS6_ADB_BatSumS_State_of_Health "This parameter contains a value relating to the state of health of the battery based on defined thresholds of the ratio of full capacity to design capacity.";
CM_ SG_ 2566849958 BMS6_ADB_BatSumS_Temp_Alarm "This parameter contains the temperature alarm, based on the maximum battery temperature.
0x00: No fault;
0x01: Low Temperature Alarm
0x02: High Temperature Alarm
0x03: Wrong Temperature Alarm";
CM_ SG_ 2566849958 BMS6_ADB_BatSumS_DischargeDis "This parameter indicates when the battery is not able to be discharged.
0x00: Discharge Enable;
0x01: Discharge Disable";
CM_ SG_ 2566849958 BMS6_ADB_BatSumS_ChargingDisable "This parameter indicates when the battery is not able to be discharged.
0x00: Charging Enable;
0x01: Charging Disable";
CM_ SG_ 2566849958 BMS6_ADB_BatSumS_HeaterEnabled "This parameter indicates when the heater is enabled.
0x00: Heater Disabled;
0x01: Heater Enabled";
CM_ SG_ 2566849958 BMS6_ADB_BatSumS_BypassEnabled "This parameter indicates when the bypass is enabled.
0x00: Bypass Disabled;
0x01: Bypass Enabled";
CM_ SG_ 2566849958 BMS6_ADB_BatSumS_Voltage_Alarm "This parameter indicates an over voltage condition in one or more modules.
0x00: No fault;
0x01:Over Voltage Alarm";
CM_ SG_ 2566849958 BMS6_ADB_BatSumS_Reserved_04 "Reserved";
CM_ SG_ 2566849958 BMS6_ADB_BatSumS_Reserved_05 "Reserved";
CM_ SG_ 2566849958 BMS6_ADB_BatSumS_Reserved_06 "Reserved";
CM_ SG_ 2566849958 BMS6_ADB_BatSumS_Reserved_07 "Reserved";
CM_ SG_ 2566849958 BMS6_ADB_BatSumS_Reserved_08 "Reserved";
CM_ SG_ 2566849958 BMS6_ADB_BatSumS_Reserved_09 "Reserved";
CM_ SG_ 2566849958 BMS6_ADB_BatSumS_Reserved_10 "Reserved";
CM_ SG_ 2566849958 BMS6_ADB_BatSumS_Reserved_11 "Reserved";
CM_ BO_ 2566849702 "Used for debugging purposes.";
CM_ SG_ 2566849702 BMS6_ADB_Debug_0 "Used for debugging purpose - byte 0";
CM_ SG_ 2566849702 BMS6_ADB_Debug_1 "Used for debugging purpose - byte 1";
CM_ SG_ 2566849702 BMS6_ADB_Debug_2 "Used for debugging purpose - byte 2";
CM_ SG_ 2566849702 BMS6_ADB_Debug_3 "Used for debugging purpose - byte 3";
CM_ SG_ 2566849702 BMS6_ADB_Debug_4 "Used for debugging purpose - byte 4";
CM_ SG_ 2566849702 BMS6_ADB_Debug_5 "Used for debugging purpose - byte 5";
CM_ SG_ 2566849702 BMS6_ADB_Debug_6 "Used for debugging purpose - byte 6";
CM_ SG_ 2566849702 BMS6_ADB_Debug_7 "Used for debugging purpose - byte 7";
CM_ BO_ 2566853286 "This PGN reports the remaining module capacity, the expected full module capacity and the designed module capacity for module 3.";
CM_ SG_ 2566853286 BMS6_ADB_M1_Remaining_capacity "This parameter contains the remaining capacity of the battery.";
CM_ SG_ 2566853286 BMS6_ADB_M1_Full_capacity "This parameter contains the full capacity of the battery.";
CM_ SG_ 2566853286 BMS6_ADB_M1_Design_capacity "This parameter contains the design capacity of the battery.";
CM_ SG_ 2566853286 BMS6_ADB_M1_Reserved_Cap "Reserved";
CM_ BO_ 2566853030 "This PGN reports the remaining module capacity, the expected full module capacity and the designed module capacity for module 2.";
CM_ SG_ 2566853030 BMS6_ADB_M2_Remaining_capacity "This parameter contains the remaining capacity of the battery.";
CM_ SG_ 2566853030 BMS6_ADB_M2_Full_capacity "This parameter contains the full capacity of the battery.";
CM_ SG_ 2566853030 BMS6_ADB_M2_Design_capacity "This parameter contains the design capacity of the battery.";
CM_ SG_ 2566853030 BMS6_ADB_M2_Reserved_Cap "Reserved";
CM_ BO_ 2566852774 "This PGN reports the remaining module capacity, the expected full module capacity and the designed module capacity for module 1.";
CM_ SG_ 2566852774 BMS6_ADB_M3_Remaining_capacity "This parameter contains the remaining capacity of the battery.";
CM_ SG_ 2566852774 BMS6_ADB_M3_Full_capacity "This parameter contains the full capacity of the battery.";
CM_ SG_ 2566852774 BMS6_ADB_M3_Design_capacity "This parameter contains the design capacity of the battery.";
CM_ SG_ 2566852774 BMS6_ADB_M3_Reserved_Cap "Reserved";
CM_ BO_ 2566861990 "This PGN reports the total number of software-related events that have occurred during the life of the battery.";
CM_ SG_ 2566861990 BMS6_ADB_WatchdogReset_events "This parameter contains a count of the number times the watchdog has reset the firmware due to an internal lock-up.
Data Range: 0 – 64255. A value of 64255 indicates 64255 events or more.";
CM_ SG_ 2566861990 BMS6_ADB_StackOverflowReset_even "This parameter contains a count of the number times the firmware has been reset due to a stack-overflow.
Data Range: 0 – 64255. A value of 64255 indicates 64255 events or more.";
CM_ SG_ 2566861990 BMS6_ADB_CommandedReset_events "This parameter contains a count of the number times the firmware has been reset by a CAN, USB or status button command.
Data Range: 0 – 64255. A value of 64255 indicates 64255 events or more.";
CM_ SG_ 2566861990 BMS6_ADB_IllegalInstructionReset "This parameter contains a count of the number times the firmware has been hard-reset using the status button.
Data Range: 0 – 64255. A value of 64255 indicates 64255 events or more.";
CM_ BO_ 2566861734 "This PGN reports the total number of voltage-related events that have occurred during the life of the battery.";
CM_ SG_ 2566861734 BMS6_ADB_OverVoltage_events "This parameter contains a count of the number of times an over-voltage event has occurred.";
CM_ SG_ 2566861734 BMS6_ADB_UnderVoltage_events "This parameter contains a count of the number of times an under-voltage event has occurred.";
CM_ BO_ 2566861478 "This PGN reports the total number of current and temperature-related events that have occurred during the life of the battery.";
CM_ SG_ 2566861478 BMS6_ADB_ShortCircuit_events "This parameter contains a count of the number of times the battery has been short-circuited.";
CM_ SG_ 2566861478 BMS6_ADB_CurrentOverload_events "This parameter contains a count of the number of times the battery has been overloaded.";
CM_ SG_ 2566861478 BMS6_ADB_OverCurrent_Charge_ev "This parameter contains a count of the number of times the battery’s maximum charge current has been exceeded.";
CM_ SG_ 2566861478 BMS6_ADB_OverTemperature_ev "This parameter contains a count of the number of times the battery’s maximum temperature has been exceeded.";
CM_ BO_ 2566861222 "This PGN reports on the maximum and minimum battery voltages and currents measured during the life of the battery.";
CM_ SG_ 2566861222 BMS6_ADB_MaximumVoltage "This parameter contains the maximum voltage ever measured across the battery cells.";
CM_ SG_ 2566861222 BMS6_ADB_MinimumVoltage "This parameter contains the minimum voltage ever measured across the battery cells.";
CM_ SG_ 2566861222 BMS6_ADB_MAX_Discharge_Current "This parameter contains the maximum discharge current ever measured on the battery.";
CM_ SG_ 2566861222 BMS6_ADB_MAX_Charge_Current "This parameter contains the maximum charge current ever measured on the battery.";
CM_ BO_ 2566860966 "This PGN reports on the maximum and minimum temperatures experienced during the life of the battery.";
CM_ SG_ 2566860966 BMS6_ADB_Maximum_Life_temp "This parameter contains the maximum temperature ever measured in the battery.";
CM_ SG_ 2566860966 BMS6_ADB_Minimum_Life_temp "This parameter contains the minimum temperature ever measured in the battery.";
CM_ SG_ 2566860966 BMS6_ADB_MAX_Charging_Temp "This parameter contains the maximum temperature ever measured while charging the battery.";
CM_ SG_ 2566860966 BMS6_ADB_MIN_Charging_Temp "This parameter contains the minimum temperature ever measured while charging the battery.";
CM_ BO_ 2566857382 "This PGN reports on the individual discharge switch temperatures within module 3 of the battery. The values are only valid when the discharge current exceeds 10A for the entire battery, at other times the values returned will be the J1939 unavailable value.";
CM_ SG_ 2566857382 BMS6_ADB_M3_Temperature_1 "This parameter contains the temperature of a discharge switch sensor.";
CM_ SG_ 2566857382 BMS6_ADB_M3_Temperature_2 "This parameter contains the temperature of a discharge switch sensor.";
CM_ SG_ 2566857382 BMS6_ADB_M3_Temperature_3 "This parameter contains the temperature of a discharge switch sensor.";
CM_ SG_ 2566857382 BMS6_ADB_M3_Reserved_Dis1 "Reserved";
CM_ SG_ 2566857382 BMS6_ADB_M3_Reserved_Dis2 "Reserved";
CM_ BO_ 2566857126 "This PGN reports on the individual discharge switch temperatures within module 2 of the battery. The values are only valid when the discharge current exceeds 10A for the entire battery, at other times the values returned will be the J1939 unavailable value.";
CM_ SG_ 2566857126 BMS6_ADB_M2_Temperature_1 "This parameter contains the temperature of a discharge switch sensor.";
CM_ SG_ 2566857126 BMS6_ADB_M2_Temperature_2 "This parameter contains the temperature of a discharge switch sensor.";
CM_ SG_ 2566857126 BMS6_ADB_M2_Temperature_3 "This parameter contains the temperature of a discharge switch sensor.";
CM_ SG_ 2566857126 BMS6_ADB_M2_Reserved_Dis1 "Reserved";
CM_ SG_ 2566857126 BMS6_ADB_M2_Reserved_Dis2 "Reserved";
CM_ BO_ 2566856870 "This PGN reports on the individual discharge switch temperatures within module 1 of the battery. The values are only valid when the discharge current exceeds 10A for the entire battery, at other times the values returned will be the J1939 unavailable value.";
CM_ SG_ 2566856870 BMS6_ADB_M1_Temperature_1 "This parameter contains the temperature of a discharge switch sensor.";
CM_ SG_ 2566856870 BMS6_ADB_M1_Temperature_2 "This parameter contains the temperature of a discharge switch sensor.";
CM_ SG_ 2566856870 BMS6_ADB_M1_Temperature_3 "This parameter contains the temperature of a discharge switch sensor.";
CM_ SG_ 2566856870 BMS6_ADB_M1_Reserved_Dis1 "Reserved";
CM_ SG_ 2566856870 BMS6_ADB_M1_Reserved_Dis2 "Reserved";
CM_ BO_ 2566855334 "This PGN reports on the individual temperatures measured within module 3 of the battery.";
CM_ SG_ 2566855334 BMS6_ADB_M3_FuelGauge1_Temp "This parameter contains the temperature measured by the module’s fuel gauge IC.";
CM_ SG_ 2566855334 BMS6_ADB_M3_Thermistor1_temp "This parameter contains the temperature measured by one of the module’s Thermistors.";
CM_ SG_ 2566855334 BMS6_ADB_M3_Thermistor2_temp "This parameter contains the temperature measured by one of the module’s Thermistors.";
CM_ SG_ 2566855334 BMS6_ADB_M3_FuelGauge2_Temp "This parameter contains the temperature measured by the module’s fuel gauge IC.";
CM_ BO_ 2566855078 "This PGN reports on the individual temperatures measured within module 2 of the battery.";
CM_ SG_ 2566855078 BMS6_ADB_M2_FuelGauge1_Temp "This parameter contains the temperature measured by the module’s fuel gauge IC.";
CM_ SG_ 2566855078 BMS6_ADB_M2_Thermistor1_temp "This parameter contains the temperature measured by one of the module’s Thermistors.";
CM_ SG_ 2566855078 BMS6_ADB_M2_Thermistor2_temp "This parameter contains the temperature measured by one of the module’s Thermistors.";
CM_ SG_ 2566855078 BMS6_ADB_M2_FuelGauge2_Temp "This parameter contains the temperature measured by the module’s fuel gauge IC.";
CM_ BO_ 2566854822 "This PGN reports on the individual temperatures measured within module 1 of the battery.";
CM_ SG_ 2566854822 BMS6_ADB_M1_FuelGauge1_Temp "This parameter contains the temperature measured by the module’s fuel gauge IC.";
CM_ SG_ 2566854822 BMS6_ADB_M1_Thermistor1_temp "This parameter contains the temperature measured by one of the module’s Thermistors.";
CM_ SG_ 2566854822 BMS6_ADB_M1_Thermistor2_temp "This parameter contains the temperature measured by one of the module’s Thermistors.";
CM_ SG_ 2566854822 BMS6_ADB_M1_FuelGauge2_Temp "This parameter contains the temperature measured by the module’s fuel gauge IC.";
CM_ BO_ 2566851238 "This PGN reports the operating parameters of module 3 within the battery: output voltage, average current (charge or discharge), the percentage state of charge, a state of health indication and the protection status of the module.";
CM_ SG_ 2566851238 BMS6_ADB_M3_Module_OUT_Voltage "This parameter contains the output voltage of the module.";
CM_ SG_ 2566851238 BMS6_ADB_M3_ModuleAverageCurrent "This parameter contains the charge (positive) or discharge (negative) current of the module averaged over 1 second.";
CM_ SG_ 2566851238 BMS6_ADB_M3_Module_StateOfCharge "This parameter contains the ratio of the remaining capacity of the module to the full capacity of the module expressed as a percentage.";
CM_ SG_ 2566851238 BMS6_ADB_M3_Module_StateOfHealth "This parameter contains a value relating to the state of health of the module based on defined thresholds of the ratio of full capacity to design capacity.";
CM_ SG_ 2566851238 BMS6_ADB_M3_DiscProtectTrigg "This parameter contains the current protection status of the module.
Discharge protection triggered";
CM_ SG_ 2566851238 BMS6_ADB_M3_ChargeProtectTrigg "This parameter contains the current protection status of the module.
Charge protection triggered";
CM_ SG_ 2566851238 BMS6_ADB_M3_ModulesMissingFailed "This parameter contains the current protection status of the module.
Modules missing/failed";
CM_ SG_ 2566851238 BMS6_ADB_M3_OverTemp_detect "This parameter contains the current protection status of the module.
Over-temperature detected";
CM_ SG_ 2566851238 BMS6_ADB_M3_UnderVoltage_detect "This parameter contains the current protection status of the module.
Under-voltage detected";
CM_ SG_ 2566851238 BMS6_ADB_M3_OverVoltage_detected "This parameter contains the current protection status of the module.
Over-voltage detected";
CM_ SG_ 2566851238 BMS6_ADB_M3_Overload_detected "This parameter contains the current protection status of the module.
Overload detected";
CM_ SG_ 2566851238 BMS6_ADB_M3_ShortCircuit_detect "This parameter contains the current protection status of the module.
Short circuit detected";
CM_ SG_ 2566851238 BMS6_ADB_M3_Module_BQ78350 "This parameter contains selected data from the BQ78350 status.
Each bit indicates a different alarm (bit 1 indicates extra 1, bit 2 indicates extra 2 …) where 0 indicates no fault and 1 indicates missing, failed or protection triggered";
CM_ BO_ 2566850982 "This PGN reports the operating parameters of module 2 within the battery: output voltage, average current (charge or discharge), the percentage state of charge, a state of health indication and the protection status of the module.";
CM_ SG_ 2566850982 BMS6_ADB_M2_Module_OUT_Voltage "This parameter contains the output voltage of the module.";
CM_ SG_ 2566850982 BMS6_ADB_M2_ModuleAverageCurrent "This parameter contains the charge (positive) or discharge (negative) current of the module averaged over 1 second.";
CM_ SG_ 2566850982 BMS6_ADB_M2_Module_StateOfCharge "This parameter contains the ratio of the remaining capacity of the module to the full capacity of the module expressed as a percentage.";
CM_ SG_ 2566850982 BMS6_ADB_M2_Module_StateOfHealth "This parameter contains a value relating to the state of health of the module based on defined thresholds of the ratio of full capacity to design capacity.";
CM_ SG_ 2566850982 BMS6_ADB_M2_DiscProtectTrigg "This parameter contains the current protection status of the module.
Discharge protection triggered";
CM_ SG_ 2566850982 BMS6_ADB_M2_ChargeProtectTrigg "This parameter contains the current protection status of the module.
Charge protection triggered";
CM_ SG_ 2566850982 BMS6_ADB_M2_ModulesMissingFailed "This parameter contains the current protection status of the module.
Modules missing/failed";
CM_ SG_ 2566850982 BMS6_ADB_M2_OverTemp_detect "This parameter contains the current protection status of the module.
Over-temperature detected";
CM_ SG_ 2566850982 BMS6_ADB_M2_UnderVoltage_detect "This parameter contains the current protection status of the module.
Under-voltage detected";
CM_ SG_ 2566850982 BMS6_ADB_M2_OverVoltage_detected "This parameter contains the current protection status of the module.
Over-voltage detected";
CM_ SG_ 2566850982 BMS6_ADB_M2_Overload_detected "This parameter contains the current protection status of the module.
Overload detected";
CM_ SG_ 2566850982 BMS6_ADB_M2_ShortCircuit_detect "This parameter contains the current protection status of the module.
Short circuit detected";
CM_ SG_ 2566850982 BMS6_ADB_M2_Module_BQ78350 "This parameter contains selected data from the BQ78350 status.
Each bit indicates a different alarm (bit 1 indicates extra 1, bit 2 indicates extra 2 …) where 0 indicates no fault and 1 indicates missing, failed or protection triggered";
CM_ BO_ 2566850726 "This PGN reports the operating parameters of module 1 within the battery: output voltage, average current (charge or discharge), the percentage state of charge, a state of health indication and the protection status of the module.";
CM_ SG_ 2566850726 BMS6_ADB_M1_Module_OUT_Voltage "This parameter contains the output voltage of the module.";
CM_ SG_ 2566850726 BMS6_ADB_M1_ModuleAverageCurrent "This parameter contains the charge (positive) or discharge (negative) current of the module averaged over 1 second.";
CM_ SG_ 2566850726 BMS6_ADB_M1_Module_StateOfCharge "This parameter contains the ratio of the remaining capacity of the module to the full capacity of the module expressed as a percentage.";
CM_ SG_ 2566850726 BMS6_ADB_M1_Module_StateOfHealth "This parameter contains a value relating to the state of health of the module based on defined thresholds of the ratio of full capacity to design capacity.";
CM_ SG_ 2566850726 BMS6_ADB_M1_DiscProtectTrigg "This parameter contains the current protection status of the module.
Discharge protection triggered";
CM_ SG_ 2566850726 BMS6_ADB_M1_ChargeProtectTrigg "This parameter contains the current protection status of the module.
Charge protection triggered";
CM_ SG_ 2566850726 BMS6_ADB_M1_ModulesMissingFailed "This parameter contains the current protection status of the module.
Modules missing/failed";
CM_ SG_ 2566850726 BMS6_ADB_M1_OverTemp_detect "This parameter contains the current protection status of the module.
Over-temperature detected";
CM_ SG_ 2566850726 BMS6_ADB_M1_UnderVoltage_detect "This parameter contains the current protection status of the module.
Under-voltage detected";
CM_ SG_ 2566850726 BMS6_ADB_M1_OverVoltage_detected "This parameter contains the current protection status of the module.
Over-voltage detected";
CM_ SG_ 2566850726 BMS6_ADB_M1_Overload_detected "This parameter contains the current protection status of the module.
Overload detected";
CM_ SG_ 2566850726 BMS6_ADB_M1_ShortCircuit_detect "This parameter contains the current protection status of the module.
Short circuit detected";
CM_ SG_ 2566850726 BMS6_ADB_M1_Module_BQ78350 "This parameter contains selected data from the BQ78350 status.
Each bit indicates a different alarm (bit 1 indicates extra 1, bit 2 indicates extra 2 …) where 0 indicates no fault and 1 indicates missing, failed or protection triggered";
CM_ BO_ 2566849446 "This PGN reports the battery’s serial and firmware version numbers.";
CM_ SG_ 2566849446 BMS6_ADB_Battery_serial_number "This parameter contains the manufactured serial number of the battery. The lowest 21 bits of this 24 bit serial number are also used in the J1939 NAME – see 2.1.";
CM_ SG_ 2566849446 BMS6_ADB_FirmwareVersionMajor "This parameter contains the major number of the firmware version, i.e. where the firmware has a version XX.YY.ZZZ it represents XX.";
CM_ SG_ 2566849446 BMS6_ADB_FirmwareVersionMinor "This parameter contains the major number of the firmware version, i.e. where the firmware has a version XX.YY.ZZZ it represents YY.";
CM_ SG_ 2566849446 BMS6_ADB_Firmware_Revision "This parameter contains the major number of the firmware version, i.e. where the firmware has a version XX.YY.ZZZ it represents ZZZ.";
CM_ BO_ 2566849190 "This PGN reports the battery temperature. The battery contains a number of temperature sensors which are summarised in this PGN by reporting the maximum, the minimum and the average of all the sensors.";
CM_ SG_ 2566849190 BMS6_ADB_Maximum_Temperature "This parameter contains the highest temperature currently measured within the battery.";
CM_ SG_ 2566849190 BMS6_ADB_Minimum_Temperature "This parameter contains the lowest temperature currently measured within the battery.";
CM_ SG_ 2566849190 BMS6_ADB_Average_Temperature "This parameter contains the average of all the temperatures currently measured within the battery.";
CM_ BO_ 2566848934 "This PGN reports the remaining battery capacity, the expected full battery capacity and the designed battery capacity. If the capacity falls below a defined percentage of the design capacity, the battery enters an alarm state and broadcasts this PGN within 100ms of the event and then repeatedly at 1000ms intervals until the capacity moves above the alarm threshold.";
CM_ SG_ 2566848934 BMS6_ADB_Remaining_capacity "This parameter contains the remaining capacity of the battery.";
CM_ SG_ 2566848934 BMS6_ADB_Full_capacity "This parameter contains the full capacity of the battery.";
CM_ SG_ 2566848934 BMS6_ADB_Design_capacity "This parameter contains the design capacity of the battery.";
CM_ SG_ 2566848934 BMS6_ADB_Overall_10_alarm "This parameter contains fields indicating which, if any, capacity alarm thresholds have been triggered.
Overall – less than 10% of design capacity remaining";
CM_ SG_ 2566848934 BMS6_ADB_Silent_Watch_20_alarm "This parameter contains fields indicating which, if any, capacity alarm thresholds have been triggered.
Silent watch – less than 20% silent watch threshold";
CM_ SG_ 2566848934 BMS6_ADB_EngStartCapacity_alarm "This parameter contains fields indicating which, if any, capacity alarm thresholds have been triggered.
Engine start – capacity below engine start threshold";
CM_ SG_ 2566848934 BMS6_ADB_10_Reserved_4 "Not used";
CM_ SG_ 2566848934 BMS6_ADB_10_Reserved_5 "Not used";
CM_ SG_ 2566848934 BMS6_ADB_10_Reserved_6 "Not used";
CM_ SG_ 2566848934 BMS6_ADB_10_Reserved_7 "Not used";
CM_ SG_ 2566848934 BMS6_ADB_10_Reserved_8 "Not used";
CM_ BO_ 2566848678 "This PGN reports the normal operating parameters of the battery: output voltage, average current (charge or discharge), the percentage state of charge and a state of health indication.
The PGN is broadcast at 1000ms intervals or can be requested.";
CM_ SG_ 2566848678 BMS6_ADB_Batt_OUT_Voltage "This parameter contains the output voltage of the battery.
It only specifies the voltage of the internal modules that are available for discharge: any module which is in over-temperature or under-voltage protection is not included in this figure because it has been internally disconnected.";
CM_ SG_ 2566848678 BMS6_ADB_Batt_Average_Current "This parameter contains the charge (positive) or discharge (negative) current of the battery averaged over 1 second.";
CM_ SG_ 2566848678 BMS6_ADB_Batt_StsOfCharge "This parameter contains the ratio of the remaining capacity of the battery to the full capacity expressed as a percentage.";
CM_ SG_ 2566848678 BMS6_ADB_Batt_StsOfHealth "This parameter contains a value relating to the state of health of the battery based on defined thresholds of the ratio of full capacity to design capacity.";
CM_ SG_ 2566848678 BMS6_ADB_Batt_PS8_discharge_prot "This parameter contains the current protection status of the battery.
Discharge protection triggered.";
CM_ SG_ 2566848678 BMS6_ADB_Batt_PS7_charge_prot "This parameter contains the current protection status of the battery.
Charge protection triggered.";
CM_ SG_ 2566848678 BMS6_ADB_Batt_PS6_mod_failed "This parameter contains the current protection status of the battery.
1 or more modules missing/failed.";
CM_ SG_ 2566848678 BMS6_ADB_Batt_PS5_over_temp "This parameter contains the current protection status of the battery.
Over-temperature detected.";
CM_ SG_ 2566848678 BMS6_ADB_Batt_PS4_under_voltage "This parameter contains the current protection status of the battery.
Under-voltage detected.";
CM_ SG_ 2566848678 BMS6_ADB_Batt_PS3_over_voltage "This parameter contains the current protection status of the battery.
Over-voltage detected.";
CM_ SG_ 2566848678 BMS6_ADB_Batt_PS2_overload "This parameter contains the current protection status of the battery.
Overload detected.";
CM_ SG_ 2566848678 BMS6_ADB_Batt_PS1_short_circuit "This parameter contains the current protection status of the battery.
Short circuit detected.";
CM_ SG_ 2566848678 BMS6_ADB_Batt_OS_8_sleep_mode "This parameter contains the status bits indicating the current state of the emergency load-dump, emergency override, heater and charger controls along with the master protection status bit.
Sleep mode pending (1 = sleep pending, 0 = awake)";
CM_ SG_ 2566848678 BMS6_ADB_Batt_OS_7_emerg_used "This parameter contains the status bits indicating the current state of the emergency load-dump, emergency override, heater and charger controls along with the master protection status bit.
Emergency override used (1= used, 0 = never used)";
CM_ SG_ 2566848678 BMS6_ADB_Batt_OS_6_emergency "This parameter contains the status bits indicating the current state of the emergency load-dump, emergency override, heater and charger controls along with the master protection status bit.
Emergency override (1 = active, 0 = inactive)";
CM_ SG_ 2566848678 BMS6_ADB_Batt_OS_45_charge_level "This parameter contains the status bits indicating the current state of the emergency load-dump, emergency override, heater and charger controls along with the master protection status bit.
Charge level (0 = off, 1 = 25%, 2 = 50%, 3 = full)";
CM_ SG_ 2566848678 BMS6_ADB_Batt_OS_3_charge_cont "This parameter contains the status bits indicating the current state of the emergency load-dump, emergency override, heater and charger controls along with the master protection status bit.
Charge control (1 = on, 0 = off)";
CM_ SG_ 2566848678 BMS6_ADB_Batt_OS_2_heater_cont "This parameter contains the status bits indicating the current state of the emergency load-dump, emergency override, heater and charger controls along with the master protection status bit.
Heater control (1 = on, 0 = off)";
CM_ SG_ 2566848678 BMS6_ADB_Batt_OS_1_master_prot "This parameter contains the status bits indicating the current state of the emergency load-dump, emergency override, heater and charger controls along with the master protection status bit.
Master protect (1 = protect, 0 = off)";
CM_ BO_ 2566804134 "This contains high resolution/range parameters reported from the alternator or power generation components.";
CM_ SG_ 2566804134 _nu_BMS6_ADB_AlternatorCurrent "SPN 1795 Alternator Current (High Range/Resolution)
This parameter indicates the amount of electrical current output from the alternator of the main vehicle. Alternator Current
(SPN 115) has a lower range and resolution.";
CM_ SG_ 2566804134 BMS6_ADB_NetBattery_Current "SPN 2579 Net Battery Current (High Range/Resolution)
Net flow of electrical current into/out-of the battery or batteries. This parameter is the high range and resolution of SPN
114 - Net Battery Current.";
CM_ BO_ 2566803622 "Contains battery temperature information.";
CM_ SG_ 2566803622 BMS6_ADB_Battery1_Temperature "Temperature of the battery 1. The relation to physical location is determined by the equipment manufacturer.";
CM_ SG_ 2566803622 _nu_BMS6_ADB_Battery2_Temp "Temperature of the battery 2. The relation to physical location is determined by the equipment manufacturer.";
CM_ BO_ 2566698662 "PGN containing vehicle electrical power information for the battery pack used for starting, lighting, and ignition.";
CM_ SG_ 2566698662 BMS6_ADB_SLI_BattPack_StOfCharge "5981
SLI Battery Pack State of Charge
Indicates the remaining charge of the battery pack used for starting the engine, for lighting, and for ignition (SLI). 0% means no charge remaining, 100% means full capacity at the battery pack's current state of health.   See SPN 5464 for hybrid battery pack.";
CM_ SG_ 2566698662 BMS6_ADB_SLI_BattPack_Capacity "5982
SLI Battery Pack Capacity
Original or rated total reserve capacity of the battery pack used for starting the engine, for lighting, and for ignition (SLI).";
CM_ SG_ 2566698662 BMS6_ADB_SLI_BattPack_Health "5983
SLI Battery Pack Health
Capacity of the battery pack relative to its original specification for the battery pack used for starting the engine, for lighting, and for ignition (SLI). 0% means battery pack is not capable of holding any charge, 100% means battery pack is capable of holding its original full capacity.";
CM_ BO_ 2566862246 "This PGN reports the total number of software-related events that have occurred during the life of the battery.";
CM_ SG_ 2566862246 BMS6_ADB_HardMCLRReset_events "This parameter contains a count of the number times the MCLR has reset the firmware due to a hardware reset pulse, this may be due to the external watchdog.
Data Range: 0 – 64255. A value of 64255 indicates 64255 events or more.";
CM_ SG_ 2566862246 BMS6_ADB_LowVoltageReset_events "TThis parameter contains a count of the number times the firmware has been reset due to the processor detecting a low supply voltage.
Data Range: 0 – 64255. A value of 64255 indicates 64255 events or more.";
CM_ SG_ 2566862246 BMS6_ADB_PORReset_events "This parameter contains a count of the number times the firmware has been started from a power up condition.
Data Range: 0 – 64255. A value of 64255 indicates 64255 events or more.";
CM_ SG_ 2566862246 BMS6_ADB_BrownOutReset_events "This parameter contains a count of the number times the firmware has been restarted due to a brown-out (below 2.7V).
Data Range: 0 – 64255. A value of 64255 indicates 64255 events or more.";
CM_ BO_ 2565799846 "Generic message for send the NAME
Used only for the BMS6";
CM_ SG_ 2565799846 BMS6_ADB_VehicleSystemInstance "Vehicle System Instance";
CM_ SG_ 2565799846 BMS6_ADB_IndustryGroup "Industry Group";
CM_ SG_ 2565799846 BMS6_ADB_Name_Reserved "Reserved";
CM_ SG_ 2565799846 BMS6_ADB_ECUInstance "ECU Instance";
CM_ SG_ 2565799846 BMS6_ADB_IdentityNumber_3 "Most significant 5 bits of Identity Number";
CM_ SG_ 2565799846 BMS6_ADB_ArbitraryAddressCapable "Arbitrary Address Capable";
CM_ SG_ 2565799846 BMS6_ADB_VehicleSystem "Vehicle System";
CM_ SG_ 2565799846 BMS6_ADB_Function "Function";
CM_ SG_ 2565799846 BMS6_ADB_FunctionInstance "Function Instance";
CM_ SG_ 2565799846 BMS6_ADB_ManufacturerCode_2 "Most significant 8 bits of Manufacturer Code";
CM_ SG_ 2565799846 BMS6_ADB_ManufacturerCode_1 "Least significant 3 bits of Manufacturer Code";
CM_ SG_ 2565799846 BMS6_ADB_IdentityNumber_2 "Second byte of Identity Number";
CM_ SG_ 2565799846 BMS6_ADB_IdentityNumber_1 "Least significant byte of Identity Number";
BA_DEF_ BO_  "GenMsgCycleTimeFast" INT 0 3600000;
BA_DEF_ BO_  "GenMsgDelayTime" INT 0 3600000;
BA_DEF_ BO_  "GenMsgStartDelayTime" INT 0 10000;
BA_DEF_ BO_  "GenMsgSendType" ENUM  "cyclic","reserved","cyclicIfActive","reserved","reserved","reserved","reserved","reserved","noMsgSendType";
BA_DEF_ BO_  "GenMsgCycleTime" INT 0 3600000;
BA_DEF_ BO_  "GenMsgILSupport" ENUM  "No","Yes";
BA_DEF_ BO_  "VFrameFormat" ENUM  "StandardCAN","ExtendedCAN","reserved","J1939PG";
BA_DEF_ BO_  "GenMsgSendTypex" ENUM  "cyclic","reserved","cyclicIfActive","reserved","reserved","reserved","reserved","reserved","noMsgSendType";
BA_DEF_ BO_  "GenMsgRequestable" INT 0 1;
BA_DEF_ BO_  "GenMsgSencmype" ENUM  "cyclic","reserved","cyclicIfActive","reserved","reserved","reserved","reserved","reserved","noMsgSencmype";
BA_DEF_ BO_  "GenMsgSencmypex" ENUM  "cyclic","reserved","cyclicIfActive","reserved","reserved","reserved","reserved","reserved","noMsgSencmype";
BA_DEF_ SG_  "GenSigSendType" ENUM  "Cyclic","OnWrite","reserved","OnChange","reserved","reserved","reserved","NoSigSendType";
BA_DEF_ SG_  "GenSigStartValue" INT 0 10000;
BA_DEF_ SG_  "GenSigEVName" STRING ;
BA_DEF_ SG_  "GenSigILSupport" ENUM  "Yes","No";
BA_DEF_ SG_  "GenSigSendTypex" ENUM  "Cyclic","OnWrite","reserved","OnChange","reserved","reserved","reserved","NoSigSendType";
BA_DEF_ SG_  "GenSigSencmype" ENUM  "Cyclic","OnWrite","reserved","OnChange","reserved","reserved","reserved","NoSigSencmype";
BA_DEF_ SG_  "GenSigSencmypex" ENUM  "Cyclic","OnWrite","reserved","OnChange","reserved","reserved","reserved","NoSigSencmype";
BA_DEF_ SG_  "SigType" ENUM  "Default","Range","RangeSigned","ASCII","Discrete","Control","ReferencePGN","DTC","StringDelimiter","StringLength","StringLengthControl";
BA_DEF_DEF_  "GenMsgCycleTimeFast" 0;
BA_DEF_DEF_  "GenMsgDelayTime" 0;
BA_DEF_DEF_  "GenMsgStartDelayTime" 0;
BA_DEF_DEF_  "GenMsgSendType" "noMsgSendType";
BA_DEF_DEF_  "GenMsgCycleTime" 0;
BA_DEF_DEF_  "GenMsgILSupport" "Yes";
BA_DEF_DEF_  "VFrameFormat" "J1939PG";
BA_DEF_DEF_  "GenMsgSendTypex" "noMsgSendType";
BA_DEF_DEF_  "GenMsgRequestable" 1;
BA_DEF_DEF_  "GenMsgSencmype" "noMsgSencmype";
BA_DEF_DEF_  "GenMsgSencmypex" "noMsgSencmype";
BA_DEF_DEF_  "GenSigSendType" "NoSigSendType";
BA_DEF_DEF_  "GenSigStartValue" 0;
BA_DEF_DEF_  "GenSigEVName" "Env@Nodename_@Signame";
BA_DEF_DEF_  "GenSigILSupport" "Yes";
BA_DEF_DEF_  "GenSigSendTypex" "NoSigSendType";
BA_DEF_DEF_  "GenSigSencmype" "NoSigSencmype";
BA_DEF_DEF_  "GenSigSencmypex" "NoSigSencmype";
BA_DEF_DEF_  "SigType" "Default";
BA_ "GenSigStartValue" SG_ 2566853284 BMS4_ADB_M1_Reserved_Cap 255;
BA_ "GenSigStartValue" SG_ 2566853028 BMS4_ADB_M2_Reserved_Cap 255;
BA_ "GenSigStartValue" SG_ 2566852772 BMS4_ADB_M3_Reserved_Cap 255;
BA_ "GenSigStartValue" SG_ 2566860964 BMS4_ADB_Maximum_Life_temp 1000;
BA_ "GenSigStartValue" SG_ 2566860964 BMS4_ADB_Minimum_Life_temp 1000;
BA_ "GenSigStartValue" SG_ 2566860964 BMS4_ADB_MAX_Charging_Temp 1000;
BA_ "GenSigStartValue" SG_ 2566860964 BMS4_ADB_MIN_Charging_Temp 1000;
BA_ "GenSigStartValue" SG_ 2566857380 BMS4_ADB_M3_Temperature_1 60;
BA_ "GenSigStartValue" SG_ 2566857380 BMS4_ADB_M3_Temperature_2 60;
BA_ "GenSigStartValue" SG_ 2566857380 BMS4_ADB_M3_Temperature_3 60;
BA_ "GenSigStartValue" SG_ 2566857380 BMS4_ADB_M3_Reserved_Dis1 255;
BA_ "GenSigStartValue" SG_ 2566857380 BMS4_ADB_M3_Reserved_Dis2 255;
BA_ "GenSigStartValue" SG_ 2566857124 BMS4_ADB_M2_Temperature_1 60;
BA_ "GenSigStartValue" SG_ 2566857124 BMS4_ADB_M2_Temperature_2 60;
BA_ "GenSigStartValue" SG_ 2566857124 BMS4_ADB_M2_Temperature_3 60;
BA_ "GenSigStartValue" SG_ 2566857124 BMS4_ADB_M2_Reserved_Dis1 255;
BA_ "GenSigStartValue" SG_ 2566857124 BMS4_ADB_M2_Reserved_Dis2 255;
BA_ "GenSigStartValue" SG_ 2566856868 BMS4_ADB_M1_Temperature_1 60;
BA_ "GenSigStartValue" SG_ 2566856868 BMS4_ADB_M1_Temperature_2 60;
BA_ "GenSigStartValue" SG_ 2566856868 BMS4_ADB_M1_Temperature_3 60;
BA_ "GenSigStartValue" SG_ 2566856868 BMS4_ADB_M1_Reserved_Dis1 255;
BA_ "GenSigStartValue" SG_ 2566856868 BMS4_ADB_M1_Reserved_Dis2 255;
BA_ "GenSigStartValue" SG_ 2566855332 BMS4_ADB_M3_FuelGauge1_Temp 1000;
BA_ "GenSigStartValue" SG_ 2566855332 BMS4_ADB_M3_Thermistor1_temp 1000;
BA_ "GenSigStartValue" SG_ 2566855332 BMS4_ADB_M3_Thermistor2_temp 1000;
BA_ "GenSigStartValue" SG_ 2566855332 BMS4_ADB_M3_FuelGauge2_Temp 1000;
BA_ "GenSigStartValue" SG_ 2566855076 BMS4_ADB_M2_FuelGauge1_Temp 1000;
BA_ "GenSigStartValue" SG_ 2566855076 BMS4_ADB_M2_Thermistor1_temp 1000;
BA_ "GenSigStartValue" SG_ 2566855076 BMS4_ADB_M2_Thermistor2_temp 1000;
BA_ "GenSigStartValue" SG_ 2566855076 BMS4_ADB_M2_FuelGauge2_Temp 1000;
BA_ "GenSigStartValue" SG_ 2566854820 BMS4_ADB_M1_FuelGauge1_Temp 1000;
BA_ "GenSigStartValue" SG_ 2566854820 BMS4_ADB_M1_Thermistor1_temp 1000;
BA_ "GenSigStartValue" SG_ 2566854820 BMS4_ADB_M1_Thermistor2_temp 1000;
BA_ "GenSigStartValue" SG_ 2566854820 BMS4_ADB_M1_FuelGauge2_Temp 1000;
BA_ "GenSigStartValue" SG_ 2566849188 BMS4_ADB_Maximum_Temperature 1000;
BA_ "GenSigStartValue" SG_ 2566849188 BMS4_ADB_Minimum_Temperature 1000;
BA_ "GenSigStartValue" SG_ 2566849188 BMS4_ADB_Average_Temperature 1000;
BA_ "GenSigStartValue" SG_ 2566848676 BMS4_ADB_Batt_Average_Current 55;
BA_ "GenSigStartValue" SG_ 2566803620 BMS4_ADB_Battery1_Temperature 40;
BA_ "GenSigStartValue" SG_ 2566803620 _nu_BMS4_ADB_Battery2_Temp 40;
BA_ "GenSigStartValue" SG_ 2566853285 BMS5_ADB_M1_Reserved_Cap 255;
BA_ "GenSigStartValue" SG_ 2566853029 BMS5_ADB_M2_Reserved_Cap 255;
BA_ "GenSigStartValue" SG_ 2566852773 BMS5_ADB_M3_Reserved_Cap 255;
BA_ "GenSigStartValue" SG_ 2566860965 BMS5_ADB_Maximum_Life_temp 1000;
BA_ "GenSigStartValue" SG_ 2566860965 BMS5_ADB_Minimum_Life_temp 1000;
BA_ "GenSigStartValue" SG_ 2566860965 BMS5_ADB_MAX_Charging_Temp 1000;
BA_ "GenSigStartValue" SG_ 2566860965 BMS5_ADB_MIN_Charging_Temp 1000;
BA_ "GenSigStartValue" SG_ 2566857381 BMS5_ADB_M3_Temperature_1 60;
BA_ "GenSigStartValue" SG_ 2566857381 BMS5_ADB_M3_Temperature_2 60;
BA_ "GenSigStartValue" SG_ 2566857381 BMS5_ADB_M3_Temperature_3 60;
BA_ "GenSigStartValue" SG_ 2566857381 BMS5_ADB_M3_Reserved_Dis1 255;
BA_ "GenSigStartValue" SG_ 2566857381 BMS5_ADB_M3_Reserved_Dis2 255;
BA_ "GenSigStartValue" SG_ 2566857125 BMS5_ADB_M2_Temperature_1 60;
BA_ "GenSigStartValue" SG_ 2566857125 BMS5_ADB_M2_Temperature_2 60;
BA_ "GenSigStartValue" SG_ 2566857125 BMS5_ADB_M2_Temperature_3 60;
BA_ "GenSigStartValue" SG_ 2566857125 BMS5_ADB_M2_Reserved_Dis1 255;
BA_ "GenSigStartValue" SG_ 2566857125 BMS5_ADB_M2_Reserved_Dis2 255;
BA_ "GenSigStartValue" SG_ 2566856869 BMS5_ADB_M1_Temperature_1 60;
BA_ "GenSigStartValue" SG_ 2566856869 BMS5_ADB_M1_Temperature_2 60;
BA_ "GenSigStartValue" SG_ 2566856869 BMS5_ADB_M1_Temperature_3 60;
BA_ "GenSigStartValue" SG_ 2566856869 BMS5_ADB_M1_Reserved_Dis1 255;
BA_ "GenSigStartValue" SG_ 2566856869 BMS5_ADB_M1_Reserved_Dis2 255;
BA_ "GenSigStartValue" SG_ 2566855333 BMS5_ADB_M3_FuelGauge1_Temp 1000;
BA_ "GenSigStartValue" SG_ 2566855333 BMS5_ADB_M3_Thermistor1_temp 1000;
BA_ "GenSigStartValue" SG_ 2566855333 BMS5_ADB_M3_Thermistor2_temp 1000;
BA_ "GenSigStartValue" SG_ 2566855333 BMS5_ADB_M3_FuelGauge2_Temp 1000;
BA_ "GenSigStartValue" SG_ 2566855077 BMS5_ADB_M2_FuelGauge1_Temp 1000;
BA_ "GenSigStartValue" SG_ 2566855077 BMS5_ADB_M2_Thermistor1_temp 1000;
BA_ "GenSigStartValue" SG_ 2566855077 BMS5_ADB_M2_Thermistor2_temp 1000;
BA_ "GenSigStartValue" SG_ 2566855077 BMS5_ADB_M2_FuelGauge2_Temp 1000;
BA_ "GenSigStartValue" SG_ 2566854821 BMS5_ADB_M1_FuelGauge1_Temp 1000;
BA_ "GenSigStartValue" SG_ 2566854821 BMS5_ADB_M1_Thermistor1_temp 1000;
BA_ "GenSigStartValue" SG_ 2566854821 BMS5_ADB_M1_Thermistor2_temp 1000;
BA_ "GenSigStartValue" SG_ 2566854821 BMS5_ADB_M1_FuelGauge2_Temp 1000;
BA_ "GenSigStartValue" SG_ 2566849189 BMS5_ADB_Maximum_Temperature 1000;
BA_ "GenSigStartValue" SG_ 2566849189 BMS5_ADB_Minimum_Temperature 1000;
BA_ "GenSigStartValue" SG_ 2566849189 BMS5_ADB_Average_Temperature 1000;
BA_ "GenSigStartValue" SG_ 2566848677 BMS5_ADB_Batt_Average_Current 55;
BA_ "GenSigStartValue" SG_ 2566803621 BMS5_ADB_Battery1_Temperature 40;
BA_ "GenSigStartValue" SG_ 2566803621 _nu_BMS5_ADB_Battery2_Temp 40;
BA_ "GenSigStartValue" SG_ 2566853286 BMS6_ADB_M1_Reserved_Cap 255;
BA_ "GenSigStartValue" SG_ 2566853030 BMS6_ADB_M2_Reserved_Cap 255;
BA_ "GenSigStartValue" SG_ 2566852774 BMS6_ADB_M3_Reserved_Cap 255;
BA_ "GenSigStartValue" SG_ 2566860966 BMS6_ADB_Maximum_Life_temp 1000;
BA_ "GenSigStartValue" SG_ 2566860966 BMS6_ADB_Minimum_Life_temp 1000;
BA_ "GenSigStartValue" SG_ 2566860966 BMS6_ADB_MAX_Charging_Temp 1000;
BA_ "GenSigStartValue" SG_ 2566860966 BMS6_ADB_MIN_Charging_Temp 1000;
BA_ "GenSigStartValue" SG_ 2566857382 BMS6_ADB_M3_Temperature_1 60;
BA_ "GenSigStartValue" SG_ 2566857382 BMS6_ADB_M3_Temperature_2 60;
BA_ "GenSigStartValue" SG_ 2566857382 BMS6_ADB_M3_Temperature_3 60;
BA_ "GenSigStartValue" SG_ 2566857382 BMS6_ADB_M3_Reserved_Dis1 255;
BA_ "GenSigStartValue" SG_ 2566857382 BMS6_ADB_M3_Reserved_Dis2 255;
BA_ "GenSigStartValue" SG_ 2566857126 BMS6_ADB_M2_Temperature_1 60;
BA_ "GenSigStartValue" SG_ 2566857126 BMS6_ADB_M2_Temperature_2 60;
BA_ "GenSigStartValue" SG_ 2566857126 BMS6_ADB_M2_Temperature_3 60;
BA_ "GenSigStartValue" SG_ 2566857126 BMS6_ADB_M2_Reserved_Dis1 255;
BA_ "GenSigStartValue" SG_ 2566857126 BMS6_ADB_M2_Reserved_Dis2 255;
BA_ "GenSigStartValue" SG_ 2566856870 BMS6_ADB_M1_Temperature_1 60;
BA_ "GenSigStartValue" SG_ 2566856870 BMS6_ADB_M1_Temperature_2 60;
BA_ "GenSigStartValue" SG_ 2566856870 BMS6_ADB_M1_Temperature_3 60;
BA_ "GenSigStartValue" SG_ 2566856870 BMS6_ADB_M1_Reserved_Dis1 255;
BA_ "GenSigStartValue" SG_ 2566856870 BMS6_ADB_M1_Reserved_Dis2 255;
BA_ "GenSigStartValue" SG_ 2566855334 BMS6_ADB_M3_FuelGauge1_Temp 1000;
BA_ "GenSigStartValue" SG_ 2566855334 BMS6_ADB_M3_Thermistor1_temp 1000;
BA_ "GenSigStartValue" SG_ 2566855334 BMS6_ADB_M3_Thermistor2_temp 1000;
BA_ "GenSigStartValue" SG_ 2566855334 BMS6_ADB_M3_FuelGauge2_Temp 1000;
BA_ "GenSigStartValue" SG_ 2566855078 BMS6_ADB_M2_FuelGauge1_Temp 1000;
BA_ "GenSigStartValue" SG_ 2566855078 BMS6_ADB_M2_Thermistor1_temp 1000;
BA_ "GenSigStartValue" SG_ 2566855078 BMS6_ADB_M2_Thermistor2_temp 1000;
BA_ "GenSigStartValue" SG_ 2566855078 BMS6_ADB_M2_FuelGauge2_Temp 1000;
BA_ "GenSigStartValue" SG_ 2566854822 BMS6_ADB_M1_FuelGauge1_Temp 1000;
BA_ "GenSigStartValue" SG_ 2566854822 BMS6_ADB_M1_Thermistor1_temp 1000;
BA_ "GenSigStartValue" SG_ 2566854822 BMS6_ADB_M1_Thermistor2_temp 1000;
BA_ "GenSigStartValue" SG_ 2566854822 BMS6_ADB_M1_FuelGauge2_Temp 1000;
BA_ "GenSigStartValue" SG_ 2566849190 BMS6_ADB_Maximum_Temperature 1000;
BA_ "GenSigStartValue" SG_ 2566849190 BMS6_ADB_Minimum_Temperature 1000;
BA_ "GenSigStartValue" SG_ 2566849190 BMS6_ADB_Average_Temperature 1000;
BA_ "GenSigStartValue" SG_ 2566848678 BMS6_ADB_Batt_Average_Current 55;
BA_ "GenSigStartValue" SG_ 2566803622 BMS6_ADB_Battery1_Temperature 40;
BA_ "GenSigStartValue" SG_ 2566803622 _nu_BMS6_ADB_Battery2_Temp 40;
VAL_ 2566849956 BMS4_ADB_BatSumS_State_of_Health 3 "Health_is_wrong" 2 "Health_is_good" 1 "Health_is_medium" 0 "Health_is_poor" ;
VAL_ 2566849956 BMS4_ADB_BatSumS_Temp_Alarm 3 "Wrong_Temperature_Alarm" 2 "High_Temperature_Alarm" 1 "Low_Temperature_Alarm" 0 "No_fault" ;
VAL_ 2566849956 BMS4_ADB_BatSumS_DischargeDis 1 "Discharge_Disable" 0 "Discharge_Enable" ;
VAL_ 2566849956 BMS4_ADB_BatSumS_ChargingDisable 1 "Charging_Disable" 0 "Charging_Enable" ;
VAL_ 2566849956 BMS4_ADB_BatSumS_HeaterEnabled 1 "Heater_Enabled" 0 "Heater_Disabled" ;
VAL_ 2566849956 BMS4_ADB_BatSumS_BypassEnabled 1 "Bypass_Enabled" 0 "Bypass_Disabled" ;
VAL_ 2566849956 BMS4_ADB_BatSumS_Voltage_Alarm 1 "Active" 0 "NotActive" ;
VAL_ 2566851236 BMS4_ADB_M3_Module_StateOfHealth 3 "Health_is_wrong" 2 "Health_is_good" 1 "Health_is_medium" 0 "Health_is_poor" ;
VAL_ 2566851236 BMS4_ADB_M3_DiscProtectTrigg 1 "Fault_Present" 0 "No_Fault" ;
VAL_ 2566851236 BMS4_ADB_M3_ChargeProtectTrigg 1 "Fault_Present" 0 "No_Fault" ;
VAL_ 2566851236 BMS4_ADB_M3_ModulesMissingFailed 1 "Fault_Present" 0 "No_Fault" ;
VAL_ 2566851236 BMS4_ADB_M3_OverTemp_detect 1 "Fault_Present" 0 "No_Fault" ;
VAL_ 2566851236 BMS4_ADB_M3_UnderVoltage_detect 1 "Fault_Present" 0 "No_Fault" ;
VAL_ 2566851236 BMS4_ADB_M3_OverVoltage_detected 1 "Fault_Present" 0 "No_Fault" ;
VAL_ 2566851236 BMS4_ADB_M3_Overload_detected 1 "Fault_Present" 0 "No_Fault" ;
VAL_ 2566851236 BMS4_ADB_M3_ShortCircuit_detect 1 "Fault_Present" 0 "No_Fault" ;
VAL_ 2566850980 BMS4_ADB_M2_Module_StateOfHealth 3 "Health_is_wrong" 2 "Health_is_good" 1 "Health_is_medium" 0 "Health_is_poor" ;
VAL_ 2566850980 BMS4_ADB_M2_DiscProtectTrigg 1 "Fault_Present" 0 "No_Fault" ;
VAL_ 2566850980 BMS4_ADB_M2_ChargeProtectTrigg 1 "Fault_Present" 0 "No_Fault" ;
VAL_ 2566850980 BMS4_ADB_M2_ModulesMissingFailed 1 "Fault_Present" 0 "No_Fault" ;
VAL_ 2566850980 BMS4_ADB_M2_OverTemp_detect 1 "Fault_Present" 0 "No_Fault" ;
VAL_ 2566850980 BMS4_ADB_M2_UnderVoltage_detect 1 "Fault_Present" 0 "No_Fault" ;
VAL_ 2566850980 BMS4_ADB_M2_OverVoltage_detected 1 "Fault_Present" 0 "No_Fault" ;
VAL_ 2566850980 BMS4_ADB_M2_Overload_detected 1 "Fault_Present" 0 "No_Fault" ;
VAL_ 2566850980 BMS4_ADB_M2_ShortCircuit_detect 1 "Fault_Present" 0 "No_Fault" ;
VAL_ 2566850724 BMS4_ADB_M1_Module_StateOfHealth 3 "Health_is_wrong" 2 "Health_is_good" 1 "Health_is_medium" 0 "Health_is_poor" ;
VAL_ 2566850724 BMS4_ADB_M1_DiscProtectTrigg 1 "Fault_Present" 0 "No_Fault" ;
VAL_ 2566850724 BMS4_ADB_M1_ChargeProtectTrigg 1 "Fault_Present" 0 "No_Fault" ;
VAL_ 2566850724 BMS4_ADB_M1_ModulesMissingFailed 1 "Fault_Present" 0 "No_Fault" ;
VAL_ 2566850724 BMS4_ADB_M1_OverTemp_detect 1 "Fault_Present" 0 "No_Fault" ;
VAL_ 2566850724 BMS4_ADB_M1_UnderVoltage_detect 1 "Fault_Present" 0 "No_Fault" ;
VAL_ 2566850724 BMS4_ADB_M1_OverVoltage_detected 1 "Fault_Present" 0 "No_Fault" ;
VAL_ 2566850724 BMS4_ADB_M1_Overload_detected 1 "Fault_Present" 0 "No_Fault" ;
VAL_ 2566850724 BMS4_ADB_M1_ShortCircuit_detect 1 "Fault_Present" 0 "No_Fault" ;
VAL_ 2566848932 BMS4_ADB_Overall_10_alarm 1 "Alarm_ON" 0 "Alarm_OFF" ;
VAL_ 2566848932 BMS4_ADB_Silent_Watch_20_alarm 1 "Alarm_ON" 0 "Alarm_OFF" ;
VAL_ 2566848932 BMS4_ADB_EngStartCapacity_alarm 1 "Alarm_ON" 0 "Alarm_OFF" ;
VAL_ 2566848676 BMS4_ADB_Batt_StsOfHealth 3 "Health_is_wrong" 2 "Health_is_good" 1 "Health_is_medium" 0 "Health_is_poor" ;
VAL_ 2566848676 BMS4_ADB_Batt_PS8_discharge_prot 1 "Fault_Present" 0 "No_Fault" ;
VAL_ 2566848676 BMS4_ADB_Batt_PS7_charge_prot 1 "Fault_Present" 0 "No_Fault" ;
VAL_ 2566848676 BMS4_ADB_Batt_PS6_mod_failed 1 "Fault_Present" 0 "No_Fault" ;
VAL_ 2566848676 BMS4_ADB_Batt_PS5_over_temp 1 "Fault_Present" 0 "No_Fault" ;
VAL_ 2566848676 BMS4_ADB_Batt_PS4_under_voltage 1 "Fault_Present" 0 "No_Fault" ;
VAL_ 2566848676 BMS4_ADB_Batt_PS3_over_voltage 1 "Fault_Present" 0 "No_Fault" ;
VAL_ 2566848676 BMS4_ADB_Batt_PS2_overload 1 "Fault_Present" 0 "No_Fault" ;
VAL_ 2566848676 BMS4_ADB_Batt_PS1_short_circuit 1 "Fault_Present" 0 "No_Fault" ;
VAL_ 2566848676 BMS4_ADB_Batt_OS_8_sleep_mode 1 "Sleep_pending" 0 "Awake" ;
VAL_ 2566848676 BMS4_ADB_Batt_OS_7_emerg_used 1 "used" 0 "never_used" ;
VAL_ 2566848676 BMS4_ADB_Batt_OS_6_emergency 1 "Active" 0 "NotActive" ;
VAL_ 2566848676 BMS4_ADB_Batt_OS_45_charge_level 3 "100%" 2 "50%" 1 "25%" 0 "OFF" ;
VAL_ 2566848676 BMS4_ADB_Batt_OS_3_charge_cont 1 "ON" 0 "OFF" ;
VAL_ 2566848676 BMS4_ADB_Batt_OS_2_heater_cont 1 "ON" 0 "OFF" ;
VAL_ 2566848676 BMS4_ADB_Batt_OS_1_master_prot 1 "Protect" 0 "OFF" ;
VAL_ 2566849957 BMS5_ADB_BatSumS_State_of_Health 3 "Health_is_wrong" 2 "Health_is_good" 1 "Health_is_medium" 0 "Health_is_poor" ;
VAL_ 2566849957 BMS5_ADB_BatSumS_Temp_Alarm 3 "Wrong_Temperature_Alarm" 2 "High_Temperature_Alarm" 1 "Low_Temperature_Alarm" 0 "No_fault" ;
VAL_ 2566849957 BMS5_ADB_BatSumS_DischargeDis 1 "Discharge_Disable" 0 "Discharge_Enable" ;
VAL_ 2566849957 BMS5_ADB_BatSumS_ChargingDisable 1 "Charging_Disable" 0 "Charging_Enable" ;
VAL_ 2566849957 BMS5_ADB_BatSumS_HeaterEnabled 1 "Heater_Enabled" 0 "Heater_Disabled" ;
VAL_ 2566849957 BMS5_ADB_BatSumS_BypassEnabled 1 "Bypass_Enabled" 0 "Bypass_Disabled" ;
VAL_ 2566849957 BMS5_ADB_BatSumS_Voltage_Alarm 1 "Active" 0 "NotActive" ;
VAL_ 2566851237 BMS5_ADB_M3_Module_StateOfHealth 3 "Health_is_wrong" 2 "Health_is_good" 1 "Health_is_medium" 0 "Health_is_poor" ;
VAL_ 2566851237 BMS5_ADB_M3_DiscProtectTrigg 1 "Fault_Present" 0 "No_Fault" ;
VAL_ 2566851237 BMS5_ADB_M3_ChargeProtectTrigg 1 "Fault_Present" 0 "No_Fault" ;
VAL_ 2566851237 BMS5_ADB_M3_ModulesMissingFailed 1 "Fault_Present" 0 "No_Fault" ;
VAL_ 2566851237 BMS5_ADB_M3_OverTemp_detect 1 "Fault_Present" 0 "No_Fault" ;
VAL_ 2566851237 BMS5_ADB_M3_UnderVoltage_detect 1 "Fault_Present" 0 "No_Fault" ;
VAL_ 2566851237 BMS5_ADB_M3_OverVoltage_detected 1 "Fault_Present" 0 "No_Fault" ;
VAL_ 2566851237 BMS5_ADB_M3_Overload_detected 1 "Fault_Present" 0 "No_Fault" ;
VAL_ 2566851237 BMS5_ADB_M3_ShortCircuit_detect 1 "Fault_Present" 0 "No_Fault" ;
VAL_ 2566850981 BMS5_ADB_M2_Module_StateOfHealth 3 "Health_is_wrong" 2 "Health_is_good" 1 "Health_is_medium" 0 "Health_is_poor" ;
VAL_ 2566850981 BMS5_ADB_M2_DiscProtectTrigg 1 "Fault_Present" 0 "No_Fault" ;
VAL_ 2566850981 BMS5_ADB_M2_ChargeProtectTrigg 1 "Fault_Present" 0 "No_Fault" ;
VAL_ 2566850981 BMS5_ADB_M2_ModulesMissingFailed 1 "Fault_Present" 0 "No_Fault" ;
VAL_ 2566850981 BMS5_ADB_M2_OverTemp_detect 1 "Fault_Present" 0 "No_Fault" ;
VAL_ 2566850981 BMS5_ADB_M2_UnderVoltage_detect 1 "Fault_Present" 0 "No_Fault" ;
VAL_ 2566850981 BMS5_ADB_M2_OverVoltage_detected 1 "Fault_Present" 0 "No_Fault" ;
VAL_ 2566850981 BMS5_ADB_M2_Overload_detected 1 "Fault_Present" 0 "No_Fault" ;
VAL_ 2566850981 BMS5_ADB_M2_ShortCircuit_detect 1 "Fault_Present" 0 "No_Fault" ;
VAL_ 2566850725 BMS5_ADB_M1_Module_StateOfHealth 3 "Health_is_wrong" 2 "Health_is_good" 1 "Health_is_medium" 0 "Health_is_poor" ;
VAL_ 2566850725 BMS5_ADB_M1_DiscProtectTrigg 1 "Fault_Present" 0 "No_Fault" ;
VAL_ 2566850725 BMS5_ADB_M1_ChargeProtectTrigg 1 "Fault_Present" 0 "No_Fault" ;
VAL_ 2566850725 BMS5_ADB_M1_ModulesMissingFailed 1 "Fault_Present" 0 "No_Fault" ;
VAL_ 2566850725 BMS5_ADB_M1_OverTemp_detect 1 "Fault_Present" 0 "No_Fault" ;
VAL_ 2566850725 BMS5_ADB_M1_UnderVoltage_detect 1 "Fault_Present" 0 "No_Fault" ;
VAL_ 2566850725 BMS5_ADB_M1_OverVoltage_detected 1 "Fault_Present" 0 "No_Fault" ;
VAL_ 2566850725 BMS5_ADB_M1_Overload_detected 1 "Fault_Present" 0 "No_Fault" ;
VAL_ 2566850725 BMS5_ADB_M1_ShortCircuit_detect 1 "Fault_Present" 0 "No_Fault" ;
VAL_ 2566848933 BMS5_ADB_Overall_10_alarm 1 "Alarm_ON" 0 "Alarm_OFF" ;
VAL_ 2566848933 BMS5_ADB_Silent_Watch_20_alarm 1 "Alarm_ON" 0 "Alarm_OFF" ;
VAL_ 2566848933 BMS5_ADB_EngStartCapacity_alarm 1 "Alarm_ON" 0 "Alarm_OFF" ;
VAL_ 2566848677 BMS5_ADB_Batt_StsOfHealth 3 "Health_is_wrong" 2 "Health_is_good" 1 "Health_is_medium" 0 "Health_is_poor" ;
VAL_ 2566848677 BMS5_ADB_Batt_PS8_discharge_prot 1 "Fault_Present" 0 "No_Fault" ;
VAL_ 2566848677 BMS5_ADB_Batt_PS7_charge_prot 1 "Fault_Present" 0 "No_Fault" ;
VAL_ 2566848677 BMS5_ADB_Batt_PS6_mod_failed 1 "Fault_Present" 0 "No_Fault" ;
VAL_ 2566848677 BMS5_ADB_Batt_PS5_over_temp 1 "Fault_Present" 0 "No_Fault" ;
VAL_ 2566848677 BMS5_ADB_Batt_PS4_under_voltage 1 "Fault_Present" 0 "No_Fault" ;
VAL_ 2566848677 BMS5_ADB_Batt_PS3_over_voltage 1 "Fault_Present" 0 "No_Fault" ;
VAL_ 2566848677 BMS5_ADB_Batt_PS2_overload 1 "Fault_Present" 0 "No_Fault" ;
VAL_ 2566848677 BMS5_ADB_Batt_PS1_short_circuit 1 "Fault_Present" 0 "No_Fault" ;
VAL_ 2566848677 BMS5_ADB_Batt_OS_8_sleep_mode 1 "Sleep_pending" 0 "Awake" ;
VAL_ 2566848677 BMS5_ADB_Batt_OS_7_emerg_used 1 "used" 0 "never_used" ;
VAL_ 2566848677 BMS5_ADB_Batt_OS_6_emergency 1 "Active" 0 "NotActive" ;
VAL_ 2566848677 BMS5_ADB_Batt_OS_45_charge_level 3 "100%" 2 "50%" 1 "25%" 0 "OFF" ;
VAL_ 2566848677 BMS5_ADB_Batt_OS_3_charge_cont 1 "ON" 0 "OFF" ;
VAL_ 2566848677 BMS5_ADB_Batt_OS_2_heater_cont 1 "ON" 0 "OFF" ;
VAL_ 2566848677 BMS5_ADB_Batt_OS_1_master_prot 1 "Protect" 0 "OFF" ;
VAL_ 2566849958 BMS6_ADB_BatSumS_State_of_Health 3 "Health_is_wrong" 2 "Health_is_good" 1 "Health_is_medium" 0 "Health_is_poor" ;
VAL_ 2566849958 BMS6_ADB_BatSumS_Temp_Alarm 3 "Wrong_Temperature_Alarm" 2 "High_Temperature_Alarm" 1 "Low_Temperature_Alarm" 0 "No_fault" ;
VAL_ 2566849958 BMS6_ADB_BatSumS_DischargeDis 1 "Discharge_Disable" 0 "Discharge_Enable" ;
VAL_ 2566849958 BMS6_ADB_BatSumS_ChargingDisable 1 "Charging_Disable" 0 "Charging_Enable" ;
VAL_ 2566849958 BMS6_ADB_BatSumS_HeaterEnabled 1 "Heater_Enabled" 0 "Heater_Disabled" ;
VAL_ 2566849958 BMS6_ADB_BatSumS_BypassEnabled 1 "Bypass_Enabled" 0 "Bypass_Disabled" ;
VAL_ 2566849958 BMS6_ADB_BatSumS_Voltage_Alarm 1 "Active" 0 "NotActive" ;
VAL_ 2566851238 BMS6_ADB_M3_Module_StateOfHealth 3 "Health_is_wrong" 2 "Health_is_good" 1 "Health_is_medium" 0 "Health_is_poor" ;
VAL_ 2566851238 BMS6_ADB_M3_DiscProtectTrigg 1 "Fault_Present" 0 "No_Fault" ;
VAL_ 2566851238 BMS6_ADB_M3_ChargeProtectTrigg 1 "Fault_Present" 0 "No_Fault" ;
VAL_ 2566851238 BMS6_ADB_M3_ModulesMissingFailed 1 "Fault_Present" 0 "No_Fault" ;
VAL_ 2566851238 BMS6_ADB_M3_OverTemp_detect 1 "Fault_Present" 0 "No_Fault" ;
VAL_ 2566851238 BMS6_ADB_M3_UnderVoltage_detect 1 "Fault_Present" 0 "No_Fault" ;
VAL_ 2566851238 BMS6_ADB_M3_OverVoltage_detected 1 "Fault_Present" 0 "No_Fault" ;
VAL_ 2566851238 BMS6_ADB_M3_Overload_detected 1 "Fault_Present" 0 "No_Fault" ;
VAL_ 2566851238 BMS6_ADB_M3_ShortCircuit_detect 1 "Fault_Present" 0 "No_Fault" ;
VAL_ 2566850982 BMS6_ADB_M2_Module_StateOfHealth 3 "Health_is_wrong" 2 "Health_is_good" 1 "Health_is_medium" 0 "Health_is_poor" ;
VAL_ 2566850982 BMS6_ADB_M2_DiscProtectTrigg 1 "Fault_Present" 0 "No_Fault" ;
VAL_ 2566850982 BMS6_ADB_M2_ChargeProtectTrigg 1 "Fault_Present" 0 "No_Fault" ;
VAL_ 2566850982 BMS6_ADB_M2_ModulesMissingFailed 1 "Fault_Present" 0 "No_Fault" ;
VAL_ 2566850982 BMS6_ADB_M2_OverTemp_detect 1 "Fault_Present" 0 "No_Fault" ;
VAL_ 2566850982 BMS6_ADB_M2_UnderVoltage_detect 1 "Fault_Present" 0 "No_Fault" ;
VAL_ 2566850982 BMS6_ADB_M2_OverVoltage_detected 1 "Fault_Present" 0 "No_Fault" ;
VAL_ 2566850982 BMS6_ADB_M2_Overload_detected 1 "Fault_Present" 0 "No_Fault" ;
VAL_ 2566850982 BMS6_ADB_M2_ShortCircuit_detect 1 "Fault_Present" 0 "No_Fault" ;
VAL_ 2566850726 BMS6_ADB_M1_Module_StateOfHealth 3 "Health_is_wrong" 2 "Health_is_good" 1 "Health_is_medium" 0 "Health_is_poor" ;
VAL_ 2566850726 BMS6_ADB_M1_DiscProtectTrigg 1 "Fault_Present" 0 "No_Fault" ;
VAL_ 2566850726 BMS6_ADB_M1_ChargeProtectTrigg 1 "Fault_Present" 0 "No_Fault" ;
VAL_ 2566850726 BMS6_ADB_M1_ModulesMissingFailed 1 "Fault_Present" 0 "No_Fault" ;
VAL_ 2566850726 BMS6_ADB_M1_OverTemp_detect 1 "Fault_Present" 0 "No_Fault" ;
VAL_ 2566850726 BMS6_ADB_M1_UnderVoltage_detect 1 "Fault_Present" 0 "No_Fault" ;
VAL_ 2566850726 BMS6_ADB_M1_OverVoltage_detected 1 "Fault_Present" 0 "No_Fault" ;
VAL_ 2566850726 BMS6_ADB_M1_Overload_detected 1 "Fault_Present" 0 "No_Fault" ;
VAL_ 2566850726 BMS6_ADB_M1_ShortCircuit_detect 1 "Fault_Present" 0 "No_Fault" ;
VAL_ 2566848934 BMS6_ADB_Overall_10_alarm 1 "Alarm_ON" 0 "Alarm_OFF" ;
VAL_ 2566848934 BMS6_ADB_Silent_Watch_20_alarm 1 "Alarm_ON" 0 "Alarm_OFF" ;
VAL_ 2566848934 BMS6_ADB_EngStartCapacity_alarm 1 "Alarm_ON" 0 "Alarm_OFF" ;
VAL_ 2566848678 BMS6_ADB_Batt_StsOfHealth 3 "Health_is_wrong" 2 "Health_is_good" 1 "Health_is_medium" 0 "Health_is_poor" ;
VAL_ 2566848678 BMS6_ADB_Batt_PS8_discharge_prot 1 "Fault_Present" 0 "No_Fault" ;
VAL_ 2566848678 BMS6_ADB_Batt_PS7_charge_prot 1 "Fault_Present" 0 "No_Fault" ;
VAL_ 2566848678 BMS6_ADB_Batt_PS6_mod_failed 1 "Fault_Present" 0 "No_Fault" ;
VAL_ 2566848678 BMS6_ADB_Batt_PS5_over_temp 1 "Fault_Present" 0 "No_Fault" ;
VAL_ 2566848678 BMS6_ADB_Batt_PS4_under_voltage 1 "Fault_Present" 0 "No_Fault" ;
VAL_ 2566848678 BMS6_ADB_Batt_PS3_over_voltage 1 "Fault_Present" 0 "No_Fault" ;
VAL_ 2566848678 BMS6_ADB_Batt_PS2_overload 1 "Fault_Present" 0 "No_Fault" ;
VAL_ 2566848678 BMS6_ADB_Batt_PS1_short_circuit 1 "Fault_Present" 0 "No_Fault" ;
VAL_ 2566848678 BMS6_ADB_Batt_OS_8_sleep_mode 1 "Sleep_pending" 0 "Awake" ;
VAL_ 2566848678 BMS6_ADB_Batt_OS_7_emerg_used 1 "used" 0 "never_used" ;
VAL_ 2566848678 BMS6_ADB_Batt_OS_6_emergency 1 "Active" 0 "NotActive" ;
VAL_ 2566848678 BMS6_ADB_Batt_OS_45_charge_level 3 "100%" 2 "50%" 1 "25%" 0 "OFF" ;
VAL_ 2566848678 BMS6_ADB_Batt_OS_3_charge_cont 1 "ON" 0 "OFF" ;
VAL_ 2566848678 BMS6_ADB_Batt_OS_2_heater_cont 1 "ON" 0 "OFF" ;
VAL_ 2566848678 BMS6_ADB_Batt_OS_1_master_prot 1 "Protect" 0 "OFF" ;
